VERSION "HNPBNNNYNNNNNNNNNNNNNNNNNNNNNNNNYNYYYYYYYY>4>%%%/4>'%**4YYY///"

NS_ :

BS_:

BU_: TESTER TCU BMU2 CSM CMU_TEST CMU_12 CMU_11 CMU_10 CMU_09 CMU_08 CMU_07 CMU_06 CMU_05 CMU_04 CMU_03 CMU_02 CMU_01 CMU_00 BMU

BO_ 1713 CMU_RS1_11: 8 CMU_11
 SG_ MODULE_TEMP_06_11 : 56|8@1+ (1,-70) [-70|130] "°C"  TCU,BMU
 SG_ MODULE_TEMP_05_11 : 48|8@1+ (1,-70) [-70|130] "°C"  TCU,BMU2,BMU
 SG_ MODULE_TEMP_04_11 : 40|8@1+ (1,-70) [-70|130] "°C"  TCU,BMU2,BMU
 SG_ MODULE_TEMP_03_11 : 32|8@1+ (1,-70) [-70|130] "°C"  TCU,BMU2,BMU
 SG_ MODULE_TEMP_02_11 : 24|8@1+ (1,-70) [-70|130] "°C"  TCU,BMU2,BMU
 SG_ MODULE_TEMP_01_11 : 16|8@1+ (1,-70) [-70|130] "°C"  TCU,BMU2,BMU
 SG_ NUM_TABLE_VALUE_11 : 12|4@1+ (1,0) [0|0] ""  BMU
 SG_ BLC_DRV_STAT_12_11 : 11|1@1+ (1,0) [0|0] ""  TCU,BMU
 SG_ BLC_DRV_STAT_11_11 : 10|1@1+ (1,0) [0|0] ""  TCU,BMU
 SG_ BLC_DRV_STAT_10_11 : 9|1@1+ (1,0) [0|0] ""  TCU,BMU
 SG_ BLC_DRV_STAT_09_11 : 8|1@1+ (1,0) [0|0] ""  TCU,BMU
 SG_ BLC_DRV_STAT_08_11 : 7|1@1+ (1,0) [0|0] ""  TCU,BMU
 SG_ BLC_DRV_STAT_07_11 : 6|1@1+ (1,0) [0|0] ""  TCU,BMU
 SG_ BLC_DRV_STAT_06_11 : 5|1@1+ (1,0) [0|0] ""  TCU,BMU
 SG_ BLC_DRV_STAT_05_11 : 4|1@1+ (1,0) [0|0] ""  TCU,BMU
 SG_ BLC_DRV_STAT_04_11 : 3|1@1+ (1,0) [0|0] ""  TCU,BMU
 SG_ BLC_DRV_STAT_03_11 : 2|1@1+ (1,0) [0|0] ""  TCU,BMU
 SG_ BLC_DRV_STAT_02_11 : 1|1@1+ (1,0) [0|0] ""  TCU,BMU
 SG_ BLC_DRV_STAT_01_11 : 0|1@1+ (1,0) [0|0] ""  TCU,BMU

BO_ 1697 CMU_RS1_10: 8 CMU_10
 SG_ MODULE_TEMP_06_10 : 56|8@1+ (1,-70) [-70|130] "°C"  TCU,BMU
 SG_ MODULE_TEMP_05_10 : 48|8@1+ (1,-70) [-70|130] "°C"  TCU,BMU2,BMU
 SG_ MODULE_TEMP_04_10 : 40|8@1+ (1,-70) [-70|130] "°C"  TCU,BMU2,BMU
 SG_ MODULE_TEMP_03_10 : 32|8@1+ (1,-70) [-70|130] "°C"  TCU,BMU2,BMU
 SG_ MODULE_TEMP_02_10 : 24|8@1+ (1,-70) [-70|130] "°C"  TCU,BMU2,BMU
 SG_ MODULE_TEMP_01_10 : 16|8@1+ (1,-70) [-70|130] "°C"  TCU,BMU2,BMU
 SG_ NUM_TABLE_VALUE_10 : 12|4@1+ (1,0) [0|0] ""  BMU
 SG_ BLC_DRV_STAT_12_10 : 11|1@1+ (1,0) [0|0] ""  TCU,BMU
 SG_ BLC_DRV_STAT_11_10 : 10|1@1+ (1,0) [0|0] ""  TCU,BMU
 SG_ BLC_DRV_STAT_10_10 : 9|1@1+ (1,0) [0|0] ""  TCU,BMU
 SG_ BLC_DRV_STAT_09_10 : 8|1@1+ (1,0) [0|0] ""  TCU,BMU
 SG_ BLC_DRV_STAT_08_10 : 7|1@1+ (1,0) [0|0] ""  TCU,BMU
 SG_ BLC_DRV_STAT_07_10 : 6|1@1+ (1,0) [0|0] ""  TCU,BMU
 SG_ BLC_DRV_STAT_06_10 : 5|1@1+ (1,0) [0|0] ""  TCU,BMU
 SG_ BLC_DRV_STAT_05_10 : 4|1@1+ (1,0) [0|0] ""  TCU,BMU
 SG_ BLC_DRV_STAT_04_10 : 3|1@1+ (1,0) [0|0] ""  TCU,BMU
 SG_ BLC_DRV_STAT_03_10 : 2|1@1+ (1,0) [0|0] ""  TCU,BMU
 SG_ BLC_DRV_STAT_02_10 : 1|1@1+ (1,0) [0|0] ""  TCU,BMU
 SG_ BLC_DRV_STAT_01_10 : 0|1@1+ (1,0) [0|0] ""  TCU,BMU

BO_ 1681 CMU_RS1_09: 8 CMU_09
 SG_ MODULE_TEMP_06_09 : 56|8@1+ (1,-70) [-70|130] "°C"  TCU,BMU
 SG_ MODULE_TEMP_05_09 : 48|8@1+ (1,-70) [-70|130] "°C"  TCU,BMU2,BMU
 SG_ MODULE_TEMP_04_09 : 40|8@1+ (1,-70) [-70|130] "°C"  TCU,BMU2,BMU
 SG_ MODULE_TEMP_03_09 : 32|8@1+ (1,-70) [-70|130] "°C"  TCU,BMU2,BMU
 SG_ MODULE_TEMP_02_09 : 24|8@1+ (1,-70) [-70|130] "°C"  TCU,BMU2,BMU
 SG_ MODULE_TEMP_01_09 : 16|8@1+ (1,-70) [-70|130] "°C"  TCU,BMU2,BMU
 SG_ NUM_TABLE_VALUE_09 : 12|4@1+ (1,0) [0|0] ""  BMU
 SG_ BLC_DRV_STAT_12_09 : 11|1@1+ (1,0) [0|0] ""  TCU,BMU
 SG_ BLC_DRV_STAT_11_09 : 10|1@1+ (1,0) [0|0] ""  TCU,BMU
 SG_ BLC_DRV_STAT_10_09 : 9|1@1+ (1,0) [0|0] ""  TCU,BMU
 SG_ BLC_DRV_STAT_09_09 : 8|1@1+ (1,0) [0|0] ""  TCU,BMU
 SG_ BLC_DRV_STAT_08_09 : 7|1@1+ (1,0) [0|0] ""  TCU,BMU
 SG_ BLC_DRV_STAT_07_09 : 6|1@1+ (1,0) [0|0] ""  TCU,BMU
 SG_ BLC_DRV_STAT_06_09 : 5|1@1+ (1,0) [0|0] ""  TCU,BMU
 SG_ BLC_DRV_STAT_05_09 : 4|1@1+ (1,0) [0|0] ""  TCU,BMU
 SG_ BLC_DRV_STAT_04_09 : 3|1@1+ (1,0) [0|0] ""  TCU,BMU
 SG_ BLC_DRV_STAT_03_09 : 2|1@1+ (1,0) [0|0] ""  TCU,BMU
 SG_ BLC_DRV_STAT_02_09 : 1|1@1+ (1,0) [0|0] ""  TCU,BMU
 SG_ BLC_DRV_STAT_01_09 : 0|1@1+ (1,0) [0|0] ""  TCU,BMU

BO_ 1665 CMU_RS1_08: 8 CMU_08
 SG_ MODULE_TEMP_06_08 : 56|8@1+ (1,-70) [-70|130] "°C"  TCU,BMU
 SG_ MODULE_TEMP_05_08 : 48|8@1+ (1,-70) [-70|130] "°C"  TCU,BMU2,BMU
 SG_ MODULE_TEMP_04_08 : 40|8@1+ (1,-70) [-70|130] "°C"  TCU,BMU2,BMU
 SG_ MODULE_TEMP_03_08 : 32|8@1+ (1,-70) [-70|130] "°C"  TCU,BMU2,BMU
 SG_ MODULE_TEMP_02_08 : 24|8@1+ (1,-70) [-70|130] "°C"  TCU,BMU2,BMU
 SG_ MODULE_TEMP_01_08 : 16|8@1+ (1,-70) [-70|130] "°C"  TCU,BMU2,BMU
 SG_ NUM_TABLE_VALUE_08 : 12|4@1+ (1,0) [0|0] ""  BMU
 SG_ BLC_DRV_STAT_12_08 : 11|1@1+ (1,0) [0|0] ""  TCU,BMU
 SG_ BLC_DRV_STAT_11_08 : 10|1@1+ (1,0) [0|0] ""  TCU,BMU
 SG_ BLC_DRV_STAT_10_08 : 9|1@1+ (1,0) [0|0] ""  TCU,BMU
 SG_ BLC_DRV_STAT_09_08 : 8|1@1+ (1,0) [0|0] ""  TCU,BMU
 SG_ BLC_DRV_STAT_08_08 : 7|1@1+ (1,0) [0|0] ""  TCU,BMU
 SG_ BLC_DRV_STAT_07_08 : 6|1@1+ (1,0) [0|0] ""  TCU,BMU
 SG_ BLC_DRV_STAT_06_08 : 5|1@1+ (1,0) [0|0] ""  TCU,BMU
 SG_ BLC_DRV_STAT_05_08 : 4|1@1+ (1,0) [0|0] ""  TCU,BMU
 SG_ BLC_DRV_STAT_04_08 : 3|1@1+ (1,0) [0|0] ""  TCU,BMU
 SG_ BLC_DRV_STAT_03_08 : 2|1@1+ (1,0) [0|0] ""  TCU,BMU
 SG_ BLC_DRV_STAT_02_08 : 1|1@1+ (1,0) [0|0] ""  TCU,BMU
 SG_ BLC_DRV_STAT_01_08 : 0|1@1+ (1,0) [0|0] ""  TCU,BMU

BO_ 1649 CMU_RS1_07: 8 CMU_07
 SG_ MODULE_TEMP_06_07 : 56|8@1+ (1,-70) [-70|130] "°C"  TCU,BMU
 SG_ MODULE_TEMP_05_07 : 48|8@1+ (1,-70) [-70|130] "°C"  TCU,BMU2,BMU
 SG_ MODULE_TEMP_04_07 : 40|8@1+ (1,-70) [-70|130] "°C"  TCU,BMU2,BMU
 SG_ MODULE_TEMP_03_07 : 32|8@1+ (1,-70) [-70|130] "°C"  TCU,BMU2,BMU
 SG_ MODULE_TEMP_02_07 : 24|8@1+ (1,-70) [-70|130] "°C"  TCU,BMU2,BMU
 SG_ MODULE_TEMP_01_07 : 16|8@1+ (1,-70) [-70|130] "°C"  TCU,BMU2,BMU
 SG_ NUM_TABLE_VALUE_07 : 12|4@1+ (1,0) [0|0] ""  BMU
 SG_ BLC_DRV_STAT_12_07 : 11|1@1+ (1,0) [0|0] ""  TCU,BMU
 SG_ BLC_DRV_STAT_11_07 : 10|1@1+ (1,0) [0|0] ""  TCU,BMU
 SG_ BLC_DRV_STAT_10_07 : 9|1@1+ (1,0) [0|0] ""  TCU,BMU
 SG_ BLC_DRV_STAT_09_07 : 8|1@1+ (1,0) [0|0] ""  TCU,BMU
 SG_ BLC_DRV_STAT_08_07 : 7|1@1+ (1,0) [0|0] ""  TCU,BMU
 SG_ BLC_DRV_STAT_07_07 : 6|1@1+ (1,0) [0|0] ""  TCU,BMU
 SG_ BLC_DRV_STAT_06_07 : 5|1@1+ (1,0) [0|0] ""  TCU,BMU
 SG_ BLC_DRV_STAT_05_07 : 4|1@1+ (1,0) [0|0] ""  TCU,BMU
 SG_ BLC_DRV_STAT_04_07 : 3|1@1+ (1,0) [0|0] ""  TCU,BMU
 SG_ BLC_DRV_STAT_03_07 : 2|1@1+ (1,0) [0|0] ""  TCU,BMU
 SG_ BLC_DRV_STAT_02_07 : 1|1@1+ (1,0) [0|0] ""  TCU,BMU
 SG_ BLC_DRV_STAT_01_07 : 0|1@1+ (1,0) [0|0] ""  TCU,BMU

BO_ 1633 CMU_RS1_06: 8 CMU_06
 SG_ MODULE_TEMP_06_06 : 56|8@1+ (1,-70) [-70|130] "°C"  TCU,BMU
 SG_ MODULE_TEMP_05_06 : 48|8@1+ (1,-70) [-70|130] "°C"  TCU,BMU
 SG_ MODULE_TEMP_04_06 : 40|8@1+ (1,-70) [-70|130] "°C"  TCU,BMU
 SG_ MODULE_TEMP_03_06 : 32|8@1+ (1,-70) [-70|130] "°C"  TCU,BMU
 SG_ MODULE_TEMP_02_06 : 24|8@1+ (1,-70) [-70|130] "°C"  TCU,BMU
 SG_ MODULE_TEMP_01_06 : 16|8@1+ (1,-70) [-70|130] "°C"  TCU,BMU
 SG_ NUM_TABLE_VALUE_06 : 12|4@1+ (1,0) [0|0] ""  BMU
 SG_ BLC_DRV_STAT_12_06 : 11|1@1+ (1,0) [0|0] ""  TCU,BMU
 SG_ BLC_DRV_STAT_11_06 : 10|1@1+ (1,0) [0|0] ""  TCU,BMU
 SG_ BLC_DRV_STAT_10_06 : 9|1@1+ (1,0) [0|0] ""  TCU,BMU
 SG_ BLC_DRV_STAT_09_06 : 8|1@1+ (1,0) [0|0] ""  TCU,BMU
 SG_ BLC_DRV_STAT_08_06 : 7|1@1+ (1,0) [0|0] ""  TCU,BMU
 SG_ BLC_DRV_STAT_07_06 : 6|1@1+ (1,0) [0|0] ""  TCU,BMU
 SG_ BLC_DRV_STAT_06_06 : 5|1@1+ (1,0) [0|0] ""  TCU,BMU
 SG_ BLC_DRV_STAT_05_06 : 4|1@1+ (1,0) [0|0] ""  TCU,BMU
 SG_ BLC_DRV_STAT_04_06 : 3|1@1+ (1,0) [0|0] ""  TCU,BMU
 SG_ BLC_DRV_STAT_03_06 : 2|1@1+ (1,0) [0|0] ""  TCU,BMU
 SG_ BLC_DRV_STAT_02_06 : 1|1@1+ (1,0) [0|0] ""  TCU,BMU
 SG_ BLC_DRV_STAT_01_06 : 0|1@1+ (1,0) [0|0] ""  TCU,BMU

BO_ 1617 CMU_RS1_05: 8 CMU_05
 SG_ MODULE_TEMP_06_05 : 56|8@1+ (1,-70) [-70|130] "°C"  TCU,BMU
 SG_ MODULE_TEMP_05_05 : 48|8@1+ (1,-70) [-70|130] "°C"  TCU,BMU2,BMU
 SG_ MODULE_TEMP_04_05 : 40|8@1+ (1,-70) [-70|130] "°C"  TCU,BMU2,BMU
 SG_ MODULE_TEMP_03_05 : 32|8@1+ (1,-70) [-70|130] "°C"  TCU,BMU2,BMU
 SG_ MODULE_TEMP_02_05 : 24|8@1+ (1,-70) [-70|130] "°C"  TCU,BMU2,BMU
 SG_ MODULE_TEMP_01_05 : 16|8@1+ (1,-70) [-70|130] "°C"  TCU,BMU2,BMU
 SG_ NUM_TABLE_VALUE_05 : 12|4@1+ (1,0) [0|0] ""  BMU
 SG_ BLC_DRV_STAT_12_05 : 11|1@1+ (1,0) [0|0] ""  TCU,BMU
 SG_ BLC_DRV_STAT_11_05 : 10|1@1+ (1,0) [0|0] ""  TCU,BMU
 SG_ BLC_DRV_STAT_10_05 : 9|1@1+ (1,0) [0|0] ""  TCU,BMU
 SG_ BLC_DRV_STAT_09_05 : 8|1@1+ (1,0) [0|0] ""  TCU,BMU
 SG_ BLC_DRV_STAT_08_05 : 7|1@1+ (1,0) [0|0] ""  TCU,BMU
 SG_ BLC_DRV_STAT_07_05 : 6|1@1+ (1,0) [0|0] ""  TCU,BMU
 SG_ BLC_DRV_STAT_06_05 : 5|1@1+ (1,0) [0|0] ""  TCU,BMU
 SG_ BLC_DRV_STAT_05_05 : 4|1@1+ (1,0) [0|0] ""  TCU,BMU
 SG_ BLC_DRV_STAT_04_05 : 3|1@1+ (1,0) [0|0] ""  TCU,BMU
 SG_ BLC_DRV_STAT_03_05 : 2|1@1+ (1,0) [0|0] ""  TCU,BMU
 SG_ BLC_DRV_STAT_02_05 : 1|1@1+ (1,0) [0|0] ""  TCU,BMU
 SG_ BLC_DRV_STAT_01_05 : 0|1@1+ (1,0) [0|0] ""  TCU,BMU

BO_ 1601 CMU_RS1_04: 8 CMU_04
 SG_ MODULE_TEMP_06_04 : 56|8@1+ (1,-70) [-70|130] "°C"  TCU,BMU
 SG_ MODULE_TEMP_05_04 : 48|8@1+ (1,-70) [-70|130] "°C"  TCU,BMU2,BMU
 SG_ MODULE_TEMP_04_04 : 40|8@1+ (1,-70) [-70|130] "°C"  TCU,BMU2,BMU
 SG_ MODULE_TEMP_03_04 : 32|8@1+ (1,-70) [-70|130] "°C"  TCU,BMU2,BMU
 SG_ MODULE_TEMP_02_04 : 24|8@1+ (1,-70) [-70|130] "°C"  TCU,BMU2,BMU
 SG_ MODULE_TEMP_01_04 : 16|8@1+ (1,-70) [-70|130] "°C"  TCU,BMU2,BMU
 SG_ NUM_TABLE_VALUE_04 : 12|4@1+ (1,0) [0|0] ""  BMU
 SG_ BLC_DRV_STAT_12_04 : 11|1@1+ (1,0) [0|0] ""  TCU,BMU
 SG_ BLC_DRV_STAT_11_04 : 10|1@1+ (1,0) [0|0] ""  TCU,BMU
 SG_ BLC_DRV_STAT_10_04 : 9|1@1+ (1,0) [0|0] ""  TCU,BMU
 SG_ BLC_DRV_STAT_09_04 : 8|1@1+ (1,0) [0|0] ""  TCU,BMU
 SG_ BLC_DRV_STAT_08_04 : 7|1@1+ (1,0) [0|0] ""  TCU,BMU
 SG_ BLC_DRV_STAT_07_04 : 6|1@1+ (1,0) [0|0] ""  TCU,BMU
 SG_ BLC_DRV_STAT_06_04 : 5|1@1+ (1,0) [0|0] ""  TCU,BMU
 SG_ BLC_DRV_STAT_05_04 : 4|1@1+ (1,0) [0|0] ""  TCU,BMU
 SG_ BLC_DRV_STAT_04_04 : 3|1@1+ (1,0) [0|0] ""  TCU,BMU
 SG_ BLC_DRV_STAT_03_04 : 2|1@1+ (1,0) [0|0] ""  TCU,BMU
 SG_ BLC_DRV_STAT_02_04 : 1|1@1+ (1,0) [0|0] ""  TCU,BMU
 SG_ BLC_DRV_STAT_01_04 : 0|1@1+ (1,0) [0|0] ""  TCU,BMU

BO_ 1585 CMU_RS1_03: 8 CMU_03
 SG_ MODULE_TEMP_06_03 : 56|8@1+ (1,-70) [-70|130] "°C"  TCU,BMU
 SG_ MODULE_TEMP_05_03 : 48|8@1+ (1,-70) [-70|130] "°C"  TCU,BMU2,BMU
 SG_ MODULE_TEMP_04_03 : 40|8@1+ (1,-70) [-70|130] "°C"  TCU,BMU2,BMU
 SG_ MODULE_TEMP_03_03 : 32|8@1+ (1,-70) [-70|130] "°C"  TCU,BMU2,BMU
 SG_ MODULE_TEMP_02_03 : 24|8@1+ (1,-70) [-70|130] "°C"  TCU,BMU2,BMU
 SG_ MODULE_TEMP_01_03 : 16|8@1+ (1,-70) [-70|130] "°C"  TCU,BMU2,BMU
 SG_ NUM_TABLE_VALUE_03 : 12|4@1+ (1,0) [0|0] ""  BMU
 SG_ BLC_DRV_STAT_12_03 : 11|1@1+ (1,0) [0|0] ""  TCU,BMU
 SG_ BLC_DRV_STAT_11_03 : 10|1@1+ (1,0) [0|0] ""  TCU,BMU
 SG_ BLC_DRV_STAT_10_03 : 9|1@1+ (1,0) [0|0] ""  TCU,BMU
 SG_ BLC_DRV_STAT_09_03 : 8|1@1+ (1,0) [0|0] ""  TCU,BMU
 SG_ BLC_DRV_STAT_08_03 : 7|1@1+ (1,0) [0|0] ""  TCU,BMU
 SG_ BLC_DRV_STAT_07_03 : 6|1@1+ (1,0) [0|0] ""  TCU,BMU
 SG_ BLC_DRV_STAT_06_03 : 5|1@1+ (1,0) [0|0] ""  TCU,BMU
 SG_ BLC_DRV_STAT_05_03 : 4|1@1+ (1,0) [0|0] ""  TCU,BMU
 SG_ BLC_DRV_STAT_04_03 : 3|1@1+ (1,0) [0|0] ""  TCU,BMU
 SG_ BLC_DRV_STAT_03_03 : 2|1@1+ (1,0) [0|0] ""  TCU,BMU
 SG_ BLC_DRV_STAT_02_03 : 1|1@1+ (1,0) [0|0] ""  TCU,BMU
 SG_ BLC_DRV_STAT_01_03 : 0|1@1+ (1,0) [0|0] ""  TCU,BMU

BO_ 1569 CMU_RS1_02: 8 CMU_02
 SG_ MODULE_TEMP_06_02 : 56|8@1+ (1,-70) [-70|130] "°C"  TCU,BMU
 SG_ MODULE_TEMP_05_02 : 48|8@1+ (1,-70) [-70|130] "°C"  TCU,BMU2,BMU
 SG_ MODULE_TEMP_04_02 : 40|8@1+ (1,-70) [-70|130] "°C"  TCU,BMU2,BMU
 SG_ MODULE_TEMP_03_02 : 32|8@1+ (1,-70) [-70|130] "°C"  TCU,BMU2,BMU
 SG_ MODULE_TEMP_02_02 : 24|8@1+ (1,-70) [-70|130] "°C"  TCU,BMU2,BMU
 SG_ MODULE_TEMP_01_02 : 16|8@1+ (1,-70) [-70|130] "°C"  TCU,BMU2,BMU
 SG_ NUM_TABLE_VALUE_02 : 12|4@1+ (1,0) [0|0] ""  BMU
 SG_ BLC_DRV_STAT_12_02 : 11|1@1+ (1,0) [0|0] ""  TCU,BMU
 SG_ BLC_DRV_STAT_11_02 : 10|1@1+ (1,0) [0|0] ""  TCU,BMU
 SG_ BLC_DRV_STAT_10_02 : 9|1@1+ (1,0) [0|0] ""  TCU,BMU
 SG_ BLC_DRV_STAT_09_02 : 8|1@1+ (1,0) [0|0] ""  TCU,BMU
 SG_ BLC_DRV_STAT_08_02 : 7|1@1+ (1,0) [0|0] ""  TCU,BMU
 SG_ BLC_DRV_STAT_07_02 : 6|1@1+ (1,0) [0|0] ""  TCU,BMU
 SG_ BLC_DRV_STAT_06_02 : 5|1@1+ (1,0) [0|0] ""  TCU,BMU
 SG_ BLC_DRV_STAT_05_02 : 4|1@1+ (1,0) [0|0] ""  TCU,BMU
 SG_ BLC_DRV_STAT_04_02 : 3|1@1+ (1,0) [0|0] ""  TCU,BMU
 SG_ BLC_DRV_STAT_03_02 : 2|1@1+ (1,0) [0|0] ""  TCU,BMU
 SG_ BLC_DRV_STAT_02_02 : 1|1@1+ (1,0) [0|0] ""  TCU,BMU
 SG_ BLC_DRV_STAT_01_02 : 0|1@1+ (1,0) [0|0] ""  TCU,BMU

BO_ 1553 CMU_RS1_01: 8 CMU_01
 SG_ MODULE_TEMP_06_01 : 56|8@1+ (1,-70) [-70|130] "°C"  TCU,BMU
 SG_ MODULE_TEMP_05_01 : 48|8@1+ (1,-70) [-70|130] "°C"  TCU,BMU2,BMU
 SG_ MODULE_TEMP_04_01 : 40|8@1+ (1,-70) [-70|130] "°C"  TCU,BMU2,BMU
 SG_ MODULE_TEMP_03_01 : 32|8@1+ (1,-70) [-70|130] "°C"  TCU,BMU2,BMU
 SG_ MODULE_TEMP_02_01 : 24|8@1+ (1,-70) [-70|130] "°C"  TCU,BMU2,BMU
 SG_ MODULE_TEMP_01_01 : 16|8@1+ (1,-70) [-70|130] "°C"  TCU,BMU2,BMU
 SG_ NUM_TABLE_VALUE_01 : 12|4@1+ (1,0) [0|0] ""  BMU
 SG_ BLC_DRV_STAT_12_01 : 11|1@1+ (1,0) [0|0] ""  TCU,BMU
 SG_ BLC_DRV_STAT_11_01 : 10|1@1+ (1,0) [0|0] ""  TCU,BMU
 SG_ BLC_DRV_STAT_10_01 : 9|1@1+ (1,0) [0|0] ""  TCU,BMU
 SG_ BLC_DRV_STAT_09_01 : 8|1@1+ (1,0) [0|0] ""  TCU,BMU
 SG_ BLC_DRV_STAT_08_01 : 7|1@1+ (1,0) [0|0] ""  TCU,BMU
 SG_ BLC_DRV_STAT_07_01 : 6|1@1+ (1,0) [0|0] ""  TCU,BMU
 SG_ BLC_DRV_STAT_06_01 : 5|1@1+ (1,0) [0|0] ""  TCU,BMU
 SG_ BLC_DRV_STAT_05_01 : 4|1@1+ (1,0) [0|0] ""  TCU,BMU
 SG_ BLC_DRV_STAT_04_01 : 3|1@1+ (1,0) [0|0] ""  TCU,BMU
 SG_ BLC_DRV_STAT_03_01 : 2|1@1+ (1,0) [0|0] ""  TCU,BMU
 SG_ BLC_DRV_STAT_02_01 : 1|1@1+ (1,0) [0|0] ""  TCU,BMU
 SG_ BLC_DRV_STAT_01_01 : 0|1@1+ (1,0) [0|0] ""  TCU,BMU

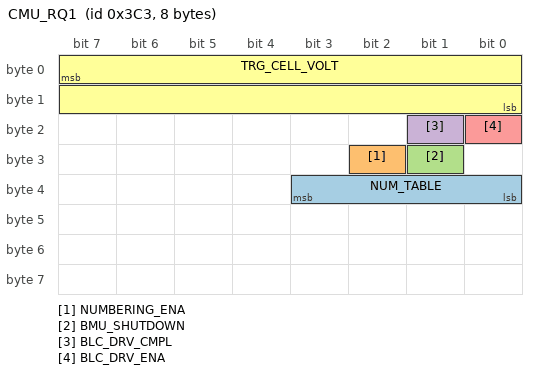
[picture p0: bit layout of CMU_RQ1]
BO_ 963 CMU_RQ1: 8 BMU
 SG_ NUM_TABLE : 32|4@1+ (1,0) [0|0] ""  CMU_00,CMU_12,CMU_11,CMU_10,CMU_09,CMU_08,CMU_07,CMU_06,CMU_05,CMU_04,CMU_03,CMU_02,CMU_01
 SG_ NUMBERING_ENA : 26|1@1+ (1,0) [0|0] ""  CMU_00,CMU_12,CMU_11,CMU_10,CMU_09,CMU_08,CMU_07,CMU_06,CMU_05,CMU_04,CMU_03,CMU_02,CMU_01
 SG_ BMU_SHUTDOWN : 25|1@1+ (1,0) [0|0] ""  TCU,CMU_12,CMU_11,CMU_10,CMU_09,CMU_08,CMU_07,CMU_06,CMU_05,CMU_04,CMU_03,CMU_02,CMU_01
 SG_ BLC_DRV_CMPL : 17|1@1+ (1,0) [0|0] ""  TCU,CMU_12,CMU_11,CMU_10,CMU_09,CMU_08,CMU_07,CMU_06,CMU_05,CMU_04,CMU_03,CMU_02,CMU_01
 SG_ BLC_DRV_ENA : 16|1@1+ (1,0) [0|0] ""  TCU,CMU_12,CMU_11,CMU_10,CMU_09,CMU_08,CMU_07,CMU_06,CMU_05,CMU_04,CMU_03,CMU_02,CMU_01
 SG_ TRG_CELL_VOLT : 7|16@0+ (0.001,0) [0|5] "V"  TCU,CMU_12,CMU_11,CMU_10,CMU_09,CMU_08,CMU_07,CMU_06,CMU_05,CMU_04,CMU_03,CMU_02,CMU_01

CM_ SG_ 1713 MODULE_TEMP_06_11 "Module temperature06";
CM_ SG_ 1713 MODULE_TEMP_05_11 "Module temperature05";
CM_ SG_ 1713 MODULE_TEMP_04_11 "Module temperature04";
CM_ SG_ 1713 MODULE_TEMP_03_11 "Module temperature03";
CM_ SG_ 1713 MODULE_TEMP_02_11 "Module temperature02";
CM_ SG_ 1713 MODULE_TEMP_01_11 "Module temperature01";
CM_ SG_ 1713 NUM_TABLE_VALUE_11 "Stored Automatic numbering table";
CM_ SG_ 1713 BLC_DRV_STAT_12_11 "CELL_12 Balancer drive status";
CM_ SG_ 1713 BLC_DRV_STAT_11_11 "CELL_11 Balancer drive status";
CM_ SG_ 1713 BLC_DRV_STAT_10_11 "CELL_10 Balancer drive status";
CM_ SG_ 1713 BLC_DRV_STAT_09_11 "CELL_09 Balancer drive status";
CM_ SG_ 1713 BLC_DRV_STAT_08_11 "CELL_08 Balancer drive status";
CM_ SG_ 1713 BLC_DRV_STAT_07_11 "CELL_07 Balancer drive status";
CM_ SG_ 1713 BLC_DRV_STAT_06_11 "CELL_06 Balancer drive status";
CM_ SG_ 1713 BLC_DRV_STAT_05_11 "CELL_05 Balancer drive status";
CM_ SG_ 1713 BLC_DRV_STAT_04_11 "CELL_04 Balancer drive status";
CM_ SG_ 1713 BLC_DRV_STAT_03_11 "CELL_03 Balancer drive status";
CM_ SG_ 1713 BLC_DRV_STAT_02_11 "CELL_02 Balancer drive status";
CM_ SG_ 1713 BLC_DRV_STAT_01_11 "CELL_01 Balancer drive status";
CM_ SG_ 1697 MODULE_TEMP_06_10 "Module temperature06";
CM_ SG_ 1697 MODULE_TEMP_05_10 "Module temperature05";
CM_ SG_ 1697 MODULE_TEMP_04_10 "Module temperature04";
CM_ SG_ 1697 MODULE_TEMP_03_10 "Module temperature03";
CM_ SG_ 1697 MODULE_TEMP_02_10 "Module temperature02";
CM_ SG_ 1697 MODULE_TEMP_01_10 "Module temperature01";
CM_ SG_ 1697 NUM_TABLE_VALUE_10 "Stored Automatic numbering table";
CM_ SG_ 1697 BLC_DRV_STAT_12_10 "CELL_12 Balancer drive status";
CM_ SG_ 1697 BLC_DRV_STAT_11_10 "CELL_11 Balancer drive status";
CM_ SG_ 1697 BLC_DRV_STAT_10_10 "CELL_10 Balancer drive status";
CM_ SG_ 1697 BLC_DRV_STAT_09_10 "CELL_09 Balancer drive status";
CM_ SG_ 1697 BLC_DRV_STAT_08_10 "CELL_08 Balancer drive status";
CM_ SG_ 1697 BLC_DRV_STAT_07_10 "CELL_07 Balancer drive status";
CM_ SG_ 1697 BLC_DRV_STAT_06_10 "CELL_06 Balancer drive status";
CM_ SG_ 1697 BLC_DRV_STAT_05_10 "CELL_05 Balancer drive status";
CM_ SG_ 1697 BLC_DRV_STAT_04_10 "CELL_04 Balancer drive status";
CM_ SG_ 1697 BLC_DRV_STAT_03_10 "CELL_03 Balancer drive status";
CM_ SG_ 1697 BLC_DRV_STAT_02_10 "CELL_02 Balancer drive status";
CM_ SG_ 1697 BLC_DRV_STAT_01_10 "CELL_01 Balancer drive status";
CM_ SG_ 1681 MODULE_TEMP_06_09 "Module temperature06";
CM_ SG_ 1681 MODULE_TEMP_05_09 "Module temperature05";
CM_ SG_ 1681 MODULE_TEMP_04_09 "Module temperature04";
CM_ SG_ 1681 MODULE_TEMP_03_09 "Module temperature03";
CM_ SG_ 1681 MODULE_TEMP_02_09 "Module temperature02";
CM_ SG_ 1681 MODULE_TEMP_01_09 "Module temperature01";
CM_ SG_ 1681 NUM_TABLE_VALUE_09 "Stored Automatic numbering table";
CM_ SG_ 1681 BLC_DRV_STAT_12_09 "CELL_12 Balancer drive status";
CM_ SG_ 1681 BLC_DRV_STAT_11_09 "CELL_11 Balancer drive status";
CM_ SG_ 1681 BLC_DRV_STAT_10_09 "CELL_10 Balancer drive status";
CM_ SG_ 1681 BLC_DRV_STAT_09_09 "CELL_09 Balancer drive status";
CM_ SG_ 1681 BLC_DRV_STAT_08_09 "CELL_08 Balancer drive status";
CM_ SG_ 1681 BLC_DRV_STAT_07_09 "CELL_07 Balancer drive status";
CM_ SG_ 1681 BLC_DRV_STAT_06_09 "CELL_06 Balancer drive status";
CM_ SG_ 1681 BLC_DRV_STAT_05_09 "CELL_05 Balancer drive status";
CM_ SG_ 1681 BLC_DRV_STAT_04_09 "CELL_04 Balancer drive status";
CM_ SG_ 1681 BLC_DRV_STAT_03_09 "CELL_03 Balancer drive status";
CM_ SG_ 1681 BLC_DRV_STAT_02_09 "CELL_02 Balancer drive status";
CM_ SG_ 1681 BLC_DRV_STAT_01_09 "CELL_01 Balancer drive status";
CM_ SG_ 1665 MODULE_TEMP_06_08 "Module temperature06";
CM_ SG_ 1665 MODULE_TEMP_05_08 "Module temperature05";
CM_ SG_ 1665 MODULE_TEMP_04_08 "Module temperature04";
CM_ SG_ 1665 MODULE_TEMP_03_08 "Module temperature03";
CM_ SG_ 1665 MODULE_TEMP_02_08 "Module temperature02";
CM_ SG_ 1665 MODULE_TEMP_01_08 "Module temperature01";
CM_ SG_ 1665 NUM_TABLE_VALUE_08 "Stored Automatic numbering table";
CM_ SG_ 1665 BLC_DRV_STAT_12_08 "CELL_12 Balancer drive status";
CM_ SG_ 1665 BLC_DRV_STAT_11_08 "CELL_11 Balancer drive status";
CM_ SG_ 1665 BLC_DRV_STAT_10_08 "CELL_10 Balancer drive status";
CM_ SG_ 1665 BLC_DRV_STAT_09_08 "CELL_09 Balancer drive status";
CM_ SG_ 1665 BLC_DRV_STAT_08_08 "CELL_08 Balancer drive status";
CM_ SG_ 1665 BLC_DRV_STAT_07_08 "CELL_07 Balancer drive status";
CM_ SG_ 1665 BLC_DRV_STAT_06_08 "CELL_06 Balancer drive status";
CM_ SG_ 1665 BLC_DRV_STAT_05_08 "CELL_05 Balancer drive status";
CM_ SG_ 1665 BLC_DRV_STAT_04_08 "CELL_04 Balancer drive status";
CM_ SG_ 1665 BLC_DRV_STAT_03_08 "CELL_03 Balancer drive status";
CM_ SG_ 1665 BLC_DRV_STAT_02_08 "CELL_02 Balancer drive status";
CM_ SG_ 1665 BLC_DRV_STAT_01_08 "CELL_01 Balancer drive status";
CM_ SG_ 1649 MODULE_TEMP_06_07 "Module temperature06";
CM_ SG_ 1649 MODULE_TEMP_05_07 "Module temperature05";
CM_ SG_ 1649 MODULE_TEMP_04_07 "Module temperature04";
CM_ SG_ 1649 MODULE_TEMP_03_07 "Module temperature03";
CM_ SG_ 1649 MODULE_TEMP_02_07 "Module temperature02";
CM_ SG_ 1649 MODULE_TEMP_01_07 "Module temperature01";
CM_ SG_ 1649 NUM_TABLE_VALUE_07 "Stored Automatic numbering table";
CM_ SG_ 1649 BLC_DRV_STAT_12_07 "CELL_12 Balancer drive status";
CM_ SG_ 1649 BLC_DRV_STAT_11_07 "CELL_11 Balancer drive status";
CM_ SG_ 1649 BLC_DRV_STAT_10_07 "CELL_10 Balancer drive status";
CM_ SG_ 1649 BLC_DRV_STAT_09_07 "CELL_09 Balancer drive status";
CM_ SG_ 1649 BLC_DRV_STAT_08_07 "CELL_08 Balancer drive status";
CM_ SG_ 1649 BLC_DRV_STAT_07_07 "CELL_07 Balancer drive status";
CM_ SG_ 1649 BLC_DRV_STAT_06_07 "CELL_06 Balancer drive status";
CM_ SG_ 1649 BLC_DRV_STAT_05_07 "CELL_05 Balancer drive status";
CM_ SG_ 1649 BLC_DRV_STAT_04_07 "CELL_04 Balancer drive status";
CM_ SG_ 1649 BLC_DRV_STAT_03_07 "CELL_03 Balancer drive status";
CM_ SG_ 1649 BLC_DRV_STAT_02_07 "CELL_02 Balancer drive status";
CM_ SG_ 1649 BLC_DRV_STAT_01_07 "CELL_01 Balancer drive status";
CM_ SG_ 1633 MODULE_TEMP_06_06 "Module temperature06";
CM_ SG_ 1633 MODULE_TEMP_05_06 "Module temperature05";
CM_ SG_ 1633 MODULE_TEMP_04_06 "Module temperature04";
CM_ SG_ 1633 MODULE_TEMP_03_06 "Module temperature03";
CM_ SG_ 1633 MODULE_TEMP_02_06 "Module temperature02";
CM_ SG_ 1633 MODULE_TEMP_01_06 "Module temperature01";
CM_ SG_ 1633 NUM_TABLE_VALUE_06 "Stored Automatic numbering table";
CM_ SG_ 1633 BLC_DRV_STAT_12_06 "CELL_12 Balancer drive status";
CM_ SG_ 1633 BLC_DRV_STAT_11_06 "CELL_11 Balancer drive status";
CM_ SG_ 1633 BLC_DRV_STAT_10_06 "CELL_10 Balancer drive status";
CM_ SG_ 1633 BLC_DRV_STAT_09_06 "CELL_09 Balancer drive status";
CM_ SG_ 1633 BLC_DRV_STAT_08_06 "CELL_08 Balancer drive status";
CM_ SG_ 1633 BLC_DRV_STAT_07_06 "CELL_07 Balancer drive status";
CM_ SG_ 1633 BLC_DRV_STAT_06_06 "CELL_06 Balancer drive status";
CM_ SG_ 1633 BLC_DRV_STAT_05_06 "CELL_05 Balancer drive status";
CM_ SG_ 1633 BLC_DRV_STAT_04_06 "CELL_04 Balancer drive status";
CM_ SG_ 1633 BLC_DRV_STAT_03_06 "CELL_03 Balancer drive status";
CM_ SG_ 1633 BLC_DRV_STAT_02_06 "CELL_02 Balancer drive status";
CM_ SG_ 1633 BLC_DRV_STAT_01_06 "CELL_01 Balancer drive status";
CM_ SG_ 1617 MODULE_TEMP_06_05 "Module temperature06";
CM_ SG_ 1617 MODULE_TEMP_05_05 "Module temperature05";
CM_ SG_ 1617 MODULE_TEMP_04_05 "Module temperature04";
CM_ SG_ 1617 MODULE_TEMP_03_05 "Module temperature03";
CM_ SG_ 1617 MODULE_TEMP_02_05 "Module temperature02";
CM_ SG_ 1617 MODULE_TEMP_01_05 "Module temperature01";
CM_ SG_ 1617 NUM_TABLE_VALUE_05 "Stored Automatic numbering table";
CM_ SG_ 1617 BLC_DRV_STAT_12_05 "CELL_12 Balancer drive status";
CM_ SG_ 1617 BLC_DRV_STAT_11_05 "CELL_11 Balancer drive status";
CM_ SG_ 1617 BLC_DRV_STAT_10_05 "CELL_10 Balancer drive status";
CM_ SG_ 1617 BLC_DRV_STAT_09_05 "CELL_09 Balancer drive status";
CM_ SG_ 1617 BLC_DRV_STAT_08_05 "CELL_08 Balancer drive status";
CM_ SG_ 1617 BLC_DRV_STAT_07_05 "CELL_07 Balancer drive status";
CM_ SG_ 1617 BLC_DRV_STAT_06_05 "CELL_06 Balancer drive status";
CM_ SG_ 1617 BLC_DRV_STAT_05_05 "CELL_05 Balancer drive status";
CM_ SG_ 1617 BLC_DRV_STAT_04_05 "CELL_04 Balancer drive status";
CM_ SG_ 1617 BLC_DRV_STAT_03_05 "CELL_03 Balancer drive status";
CM_ SG_ 1617 BLC_DRV_STAT_02_05 "CELL_02 Balancer drive status";
CM_ SG_ 1617 BLC_DRV_STAT_01_05 "CELL_01 Balancer drive status";
CM_ SG_ 1601 MODULE_TEMP_06_04 "Module temperature06";
CM_ SG_ 1601 MODULE_TEMP_05_04 "Module temperature05";
CM_ SG_ 1601 MODULE_TEMP_04_04 "Module temperature04";
CM_ SG_ 1601 MODULE_TEMP_03_04 "Module temperature03";
CM_ SG_ 1601 MODULE_TEMP_02_04 "Module temperature02";
CM_ SG_ 1601 MODULE_TEMP_01_04 "Module temperature01";
CM_ SG_ 1601 NUM_TABLE_VALUE_04 "Stored Automatic numbering table";
CM_ SG_ 1601 BLC_DRV_STAT_12_04 "CELL_12 Balancer drive status";
CM_ SG_ 1601 BLC_DRV_STAT_11_04 "CELL_11 Balancer drive status";
CM_ SG_ 1601 BLC_DRV_STAT_10_04 "CELL_10 Balancer drive status";
CM_ SG_ 1601 BLC_DRV_STAT_09_04 "CELL_09 Balancer drive statusl";
CM_ SG_ 1601 BLC_DRV_STAT_08_04 "CELL_08 Balancer drive status";
CM_ SG_ 1601 BLC_DRV_STAT_07_04 "CELL_07 Balancer drive status";
CM_ SG_ 1601 BLC_DRV_STAT_06_04 "CELL_06 Balancer drive status";
CM_ SG_ 1601 BLC_DRV_STAT_05_04 "CELL_05 Balancer drive status";
CM_ SG_ 1601 BLC_DRV_STAT_04_04 "CELL_04 Balancer drive status";
CM_ SG_ 1601 BLC_DRV_STAT_03_04 "CELL_03 Balancer drive status";
CM_ SG_ 1601 BLC_DRV_STAT_02_04 "CELL_02 Balancer drive status";
CM_ SG_ 1601 BLC_DRV_STAT_01_04 "CELL_01 Balancer drive status";
CM_ SG_ 1585 MODULE_TEMP_06_03 "Module temperature06";
CM_ SG_ 1585 MODULE_TEMP_05_03 "Module temperature05";
CM_ SG_ 1585 MODULE_TEMP_04_03 "Module temperature04";
CM_ SG_ 1585 MODULE_TEMP_03_03 "Module temperature03";
CM_ SG_ 1585 MODULE_TEMP_02_03 "Module temperature02";
CM_ SG_ 1585 MODULE_TEMP_01_03 "Module temperature01";
CM_ SG_ 1585 NUM_TABLE_VALUE_03 "Stored Automatic numbering table";
CM_ SG_ 1585 BLC_DRV_STAT_12_03 "CELL_12 Balancer drive status";
CM_ SG_ 1585 BLC_DRV_STAT_11_03 "CELL_11 Balancer drive status";
CM_ SG_ 1585 BLC_DRV_STAT_10_03 "CELL_10 Balancer drive status";
CM_ SG_ 1585 BLC_DRV_STAT_09_03 "CELL_09 Balancer drive status";
CM_ SG_ 1585 BLC_DRV_STAT_08_03 "CELL_08 Balancer drive status";
CM_ SG_ 1585 BLC_DRV_STAT_07_03 "CELL_07 Balancer drive status";
CM_ SG_ 1585 BLC_DRV_STAT_06_03 "CELL_06 Balancer drive status";
CM_ SG_ 1585 BLC_DRV_STAT_05_03 "CELL_05 Balancer drive status";
CM_ SG_ 1585 BLC_DRV_STAT_04_03 "CELL_04 Balancer drive status";
CM_ SG_ 1585 BLC_DRV_STAT_03_03 "CELL_03 Balancer drive status";
CM_ SG_ 1585 BLC_DRV_STAT_02_03 "CELL_02 Balancer drive status";
CM_ SG_ 1585 BLC_DRV_STAT_01_03 "CELL_01 Balancer drive status";
CM_ SG_ 1569 MODULE_TEMP_06_02 "Module temperature06";
CM_ SG_ 1569 MODULE_TEMP_05_02 "Module temperature05";
CM_ SG_ 1569 MODULE_TEMP_04_02 "Module temperature04";
CM_ SG_ 1569 MODULE_TEMP_03_02 "Module temperature03";
CM_ SG_ 1569 MODULE_TEMP_02_02 "Module temperature02";
CM_ SG_ 1569 MODULE_TEMP_01_02 "Module temperature01";
CM_ SG_ 1569 NUM_TABLE_VALUE_02 "Stored Automatic numbering table";
CM_ SG_ 1569 BLC_DRV_STAT_12_02 "CELL_12 Balancer drive status";
CM_ SG_ 1569 BLC_DRV_STAT_11_02 "CELL_11 Balancer drive status";
CM_ SG_ 1569 BLC_DRV_STAT_10_02 "CELL_10 Balancer drive status";
CM_ SG_ 1569 BLC_DRV_STAT_09_02 "CELL_09 Balancer drive status";
CM_ SG_ 1569 BLC_DRV_STAT_08_02 "CELL_08 Balancer drive status";
CM_ SG_ 1569 BLC_DRV_STAT_07_02 "CELL_07 Balancer drive status";
CM_ SG_ 1569 BLC_DRV_STAT_06_02 "CELL_06 Balancer drive status";
CM_ SG_ 1569 BLC_DRV_STAT_05_02 "CELL_05 Balancer drive status";
CM_ SG_ 1569 BLC_DRV_STAT_04_02 "CELL_04 Balancer drive status";
CM_ SG_ 1569 BLC_DRV_STAT_03_02 "CELL_03 Balancer drive status";
CM_ SG_ 1569 BLC_DRV_STAT_02_02 "CELL_02 Balancer drive status";
CM_ SG_ 1569 BLC_DRV_STAT_01_02 "CELL_01 Balancer drive status";
CM_ SG_ 1553 MODULE_TEMP_06_01 "Module temperature06";
CM_ SG_ 1553 MODULE_TEMP_05_01 "Module temperature05";
CM_ SG_ 1553 MODULE_TEMP_04_01 "Module temperature04";
CM_ SG_ 1553 MODULE_TEMP_03_01 "Module temperature03";
CM_ SG_ 1553 MODULE_TEMP_02_01 "Module temperature02";
CM_ SG_ 1553 MODULE_TEMP_01_01 "Module temperature01";
CM_ SG_ 1553 NUM_TABLE_VALUE_01 "Stored Automatic numbering table";
CM_ SG_ 1553 BLC_DRV_STAT_12_01 "CELL_12 Balancer drive status";
CM_ SG_ 1553 BLC_DRV_STAT_11_01 "CELL_11 Balancer drive status";
CM_ SG_ 1553 BLC_DRV_STAT_10_01 "CELL_10 Balancer drive status";
CM_ SG_ 1553 BLC_DRV_STAT_09_01 "CELL_09 Balancer drive status";
CM_ SG_ 1553 BLC_DRV_STAT_08_01 "CELL_08 Balancer drive status";
CM_ SG_ 1553 BLC_DRV_STAT_07_01 "CELL_07 Balancer drive status";
CM_ SG_ 1553 BLC_DRV_STAT_06_01 "CELL_06 Balancer drive status";
CM_ SG_ 1553 BLC_DRV_STAT_05_01 "CELL_05 Balancer drive status";
CM_ SG_ 1553 BLC_DRV_STAT_04_01 "CELL_04 Balancer drive status";
CM_ SG_ 1553 BLC_DRV_STAT_03_01 "CELL_03 Balancer drive status";
CM_ SG_ 1553 BLC_DRV_STAT_02_01 "CELL_02 Balancer drive status";
CM_ SG_ 1553 BLC_DRV_STAT_01_01 "CELL_01 Balancer drive status";
CM_ SG_ 963 NUM_TABLE "Automatic numbering table";
CM_ SG_ 963 NUMBERING_ENA "Automatic numbering enable";
CM_ SG_ 963 BMU_SHUTDOWN "BMU Shutdown";
CM_ SG_ 963 BLC_DRV_CMPL "Balancer drive compulsion";
CM_ SG_ 963 BLC_DRV_ENA "Balancer drive enable";
CM_ SG_ 963 TRG_CELL_VOLT "Target cell voltage";
BA_DEF_ SG_  "GenSigTimeout_CMU_00" INT 0 65535;
BA_DEF_ SG_  "GenSigTimeout_CMU_12" INT 0 65535;
BA_DEF_ SG_  "GenSigTimeout_CMU_11" INT 0 65535;
BA_DEF_ SG_  "GenSigTimeout_CMU_10" INT 0 65535;
BA_DEF_ SG_  "GenSigTimeout_CMU_09" INT 0 65535;
BA_DEF_ SG_  "GenSigTimeout_CMU_08" INT 0 65535;
BA_DEF_ SG_  "GenSigTimeout_CMU_07" INT 0 65535;
BA_DEF_ SG_  "GenSigTimeout_CMU_06" INT 0 65535;
BA_DEF_ SG_  "GenSigTimeout_CMU_05" INT 0 65535;
BA_DEF_ SG_  "GenSigTimeout_CMU_04" INT 0 65535;
BA_DEF_ SG_  "GenSigTimeout_CMU_03" INT 0 65535;
BA_DEF_ SG_  "GenSigTimeout_CMU_02" INT 0 65535;
BA_DEF_ SG_  "GenSigTimeout_CMU_01" INT 0 65535;
BA_DEF_ SG_  "GenSigTimeout_BMU" INT 0 65535;
BA_DEF_ SG_  "FlexKomIsMotorola" ENUM  "nein","ja";
BA_DEF_ SG_  "FlexKomSigLaenge" INT 0 64;
BA_DEF_ SG_  "FlexKomSigStartPos" INT 0 63;
BA_DEF_ SG_  "FlexKomComment" STRING ;
BA_DEF_ SG_  "FlexKomSigName" STRING ;
BA_DEF_ SG_  "FlexKomSID" INT 0 65535;
BA_DEF_ SG_  "GenSigStartValue" HEX 0 4294967295;
BA_DEF_ SG_  "FlexKomSigStartValue" STRING ;
BA_DEF_ SG_  "GenSigCycleTime" INT 0 65535;
BA_DEF_ SG_  "GenSigSendType" ENUM  "cyclicX","spontanX","cyclicIfActiveX","spontanWithDelay","cyclicAndSpontanX","cyclicAndSpontanWithDelay","spontanWithRepitition","cyclicIfActiveAndSpontanWD","cyclicIfActiveFast","cyclicWithRepeatOnDemand","none";
BA_DEF_ BO_  "GenMsgNrOfRepetitions" INT 0 65535;
BA_DEF_ BO_  "GenMsgDelayTime" INT 0 65535;
BA_DEF_ BO_  "GenMsgCycleTime" INT 0 65535;
BA_DEF_ BO_  "GenMsgSendType" ENUM  "cyclicX","spontanX","cyclicIfActiveX","spontanWithDelay","cyclicAndSpontanX","cyclicAndSpontanWithDelay","spontanWithRepitition","cyclicIfActiveAndSpontanWD","cyclicIfActiveFast","cyclicWithRepeatOnDemand","none";
BA_DEF_ BO_  "DiagResponse" ENUM  "nein","ja";
BA_DEF_ BO_  "DiagRequest" ENUM  "nein","ja";
BA_DEF_ BO_  "DiagState" ENUM  "nein","ja";
BA_DEF_ BO_  "App-Botschaft" ENUM  "nein","ja";
BA_DEF_ BO_  "NWM-Botschaft" ENUM  "nein","ja";
BA_DEF_DEF_  "GenSigTimeout_CMU_00" 0;
BA_DEF_DEF_  "GenSigTimeout_CMU_12" 0;
BA_DEF_DEF_  "GenSigTimeout_CMU_11" 0;
BA_DEF_DEF_  "GenSigTimeout_CMU_10" 0;
BA_DEF_DEF_  "GenSigTimeout_CMU_09" 0;
BA_DEF_DEF_  "GenSigTimeout_CMU_08" 0;
BA_DEF_DEF_  "GenSigTimeout_CMU_07" 0;
BA_DEF_DEF_  "GenSigTimeout_CMU_06" 0;
BA_DEF_DEF_  "GenSigTimeout_CMU_05" 0;
BA_DEF_DEF_  "GenSigTimeout_CMU_04" 0;
BA_DEF_DEF_  "GenSigTimeout_CMU_03" 0;
BA_DEF_DEF_  "GenSigTimeout_CMU_02" 0;
BA_DEF_DEF_  "GenSigTimeout_CMU_01" 0;
BA_DEF_DEF_  "GenSigTimeout_BMU" 0;
BA_DEF_DEF_  "FlexKomIsMotorola" "";
BA_DEF_DEF_  "FlexKomSigLaenge" 0;
BA_DEF_DEF_  "FlexKomSigStartPos" 0;
BA_DEF_DEF_  "FlexKomComment" "";
BA_DEF_DEF_  "FlexKomSigName" "";
BA_DEF_DEF_  "FlexKomSID" 0;
BA_DEF_DEF_  "GenSigStartValue" 0;
BA_DEF_DEF_  "FlexKomSigStartValue" "";
BA_DEF_DEF_  "GenSigCycleTime" 0;
BA_DEF_DEF_  "GenSigSendType" "";
BA_DEF_DEF_  "GenMsgNrOfRepetitions" 0;
BA_DEF_DEF_  "GenMsgDelayTime" 0;
BA_DEF_DEF_  "GenMsgCycleTime" 0;
BA_DEF_DEF_  "GenMsgSendType" "";
BA_DEF_DEF_  "DiagResponse" "";
BA_DEF_DEF_  "DiagRequest" "";
BA_DEF_DEF_  "DiagState" "";
BA_DEF_DEF_  "App-Botschaft" "";
BA_DEF_DEF_  "NWM-Botschaft" "";
BA_ "NWM-Botschaft" BO_ 1713 0;
BA_ "App-Botschaft" BO_ 1713 0;
BA_ "DiagState" BO_ 1713 0;
BA_ "DiagRequest" BO_ 1713 0;
BA_ "DiagResponse" BO_ 1713 0;
BA_ "GenMsgSendType" BO_ 1713 0;
BA_ "GenMsgCycleTime" BO_ 1713 40;
BA_ "GenMsgDelayTime" BO_ 1713 20;
BA_ "NWM-Botschaft" BO_ 1697 0;
BA_ "App-Botschaft" BO_ 1697 0;
BA_ "DiagState" BO_ 1697 0;
BA_ "DiagRequest" BO_ 1697 0;
BA_ "DiagResponse" BO_ 1697 0;
BA_ "GenMsgSendType" BO_ 1697 0;
BA_ "GenMsgCycleTime" BO_ 1697 40;
BA_ "GenMsgDelayTime" BO_ 1697 20;
BA_ "NWM-Botschaft" BO_ 1681 0;
BA_ "App-Botschaft" BO_ 1681 0;
BA_ "DiagState" BO_ 1681 0;
BA_ "DiagRequest" BO_ 1681 0;
BA_ "DiagResponse" BO_ 1681 0;
BA_ "GenMsgSendType" BO_ 1681 0;
BA_ "GenMsgCycleTime" BO_ 1681 40;
BA_ "GenMsgDelayTime" BO_ 1681 20;
BA_ "NWM-Botschaft" BO_ 1665 0;
BA_ "App-Botschaft" BO_ 1665 0;
BA_ "DiagState" BO_ 1665 0;
BA_ "DiagRequest" BO_ 1665 0;
BA_ "DiagResponse" BO_ 1665 0;
BA_ "GenMsgSendType" BO_ 1665 0;
BA_ "GenMsgCycleTime" BO_ 1665 40;
BA_ "GenMsgDelayTime" BO_ 1665 20;
BA_ "NWM-Botschaft" BO_ 1649 0;
BA_ "App-Botschaft" BO_ 1649 0;
BA_ "DiagState" BO_ 1649 0;
BA_ "DiagRequest" BO_ 1649 0;
BA_ "DiagResponse" BO_ 1649 0;
BA_ "GenMsgSendType" BO_ 1649 0;
BA_ "GenMsgCycleTime" BO_ 1649 40;
BA_ "GenMsgDelayTime" BO_ 1649 20;
BA_ "NWM-Botschaft" BO_ 1633 0;
BA_ "App-Botschaft" BO_ 1633 0;
BA_ "DiagState" BO_ 1633 0;
BA_ "DiagRequest" BO_ 1633 0;
BA_ "DiagResponse" BO_ 1633 0;
BA_ "GenMsgSendType" BO_ 1633 0;
BA_ "GenMsgCycleTime" BO_ 1633 40;
BA_ "GenMsgDelayTime" BO_ 1633 20;
BA_ "NWM-Botschaft" BO_ 1617 0;
BA_ "App-Botschaft" BO_ 1617 0;
BA_ "DiagState" BO_ 1617 0;
BA_ "DiagRequest" BO_ 1617 0;
BA_ "DiagResponse" BO_ 1617 0;
BA_ "GenMsgSendType" BO_ 1617 0;
BA_ "GenMsgCycleTime" BO_ 1617 40;
BA_ "GenMsgDelayTime" BO_ 1617 20;
BA_ "NWM-Botschaft" BO_ 1601 0;
BA_ "App-Botschaft" BO_ 1601 0;
BA_ "DiagState" BO_ 1601 0;
BA_ "DiagRequest" BO_ 1601 0;
BA_ "DiagResponse" BO_ 1601 0;
BA_ "GenMsgSendType" BO_ 1601 0;
BA_ "GenMsgCycleTime" BO_ 1601 40;
BA_ "GenMsgDelayTime" BO_ 1601 20;
BA_ "NWM-Botschaft" BO_ 1585 0;
BA_ "App-Botschaft" BO_ 1585 0;
BA_ "DiagState" BO_ 1585 0;
BA_ "DiagRequest" BO_ 1585 0;
BA_ "DiagResponse" BO_ 1585 0;
BA_ "GenMsgSendType" BO_ 1585 0;
BA_ "GenMsgCycleTime" BO_ 1585 40;
BA_ "GenMsgDelayTime" BO_ 1585 20;
BA_ "NWM-Botschaft" BO_ 1569 0;
BA_ "App-Botschaft" BO_ 1569 0;
BA_ "DiagState" BO_ 1569 0;
BA_ "DiagRequest" BO_ 1569 0;
BA_ "DiagResponse" BO_ 1569 0;
BA_ "GenMsgSendType" BO_ 1569 0;
BA_ "GenMsgCycleTime" BO_ 1569 40;
BA_ "GenMsgDelayTime" BO_ 1569 20;
BA_ "NWM-Botschaft" BO_ 1553 0;
BA_ "App-Botschaft" BO_ 1553 0;
BA_ "DiagState" BO_ 1553 0;
BA_ "DiagRequest" BO_ 1553 0;
BA_ "DiagResponse" BO_ 1553 0;
BA_ "GenMsgSendType" BO_ 1553 0;
BA_ "GenMsgCycleTime" BO_ 1553 40;
BA_ "GenMsgDelayTime" BO_ 1553 20;
BA_ "NWM-Botschaft" BO_ 963 0;
BA_ "App-Botschaft" BO_ 963 0;
BA_ "DiagState" BO_ 963 0;
BA_ "DiagRequest" BO_ 963 0;
BA_ "DiagResponse" BO_ 963 0;
BA_ "GenMsgSendType" BO_ 963 0;
BA_ "GenMsgCycleTime" BO_ 963 40;
BA_ "GenMsgDelayTime" BO_ 963 20;
BA_ "GenSigSendType" SG_ 1713 MODULE_TEMP_06_11 0;
BA_ "GenSigCycleTime" SG_ 1713 MODULE_TEMP_06_11 40;
BA_ "FlexKomSigStartValue" SG_ 1713 MODULE_TEMP_06_11 "00h";
BA_ "GenSigTimeout_BMU" SG_ 1713 MODULE_TEMP_06_11 220;
BA_ "FlexKomSID" SG_ 1713 MODULE_TEMP_06_11 1109;
BA_ "FlexKomSigStartPos" SG_ 1713 MODULE_TEMP_06_11 63;
BA_ "FlexKomSigLaenge" SG_ 1713 MODULE_TEMP_06_11 8;
BA_ "FlexKomSigName" SG_ 1713 MODULE_TEMP_06_11 "MODULE_TEMP_06_11";
BA_ "FlexKomComment" SG_ 1713 MODULE_TEMP_06_11 "Module temperature06";
BA_ "FlexKomIsMotorola" SG_ 1713 MODULE_TEMP_06_11 1;
BA_ "GenSigSendType" SG_ 1713 MODULE_TEMP_05_11 0;
BA_ "GenSigCycleTime" SG_ 1713 MODULE_TEMP_05_11 40;
BA_ "FlexKomSigStartValue" SG_ 1713 MODULE_TEMP_05_11 "00h";
BA_ "GenSigTimeout_BMU" SG_ 1713 MODULE_TEMP_05_11 220;
BA_ "FlexKomSID" SG_ 1713 MODULE_TEMP_05_11 1097;
BA_ "FlexKomSigStartPos" SG_ 1713 MODULE_TEMP_05_11 55;
BA_ "FlexKomSigLaenge" SG_ 1713 MODULE_TEMP_05_11 8;
BA_ "FlexKomSigName" SG_ 1713 MODULE_TEMP_05_11 "MODULE_TEMP_05_11";
BA_ "FlexKomComment" SG_ 1713 MODULE_TEMP_05_11 "Module temperature05";
BA_ "FlexKomIsMotorola" SG_ 1713 MODULE_TEMP_05_11 1;
BA_ "GenSigSendType" SG_ 1713 MODULE_TEMP_04_11 0;
BA_ "GenSigCycleTime" SG_ 1713 MODULE_TEMP_04_11 40;
BA_ "FlexKomSigStartValue" SG_ 1713 MODULE_TEMP_04_11 "00h";
BA_ "GenSigTimeout_BMU" SG_ 1713 MODULE_TEMP_04_11 220;
BA_ "FlexKomSID" SG_ 1713 MODULE_TEMP_04_11 1085;
BA_ "FlexKomSigStartPos" SG_ 1713 MODULE_TEMP_04_11 47;
BA_ "FlexKomSigLaenge" SG_ 1713 MODULE_TEMP_04_11 8;
BA_ "FlexKomSigName" SG_ 1713 MODULE_TEMP_04_11 "MODULE_TEMP_04_11";
BA_ "FlexKomComment" SG_ 1713 MODULE_TEMP_04_11 "Module temperature04";
BA_ "FlexKomIsMotorola" SG_ 1713 MODULE_TEMP_04_11 1;
BA_ "GenSigSendType" SG_ 1713 MODULE_TEMP_03_11 0;
BA_ "GenSigCycleTime" SG_ 1713 MODULE_TEMP_03_11 40;
BA_ "FlexKomSigStartValue" SG_ 1713 MODULE_TEMP_03_11 "00h";
BA_ "GenSigTimeout_BMU" SG_ 1713 MODULE_TEMP_03_11 220;
BA_ "FlexKomSID" SG_ 1713 MODULE_TEMP_03_11 1073;
BA_ "FlexKomSigStartPos" SG_ 1713 MODULE_TEMP_03_11 39;
BA_ "FlexKomSigLaenge" SG_ 1713 MODULE_TEMP_03_11 8;
BA_ "FlexKomSigName" SG_ 1713 MODULE_TEMP_03_11 "MODULE_TEMP_03_11";
BA_ "FlexKomComment" SG_ 1713 MODULE_TEMP_03_11 "Module temperature03";
BA_ "FlexKomIsMotorola" SG_ 1713 MODULE_TEMP_03_11 1;
BA_ "GenSigSendType" SG_ 1713 MODULE_TEMP_02_11 0;
BA_ "GenSigCycleTime" SG_ 1713 MODULE_TEMP_02_11 40;
BA_ "FlexKomSigStartValue" SG_ 1713 MODULE_TEMP_02_11 "00h";
BA_ "GenSigTimeout_BMU" SG_ 1713 MODULE_TEMP_02_11 220;
BA_ "FlexKomSID" SG_ 1713 MODULE_TEMP_02_11 1061;
BA_ "FlexKomSigStartPos" SG_ 1713 MODULE_TEMP_02_11 31;
BA_ "FlexKomSigLaenge" SG_ 1713 MODULE_TEMP_02_11 8;
BA_ "FlexKomSigName" SG_ 1713 MODULE_TEMP_02_11 "MODULE_TEMP_02_11";
BA_ "FlexKomComment" SG_ 1713 MODULE_TEMP_02_11 "Module temperature02";
BA_ "FlexKomIsMotorola" SG_ 1713 MODULE_TEMP_02_11 1;
BA_ "GenSigSendType" SG_ 1713 MODULE_TEMP_01_11 0;
BA_ "GenSigCycleTime" SG_ 1713 MODULE_TEMP_01_11 40;
BA_ "FlexKomSigStartValue" SG_ 1713 MODULE_TEMP_01_11 "00h";
BA_ "GenSigTimeout_BMU" SG_ 1713 MODULE_TEMP_01_11 220;
BA_ "FlexKomSID" SG_ 1713 MODULE_TEMP_01_11 1049;
BA_ "FlexKomSigStartPos" SG_ 1713 MODULE_TEMP_01_11 23;
BA_ "FlexKomSigLaenge" SG_ 1713 MODULE_TEMP_01_11 8;
BA_ "FlexKomSigName" SG_ 1713 MODULE_TEMP_01_11 "MODULE_TEMP_01_11";
BA_ "FlexKomComment" SG_ 1713 MODULE_TEMP_01_11 "Module temperature01";
BA_ "FlexKomIsMotorola" SG_ 1713 MODULE_TEMP_01_11 1;
BA_ "GenSigSendType" SG_ 1713 NUM_TABLE_VALUE_11 0;
BA_ "GenSigCycleTime" SG_ 1713 NUM_TABLE_VALUE_11 40;
BA_ "FlexKomSigStartValue" SG_ 1713 NUM_TABLE_VALUE_11 "0Fh";
BA_ "GenSigStartValue" SG_ 1713 NUM_TABLE_VALUE_11 15;
BA_ "GenSigTimeout_BMU" SG_ 1713 NUM_TABLE_VALUE_11 220;
BA_ "FlexKomSID" SG_ 1713 NUM_TABLE_VALUE_11 1037;
BA_ "FlexKomSigStartPos" SG_ 1713 NUM_TABLE_VALUE_11 15;
BA_ "FlexKomSigLaenge" SG_ 1713 NUM_TABLE_VALUE_11 4;
BA_ "FlexKomSigName" SG_ 1713 NUM_TABLE_VALUE_11 "NUM_TABLE_VALUE_11";
BA_ "FlexKomComment" SG_ 1713 NUM_TABLE_VALUE_11 "Stored Automatic numbering table";
BA_ "FlexKomIsMotorola" SG_ 1713 NUM_TABLE_VALUE_11 1;
BA_ "GenSigSendType" SG_ 1713 BLC_DRV_STAT_12_11 0;
BA_ "GenSigCycleTime" SG_ 1713 BLC_DRV_STAT_12_11 40;
BA_ "FlexKomSigStartValue" SG_ 1713 BLC_DRV_STAT_12_11 "0000h";
BA_ "GenSigTimeout_BMU" SG_ 1713 BLC_DRV_STAT_12_11 220;
BA_ "FlexKomSID" SG_ 1713 BLC_DRV_STAT_12_11 720;
BA_ "FlexKomSigStartPos" SG_ 1713 BLC_DRV_STAT_12_11 7;
BA_ "FlexKomSigLaenge" SG_ 1713 BLC_DRV_STAT_12_11 16;
BA_ "FlexKomSigName" SG_ 1713 BLC_DRV_STAT_12_11 "BLC_DRV_STAT_11";
BA_ "FlexKomComment" SG_ 1713 BLC_DRV_STAT_12_11 "Balancer drive status packet";
BA_ "FlexKomIsMotorola" SG_ 1713 BLC_DRV_STAT_12_11 1;
BA_ "GenSigSendType" SG_ 1713 BLC_DRV_STAT_11_11 0;
BA_ "GenSigCycleTime" SG_ 1713 BLC_DRV_STAT_11_11 40;
BA_ "FlexKomSigStartValue" SG_ 1713 BLC_DRV_STAT_11_11 "0000h";
BA_ "GenSigTimeout_BMU" SG_ 1713 BLC_DRV_STAT_11_11 220;
BA_ "FlexKomSID" SG_ 1713 BLC_DRV_STAT_11_11 720;
BA_ "FlexKomSigStartPos" SG_ 1713 BLC_DRV_STAT_11_11 7;
BA_ "FlexKomSigLaenge" SG_ 1713 BLC_DRV_STAT_11_11 16;
BA_ "FlexKomSigName" SG_ 1713 BLC_DRV_STAT_11_11 "BLC_DRV_STAT_11";
BA_ "FlexKomComment" SG_ 1713 BLC_DRV_STAT_11_11 "Balancer drive status packet";
BA_ "FlexKomIsMotorola" SG_ 1713 BLC_DRV_STAT_11_11 1;
BA_ "GenSigSendType" SG_ 1713 BLC_DRV_STAT_10_11 0;
BA_ "GenSigCycleTime" SG_ 1713 BLC_DRV_STAT_10_11 40;
BA_ "FlexKomSigStartValue" SG_ 1713 BLC_DRV_STAT_10_11 "0000h";
BA_ "GenSigTimeout_BMU" SG_ 1713 BLC_DRV_STAT_10_11 220;
BA_ "FlexKomSID" SG_ 1713 BLC_DRV_STAT_10_11 720;
BA_ "FlexKomSigStartPos" SG_ 1713 BLC_DRV_STAT_10_11 7;
BA_ "FlexKomSigLaenge" SG_ 1713 BLC_DRV_STAT_10_11 16;
BA_ "FlexKomSigName" SG_ 1713 BLC_DRV_STAT_10_11 "BLC_DRV_STAT_11";
BA_ "FlexKomComment" SG_ 1713 BLC_DRV_STAT_10_11 "Balancer drive status packet";
BA_ "FlexKomIsMotorola" SG_ 1713 BLC_DRV_STAT_10_11 1;
BA_ "GenSigSendType" SG_ 1713 BLC_DRV_STAT_09_11 0;
BA_ "GenSigCycleTime" SG_ 1713 BLC_DRV_STAT_09_11 40;
BA_ "FlexKomSigStartValue" SG_ 1713 BLC_DRV_STAT_09_11 "0000h";
BA_ "GenSigTimeout_BMU" SG_ 1713 BLC_DRV_STAT_09_11 220;
BA_ "FlexKomSID" SG_ 1713 BLC_DRV_STAT_09_11 720;
BA_ "FlexKomSigStartPos" SG_ 1713 BLC_DRV_STAT_09_11 7;
BA_ "FlexKomSigLaenge" SG_ 1713 BLC_DRV_STAT_09_11 16;
BA_ "FlexKomSigName" SG_ 1713 BLC_DRV_STAT_09_11 "BLC_DRV_STAT_11";
BA_ "FlexKomComment" SG_ 1713 BLC_DRV_STAT_09_11 "Balancer drive status packet";
BA_ "FlexKomIsMotorola" SG_ 1713 BLC_DRV_STAT_09_11 1;
BA_ "GenSigSendType" SG_ 1713 BLC_DRV_STAT_08_11 0;
BA_ "GenSigCycleTime" SG_ 1713 BLC_DRV_STAT_08_11 40;
BA_ "FlexKomSigStartValue" SG_ 1713 BLC_DRV_STAT_08_11 "0000h";
BA_ "GenSigTimeout_BMU" SG_ 1713 BLC_DRV_STAT_08_11 220;
BA_ "FlexKomSID" SG_ 1713 BLC_DRV_STAT_08_11 720;
BA_ "FlexKomSigStartPos" SG_ 1713 BLC_DRV_STAT_08_11 7;
BA_ "FlexKomSigLaenge" SG_ 1713 BLC_DRV_STAT_08_11 16;
BA_ "FlexKomSigName" SG_ 1713 BLC_DRV_STAT_08_11 "BLC_DRV_STAT_11";
BA_ "FlexKomComment" SG_ 1713 BLC_DRV_STAT_08_11 "Balancer drive status packet";
BA_ "FlexKomIsMotorola" SG_ 1713 BLC_DRV_STAT_08_11 1;
BA_ "GenSigSendType" SG_ 1713 BLC_DRV_STAT_07_11 0;
BA_ "GenSigCycleTime" SG_ 1713 BLC_DRV_STAT_07_11 40;
BA_ "FlexKomSigStartValue" SG_ 1713 BLC_DRV_STAT_07_11 "0000h";
BA_ "GenSigTimeout_BMU" SG_ 1713 BLC_DRV_STAT_07_11 220;
BA_ "FlexKomSID" SG_ 1713 BLC_DRV_STAT_07_11 720;
BA_ "FlexKomSigStartPos" SG_ 1713 BLC_DRV_STAT_07_11 7;
BA_ "FlexKomSigLaenge" SG_ 1713 BLC_DRV_STAT_07_11 16;
BA_ "FlexKomSigName" SG_ 1713 BLC_DRV_STAT_07_11 "BLC_DRV_STAT_11";
BA_ "FlexKomComment" SG_ 1713 BLC_DRV_STAT_07_11 "Balancer drive status packet";
BA_ "FlexKomIsMotorola" SG_ 1713 BLC_DRV_STAT_07_11 1;
BA_ "GenSigSendType" SG_ 1713 BLC_DRV_STAT_06_11 0;
BA_ "GenSigCycleTime" SG_ 1713 BLC_DRV_STAT_06_11 40;
BA_ "FlexKomSigStartValue" SG_ 1713 BLC_DRV_STAT_06_11 "0000h";
BA_ "GenSigTimeout_BMU" SG_ 1713 BLC_DRV_STAT_06_11 220;
BA_ "FlexKomSID" SG_ 1713 BLC_DRV_STAT_06_11 720;
BA_ "FlexKomSigStartPos" SG_ 1713 BLC_DRV_STAT_06_11 7;
BA_ "FlexKomSigLaenge" SG_ 1713 BLC_DRV_STAT_06_11 16;
BA_ "FlexKomSigName" SG_ 1713 BLC_DRV_STAT_06_11 "BLC_DRV_STAT_11";
BA_ "FlexKomComment" SG_ 1713 BLC_DRV_STAT_06_11 "Balancer drive status packet";
BA_ "FlexKomIsMotorola" SG_ 1713 BLC_DRV_STAT_06_11 1;
BA_ "GenSigSendType" SG_ 1713 BLC_DRV_STAT_05_11 0;
BA_ "GenSigCycleTime" SG_ 1713 BLC_DRV_STAT_05_11 40;
BA_ "FlexKomSigStartValue" SG_ 1713 BLC_DRV_STAT_05_11 "0000h";
BA_ "GenSigTimeout_BMU" SG_ 1713 BLC_DRV_STAT_05_11 220;
BA_ "FlexKomSID" SG_ 1713 BLC_DRV_STAT_05_11 720;
BA_ "FlexKomSigStartPos" SG_ 1713 BLC_DRV_STAT_05_11 7;
BA_ "FlexKomSigLaenge" SG_ 1713 BLC_DRV_STAT_05_11 16;
BA_ "FlexKomSigName" SG_ 1713 BLC_DRV_STAT_05_11 "BLC_DRV_STAT_11";
BA_ "FlexKomComment" SG_ 1713 BLC_DRV_STAT_05_11 "Balancer drive status packet";
BA_ "FlexKomIsMotorola" SG_ 1713 BLC_DRV_STAT_05_11 1;
BA_ "GenSigSendType" SG_ 1713 BLC_DRV_STAT_04_11 0;
BA_ "GenSigCycleTime" SG_ 1713 BLC_DRV_STAT_04_11 40;
BA_ "FlexKomSigStartValue" SG_ 1713 BLC_DRV_STAT_04_11 "0000h";
BA_ "GenSigTimeout_BMU" SG_ 1713 BLC_DRV_STAT_04_11 220;
BA_ "FlexKomSID" SG_ 1713 BLC_DRV_STAT_04_11 720;
BA_ "FlexKomSigStartPos" SG_ 1713 BLC_DRV_STAT_04_11 7;
BA_ "FlexKomSigLaenge" SG_ 1713 BLC_DRV_STAT_04_11 16;
BA_ "FlexKomSigName" SG_ 1713 BLC_DRV_STAT_04_11 "BLC_DRV_STAT_11";
BA_ "FlexKomComment" SG_ 1713 BLC_DRV_STAT_04_11 "Balancer drive status packet";
BA_ "FlexKomIsMotorola" SG_ 1713 BLC_DRV_STAT_04_11 1;
BA_ "GenSigSendType" SG_ 1713 BLC_DRV_STAT_03_11 0;
BA_ "GenSigCycleTime" SG_ 1713 BLC_DRV_STAT_03_11 40;
BA_ "FlexKomSigStartValue" SG_ 1713 BLC_DRV_STAT_03_11 "0000h";
BA_ "GenSigTimeout_BMU" SG_ 1713 BLC_DRV_STAT_03_11 220;
BA_ "FlexKomSID" SG_ 1713 BLC_DRV_STAT_03_11 720;
BA_ "FlexKomSigStartPos" SG_ 1713 BLC_DRV_STAT_03_11 7;
BA_ "FlexKomSigLaenge" SG_ 1713 BLC_DRV_STAT_03_11 16;
BA_ "FlexKomSigName" SG_ 1713 BLC_DRV_STAT_03_11 "BLC_DRV_STAT_11";
BA_ "FlexKomComment" SG_ 1713 BLC_DRV_STAT_03_11 "Balancer drive status packet";
BA_ "FlexKomIsMotorola" SG_ 1713 BLC_DRV_STAT_03_11 1;
BA_ "GenSigSendType" SG_ 1713 BLC_DRV_STAT_02_11 0;
BA_ "GenSigCycleTime" SG_ 1713 BLC_DRV_STAT_02_11 40;
BA_ "FlexKomSigStartValue" SG_ 1713 BLC_DRV_STAT_02_11 "0000h";
BA_ "GenSigTimeout_BMU" SG_ 1713 BLC_DRV_STAT_02_11 220;
BA_ "FlexKomSID" SG_ 1713 BLC_DRV_STAT_02_11 720;
BA_ "FlexKomSigStartPos" SG_ 1713 BLC_DRV_STAT_02_11 7;
BA_ "FlexKomSigLaenge" SG_ 1713 BLC_DRV_STAT_02_11 16;
BA_ "FlexKomSigName" SG_ 1713 BLC_DRV_STAT_02_11 "BLC_DRV_STAT_11";
BA_ "FlexKomComment" SG_ 1713 BLC_DRV_STAT_02_11 "Balancer drive status packet";
BA_ "FlexKomIsMotorola" SG_ 1713 BLC_DRV_STAT_02_11 1;
BA_ "GenSigSendType" SG_ 1713 BLC_DRV_STAT_01_11 0;
BA_ "GenSigCycleTime" SG_ 1713 BLC_DRV_STAT_01_11 40;
BA_ "FlexKomSigStartValue" SG_ 1713 BLC_DRV_STAT_01_11 "0000h";
BA_ "GenSigTimeout_BMU" SG_ 1713 BLC_DRV_STAT_01_11 220;
BA_ "FlexKomSID" SG_ 1713 BLC_DRV_STAT_01_11 720;
BA_ "FlexKomSigStartPos" SG_ 1713 BLC_DRV_STAT_01_11 7;
BA_ "FlexKomSigLaenge" SG_ 1713 BLC_DRV_STAT_01_11 16;
BA_ "FlexKomSigName" SG_ 1713 BLC_DRV_STAT_01_11 "BLC_DRV_STAT_11";
BA_ "FlexKomComment" SG_ 1713 BLC_DRV_STAT_01_11 "Balancer drive status packet";
BA_ "FlexKomIsMotorola" SG_ 1713 BLC_DRV_STAT_01_11 1;
BA_ "GenSigSendType" SG_ 1697 MODULE_TEMP_06_10 0;
BA_ "GenSigCycleTime" SG_ 1697 MODULE_TEMP_06_10 40;
BA_ "FlexKomSigStartValue" SG_ 1697 MODULE_TEMP_06_10 "00h";
BA_ "GenSigTimeout_BMU" SG_ 1697 MODULE_TEMP_06_10 220;
BA_ "FlexKomSID" SG_ 1697 MODULE_TEMP_06_10 1108;
BA_ "FlexKomSigStartPos" SG_ 1697 MODULE_TEMP_06_10 63;
BA_ "FlexKomSigLaenge" SG_ 1697 MODULE_TEMP_06_10 8;
BA_ "FlexKomSigName" SG_ 1697 MODULE_TEMP_06_10 "MODULE_TEMP_06_10";
BA_ "FlexKomComment" SG_ 1697 MODULE_TEMP_06_10 "Module temperature06";
BA_ "FlexKomIsMotorola" SG_ 1697 MODULE_TEMP_06_10 1;
BA_ "GenSigSendType" SG_ 1697 MODULE_TEMP_05_10 0;
BA_ "GenSigCycleTime" SG_ 1697 MODULE_TEMP_05_10 40;
BA_ "FlexKomSigStartValue" SG_ 1697 MODULE_TEMP_05_10 "00h";
BA_ "GenSigTimeout_BMU" SG_ 1697 MODULE_TEMP_05_10 220;
BA_ "FlexKomSID" SG_ 1697 MODULE_TEMP_05_10 1096;
BA_ "FlexKomSigStartPos" SG_ 1697 MODULE_TEMP_05_10 55;
BA_ "FlexKomSigLaenge" SG_ 1697 MODULE_TEMP_05_10 8;
BA_ "FlexKomSigName" SG_ 1697 MODULE_TEMP_05_10 "MODULE_TEMP_05_10";
BA_ "FlexKomComment" SG_ 1697 MODULE_TEMP_05_10 "Module temperature05";
BA_ "FlexKomIsMotorola" SG_ 1697 MODULE_TEMP_05_10 1;
BA_ "GenSigSendType" SG_ 1697 MODULE_TEMP_04_10 0;
BA_ "GenSigCycleTime" SG_ 1697 MODULE_TEMP_04_10 40;
BA_ "FlexKomSigStartValue" SG_ 1697 MODULE_TEMP_04_10 "00h";
BA_ "GenSigTimeout_BMU" SG_ 1697 MODULE_TEMP_04_10 220;
BA_ "FlexKomSID" SG_ 1697 MODULE_TEMP_04_10 1084;
BA_ "FlexKomSigStartPos" SG_ 1697 MODULE_TEMP_04_10 47;
BA_ "FlexKomSigLaenge" SG_ 1697 MODULE_TEMP_04_10 8;
BA_ "FlexKomSigName" SG_ 1697 MODULE_TEMP_04_10 "MODULE_TEMP_04_10";
BA_ "FlexKomComment" SG_ 1697 MODULE_TEMP_04_10 "Module temperature04";
BA_ "FlexKomIsMotorola" SG_ 1697 MODULE_TEMP_04_10 1;
BA_ "GenSigSendType" SG_ 1697 MODULE_TEMP_03_10 0;
BA_ "GenSigCycleTime" SG_ 1697 MODULE_TEMP_03_10 40;
BA_ "FlexKomSigStartValue" SG_ 1697 MODULE_TEMP_03_10 "00h";
BA_ "GenSigTimeout_BMU" SG_ 1697 MODULE_TEMP_03_10 220;
BA_ "FlexKomSID" SG_ 1697 MODULE_TEMP_03_10 1072;
BA_ "FlexKomSigStartPos" SG_ 1697 MODULE_TEMP_03_10 39;
BA_ "FlexKomSigLaenge" SG_ 1697 MODULE_TEMP_03_10 8;
BA_ "FlexKomSigName" SG_ 1697 MODULE_TEMP_03_10 "MODULE_TEMP_03_10";
BA_ "FlexKomComment" SG_ 1697 MODULE_TEMP_03_10 "Module temperature03";
BA_ "FlexKomIsMotorola" SG_ 1697 MODULE_TEMP_03_10 1;
BA_ "GenSigSendType" SG_ 1697 MODULE_TEMP_02_10 0;
BA_ "GenSigCycleTime" SG_ 1697 MODULE_TEMP_02_10 40;
BA_ "FlexKomSigStartValue" SG_ 1697 MODULE_TEMP_02_10 "00h";
BA_ "GenSigTimeout_BMU" SG_ 1697 MODULE_TEMP_02_10 220;
BA_ "FlexKomSID" SG_ 1697 MODULE_TEMP_02_10 1060;
BA_ "FlexKomSigStartPos" SG_ 1697 MODULE_TEMP_02_10 31;
BA_ "FlexKomSigLaenge" SG_ 1697 MODULE_TEMP_02_10 8;
BA_ "FlexKomSigName" SG_ 1697 MODULE_TEMP_02_10 "MODULE_TEMP_02_10";
BA_ "FlexKomComment" SG_ 1697 MODULE_TEMP_02_10 "Module temperature02";
BA_ "FlexKomIsMotorola" SG_ 1697 MODULE_TEMP_02_10 1;
BA_ "GenSigSendType" SG_ 1697 MODULE_TEMP_01_10 0;
BA_ "GenSigCycleTime" SG_ 1697 MODULE_TEMP_01_10 40;
BA_ "FlexKomSigStartValue" SG_ 1697 MODULE_TEMP_01_10 "00h";
BA_ "GenSigTimeout_BMU" SG_ 1697 MODULE_TEMP_01_10 220;
BA_ "FlexKomSID" SG_ 1697 MODULE_TEMP_01_10 1048;
BA_ "FlexKomSigStartPos" SG_ 1697 MODULE_TEMP_01_10 23;
BA_ "FlexKomSigLaenge" SG_ 1697 MODULE_TEMP_01_10 8;
BA_ "FlexKomSigName" SG_ 1697 MODULE_TEMP_01_10 "MODULE_TEMP_01_10";
BA_ "FlexKomComment" SG_ 1697 MODULE_TEMP_01_10 "Module temperature01";
BA_ "FlexKomIsMotorola" SG_ 1697 MODULE_TEMP_01_10 1;
BA_ "GenSigSendType" SG_ 1697 NUM_TABLE_VALUE_10 0;
BA_ "GenSigCycleTime" SG_ 1697 NUM_TABLE_VALUE_10 40;
BA_ "FlexKomSigStartValue" SG_ 1697 NUM_TABLE_VALUE_10 "0Fh";
BA_ "GenSigStartValue" SG_ 1697 NUM_TABLE_VALUE_10 15;
BA_ "GenSigTimeout_BMU" SG_ 1697 NUM_TABLE_VALUE_10 220;
BA_ "FlexKomSID" SG_ 1697 NUM_TABLE_VALUE_10 1036;
BA_ "FlexKomSigStartPos" SG_ 1697 NUM_TABLE_VALUE_10 15;
BA_ "FlexKomSigLaenge" SG_ 1697 NUM_TABLE_VALUE_10 4;
BA_ "FlexKomSigName" SG_ 1697 NUM_TABLE_VALUE_10 "NUM_TABLE_VALUE_10";
BA_ "FlexKomComment" SG_ 1697 NUM_TABLE_VALUE_10 "Stored Automatic numbering table";
BA_ "FlexKomIsMotorola" SG_ 1697 NUM_TABLE_VALUE_10 1;
BA_ "GenSigSendType" SG_ 1697 BLC_DRV_STAT_12_10 0;
BA_ "GenSigCycleTime" SG_ 1697 BLC_DRV_STAT_12_10 40;
BA_ "FlexKomSigStartValue" SG_ 1697 BLC_DRV_STAT_12_10 "0000h";
BA_ "GenSigTimeout_BMU" SG_ 1697 BLC_DRV_STAT_12_10 220;
BA_ "FlexKomSID" SG_ 1697 BLC_DRV_STAT_12_10 722;
BA_ "FlexKomSigStartPos" SG_ 1697 BLC_DRV_STAT_12_10 7;
BA_ "FlexKomSigLaenge" SG_ 1697 BLC_DRV_STAT_12_10 16;
BA_ "FlexKomSigName" SG_ 1697 BLC_DRV_STAT_12_10 "BLC_DRV_STAT_10";
BA_ "FlexKomComment" SG_ 1697 BLC_DRV_STAT_12_10 "Balancer drive status packet";
BA_ "FlexKomIsMotorola" SG_ 1697 BLC_DRV_STAT_12_10 1;
BA_ "GenSigSendType" SG_ 1697 BLC_DRV_STAT_11_10 0;
BA_ "GenSigCycleTime" SG_ 1697 BLC_DRV_STAT_11_10 40;
BA_ "FlexKomSigStartValue" SG_ 1697 BLC_DRV_STAT_11_10 "0000h";
BA_ "GenSigTimeout_BMU" SG_ 1697 BLC_DRV_STAT_11_10 220;
BA_ "FlexKomSID" SG_ 1697 BLC_DRV_STAT_11_10 722;
BA_ "FlexKomSigStartPos" SG_ 1697 BLC_DRV_STAT_11_10 7;
BA_ "FlexKomSigLaenge" SG_ 1697 BLC_DRV_STAT_11_10 16;
BA_ "FlexKomSigName" SG_ 1697 BLC_DRV_STAT_11_10 "BLC_DRV_STAT_10";
BA_ "FlexKomComment" SG_ 1697 BLC_DRV_STAT_11_10 "Balancer drive status packet";
BA_ "FlexKomIsMotorola" SG_ 1697 BLC_DRV_STAT_11_10 1;
BA_ "GenSigSendType" SG_ 1697 BLC_DRV_STAT_10_10 0;
BA_ "GenSigCycleTime" SG_ 1697 BLC_DRV_STAT_10_10 40;
BA_ "FlexKomSigStartValue" SG_ 1697 BLC_DRV_STAT_10_10 "0000h";
BA_ "GenSigTimeout_BMU" SG_ 1697 BLC_DRV_STAT_10_10 220;
BA_ "FlexKomSID" SG_ 1697 BLC_DRV_STAT_10_10 722;
BA_ "FlexKomSigStartPos" SG_ 1697 BLC_DRV_STAT_10_10 7;
BA_ "FlexKomSigLaenge" SG_ 1697 BLC_DRV_STAT_10_10 16;
BA_ "FlexKomSigName" SG_ 1697 BLC_DRV_STAT_10_10 "BLC_DRV_STAT_10";
BA_ "FlexKomComment" SG_ 1697 BLC_DRV_STAT_10_10 "Balancer drive status packet";
BA_ "FlexKomIsMotorola" SG_ 1697 BLC_DRV_STAT_10_10 1;
BA_ "GenSigSendType" SG_ 1697 BLC_DRV_STAT_09_10 0;
BA_ "GenSigCycleTime" SG_ 1697 BLC_DRV_STAT_09_10 40;
BA_ "FlexKomSigStartValue" SG_ 1697 BLC_DRV_STAT_09_10 "0000h";
BA_ "GenSigTimeout_BMU" SG_ 1697 BLC_DRV_STAT_09_10 220;
BA_ "FlexKomSID" SG_ 1697 BLC_DRV_STAT_09_10 722;
BA_ "FlexKomSigStartPos" SG_ 1697 BLC_DRV_STAT_09_10 7;
BA_ "FlexKomSigLaenge" SG_ 1697 BLC_DRV_STAT_09_10 16;
BA_ "FlexKomSigName" SG_ 1697 BLC_DRV_STAT_09_10 "BLC_DRV_STAT_10";
BA_ "FlexKomComment" SG_ 1697 BLC_DRV_STAT_09_10 "Balancer drive status packet";
BA_ "FlexKomIsMotorola" SG_ 1697 BLC_DRV_STAT_09_10 1;
BA_ "GenSigSendType" SG_ 1697 BLC_DRV_STAT_08_10 0;
BA_ "GenSigCycleTime" SG_ 1697 BLC_DRV_STAT_08_10 40;
BA_ "FlexKomSigStartValue" SG_ 1697 BLC_DRV_STAT_08_10 "0000h";
BA_ "GenSigTimeout_BMU" SG_ 1697 BLC_DRV_STAT_08_10 220;
BA_ "FlexKomSID" SG_ 1697 BLC_DRV_STAT_08_10 722;
BA_ "FlexKomSigStartPos" SG_ 1697 BLC_DRV_STAT_08_10 7;
BA_ "FlexKomSigLaenge" SG_ 1697 BLC_DRV_STAT_08_10 16;
BA_ "FlexKomSigName" SG_ 1697 BLC_DRV_STAT_08_10 "BLC_DRV_STAT_10";
BA_ "FlexKomComment" SG_ 1697 BLC_DRV_STAT_08_10 "Balancer drive status packet";
BA_ "FlexKomIsMotorola" SG_ 1697 BLC_DRV_STAT_08_10 1;
BA_ "GenSigSendType" SG_ 1697 BLC_DRV_STAT_07_10 0;
BA_ "GenSigCycleTime" SG_ 1697 BLC_DRV_STAT_07_10 40;
BA_ "FlexKomSigStartValue" SG_ 1697 BLC_DRV_STAT_07_10 "0000h";
BA_ "GenSigTimeout_BMU" SG_ 1697 BLC_DRV_STAT_07_10 220;
BA_ "FlexKomSID" SG_ 1697 BLC_DRV_STAT_07_10 722;
BA_ "FlexKomSigStartPos" SG_ 1697 BLC_DRV_STAT_07_10 7;
BA_ "FlexKomSigLaenge" SG_ 1697 BLC_DRV_STAT_07_10 16;
BA_ "FlexKomSigName" SG_ 1697 BLC_DRV_STAT_07_10 "BLC_DRV_STAT_10";
BA_ "FlexKomComment" SG_ 1697 BLC_DRV_STAT_07_10 "Balancer drive status packet";
BA_ "FlexKomIsMotorola" SG_ 1697 BLC_DRV_STAT_07_10 1;
BA_ "GenSigSendType" SG_ 1697 BLC_DRV_STAT_06_10 0;
BA_ "GenSigCycleTime" SG_ 1697 BLC_DRV_STAT_06_10 40;
BA_ "FlexKomSigStartValue" SG_ 1697 BLC_DRV_STAT_06_10 "0000h";
BA_ "GenSigTimeout_BMU" SG_ 1697 BLC_DRV_STAT_06_10 220;
BA_ "FlexKomSID" SG_ 1697 BLC_DRV_STAT_06_10 722;
BA_ "FlexKomSigStartPos" SG_ 1697 BLC_DRV_STAT_06_10 7;
BA_ "FlexKomSigLaenge" SG_ 1697 BLC_DRV_STAT_06_10 16;
BA_ "FlexKomSigName" SG_ 1697 BLC_DRV_STAT_06_10 "BLC_DRV_STAT_10";
BA_ "FlexKomComment" SG_ 1697 BLC_DRV_STAT_06_10 "Balancer drive status packet";
BA_ "FlexKomIsMotorola" SG_ 1697 BLC_DRV_STAT_06_10 1;
BA_ "GenSigSendType" SG_ 1697 BLC_DRV_STAT_05_10 0;
BA_ "GenSigCycleTime" SG_ 1697 BLC_DRV_STAT_05_10 40;
BA_ "FlexKomSigStartValue" SG_ 1697 BLC_DRV_STAT_05_10 "0000h";
BA_ "GenSigTimeout_BMU" SG_ 1697 BLC_DRV_STAT_05_10 220;
BA_ "FlexKomSID" SG_ 1697 BLC_DRV_STAT_05_10 722;
BA_ "FlexKomSigStartPos" SG_ 1697 BLC_DRV_STAT_05_10 7;
BA_ "FlexKomSigLaenge" SG_ 1697 BLC_DRV_STAT_05_10 16;
BA_ "FlexKomSigName" SG_ 1697 BLC_DRV_STAT_05_10 "BLC_DRV_STAT_10";
BA_ "FlexKomComment" SG_ 1697 BLC_DRV_STAT_05_10 "Balancer drive status packet";
BA_ "FlexKomIsMotorola" SG_ 1697 BLC_DRV_STAT_05_10 1;
BA_ "GenSigSendType" SG_ 1697 BLC_DRV_STAT_04_10 0;
BA_ "GenSigCycleTime" SG_ 1697 BLC_DRV_STAT_04_10 40;
BA_ "FlexKomSigStartValue" SG_ 1697 BLC_DRV_STAT_04_10 "0000h";
BA_ "GenSigTimeout_BMU" SG_ 1697 BLC_DRV_STAT_04_10 220;
BA_ "FlexKomSID" SG_ 1697 BLC_DRV_STAT_04_10 722;
BA_ "FlexKomSigStartPos" SG_ 1697 BLC_DRV_STAT_04_10 7;
BA_ "FlexKomSigLaenge" SG_ 1697 BLC_DRV_STAT_04_10 16;
BA_ "FlexKomSigName" SG_ 1697 BLC_DRV_STAT_04_10 "BLC_DRV_STAT_10";
BA_ "FlexKomComment" SG_ 1697 BLC_DRV_STAT_04_10 "Balancer drive status packet";
BA_ "FlexKomIsMotorola" SG_ 1697 BLC_DRV_STAT_04_10 1;
BA_ "GenSigSendType" SG_ 1697 BLC_DRV_STAT_03_10 0;
BA_ "GenSigCycleTime" SG_ 1697 BLC_DRV_STAT_03_10 40;
BA_ "FlexKomSigStartValue" SG_ 1697 BLC_DRV_STAT_03_10 "0000h";
BA_ "GenSigTimeout_BMU" SG_ 1697 BLC_DRV_STAT_03_10 220;
BA_ "FlexKomSID" SG_ 1697 BLC_DRV_STAT_03_10 722;
BA_ "FlexKomSigStartPos" SG_ 1697 BLC_DRV_STAT_03_10 7;
BA_ "FlexKomSigLaenge" SG_ 1697 BLC_DRV_STAT_03_10 16;
BA_ "FlexKomSigName" SG_ 1697 BLC_DRV_STAT_03_10 "BLC_DRV_STAT_10";
BA_ "FlexKomComment" SG_ 1697 BLC_DRV_STAT_03_10 "Balancer drive status packet";
BA_ "FlexKomIsMotorola" SG_ 1697 BLC_DRV_STAT_03_10 1;
BA_ "GenSigSendType" SG_ 1697 BLC_DRV_STAT_02_10 0;
BA_ "GenSigCycleTime" SG_ 1697 BLC_DRV_STAT_02_10 40;
BA_ "FlexKomSigStartValue" SG_ 1697 BLC_DRV_STAT_02_10 "0000h";
BA_ "GenSigTimeout_BMU" SG_ 1697 BLC_DRV_STAT_02_10 220;
BA_ "FlexKomSID" SG_ 1697 BLC_DRV_STAT_02_10 722;
BA_ "FlexKomSigStartPos" SG_ 1697 BLC_DRV_STAT_02_10 7;
BA_ "FlexKomSigLaenge" SG_ 1697 BLC_DRV_STAT_02_10 16;
BA_ "FlexKomSigName" SG_ 1697 BLC_DRV_STAT_02_10 "BLC_DRV_STAT_10";
BA_ "FlexKomComment" SG_ 1697 BLC_DRV_STAT_02_10 "Balancer drive status packet";
BA_ "FlexKomIsMotorola" SG_ 1697 BLC_DRV_STAT_02_10 1;
BA_ "GenSigSendType" SG_ 1697 BLC_DRV_STAT_01_10 0;
BA_ "GenSigCycleTime" SG_ 1697 BLC_DRV_STAT_01_10 40;
BA_ "FlexKomSigStartValue" SG_ 1697 BLC_DRV_STAT_01_10 "0000h";
BA_ "GenSigTimeout_BMU" SG_ 1697 BLC_DRV_STAT_01_10 220;
BA_ "FlexKomSID" SG_ 1697 BLC_DRV_STAT_01_10 722;
BA_ "FlexKomSigStartPos" SG_ 1697 BLC_DRV_STAT_01_10 7;
BA_ "FlexKomSigLaenge" SG_ 1697 BLC_DRV_STAT_01_10 16;
BA_ "FlexKomSigName" SG_ 1697 BLC_DRV_STAT_01_10 "BLC_DRV_STAT_10";
BA_ "FlexKomComment" SG_ 1697 BLC_DRV_STAT_01_10 "Balancer drive status packet";
BA_ "FlexKomIsMotorola" SG_ 1697 BLC_DRV_STAT_01_10 1;
BA_ "GenSigSendType" SG_ 1681 MODULE_TEMP_06_09 0;
BA_ "GenSigCycleTime" SG_ 1681 MODULE_TEMP_06_09 40;
BA_ "FlexKomSigStartValue" SG_ 1681 MODULE_TEMP_06_09 "00h";
BA_ "GenSigTimeout_BMU" SG_ 1681 MODULE_TEMP_06_09 220;
BA_ "FlexKomSID" SG_ 1681 MODULE_TEMP_06_09 1107;
BA_ "FlexKomSigStartPos" SG_ 1681 MODULE_TEMP_06_09 63;
BA_ "FlexKomSigLaenge" SG_ 1681 MODULE_TEMP_06_09 8;
BA_ "FlexKomSigName" SG_ 1681 MODULE_TEMP_06_09 "MODULE_TEMP_06_09";
BA_ "FlexKomComment" SG_ 1681 MODULE_TEMP_06_09 "Module temperature06";
BA_ "FlexKomIsMotorola" SG_ 1681 MODULE_TEMP_06_09 1;
BA_ "GenSigSendType" SG_ 1681 MODULE_TEMP_05_09 0;
BA_ "GenSigCycleTime" SG_ 1681 MODULE_TEMP_05_09 40;
BA_ "FlexKomSigStartValue" SG_ 1681 MODULE_TEMP_05_09 "00h";
BA_ "GenSigTimeout_BMU" SG_ 1681 MODULE_TEMP_05_09 220;
BA_ "FlexKomSID" SG_ 1681 MODULE_TEMP_05_09 1095;
BA_ "FlexKomSigStartPos" SG_ 1681 MODULE_TEMP_05_09 55;
BA_ "FlexKomSigLaenge" SG_ 1681 MODULE_TEMP_05_09 8;
BA_ "FlexKomSigName" SG_ 1681 MODULE_TEMP_05_09 "MODULE_TEMP_05_09";
BA_ "FlexKomComment" SG_ 1681 MODULE_TEMP_05_09 "Module temperature05";
BA_ "FlexKomIsMotorola" SG_ 1681 MODULE_TEMP_05_09 1;
BA_ "GenSigSendType" SG_ 1681 MODULE_TEMP_04_09 0;
BA_ "GenSigCycleTime" SG_ 1681 MODULE_TEMP_04_09 40;
BA_ "FlexKomSigStartValue" SG_ 1681 MODULE_TEMP_04_09 "00h";
BA_ "GenSigTimeout_BMU" SG_ 1681 MODULE_TEMP_04_09 220;
BA_ "FlexKomSID" SG_ 1681 MODULE_TEMP_04_09 1083;
BA_ "FlexKomSigStartPos" SG_ 1681 MODULE_TEMP_04_09 47;
BA_ "FlexKomSigLaenge" SG_ 1681 MODULE_TEMP_04_09 8;
BA_ "FlexKomSigName" SG_ 1681 MODULE_TEMP_04_09 "MODULE_TEMP_04_09";
BA_ "FlexKomComment" SG_ 1681 MODULE_TEMP_04_09 "Module temperature04";
BA_ "FlexKomIsMotorola" SG_ 1681 MODULE_TEMP_04_09 1;
BA_ "GenSigSendType" SG_ 1681 MODULE_TEMP_03_09 0;
BA_ "GenSigCycleTime" SG_ 1681 MODULE_TEMP_03_09 40;
BA_ "FlexKomSigStartValue" SG_ 1681 MODULE_TEMP_03_09 "00h";
BA_ "GenSigTimeout_BMU" SG_ 1681 MODULE_TEMP_03_09 220;
BA_ "FlexKomSID" SG_ 1681 MODULE_TEMP_03_09 1071;
BA_ "FlexKomSigStartPos" SG_ 1681 MODULE_TEMP_03_09 39;
BA_ "FlexKomSigLaenge" SG_ 1681 MODULE_TEMP_03_09 8;
BA_ "FlexKomSigName" SG_ 1681 MODULE_TEMP_03_09 "MODULE_TEMP_03_09";
BA_ "FlexKomComment" SG_ 1681 MODULE_TEMP_03_09 "Module temperature03";
BA_ "FlexKomIsMotorola" SG_ 1681 MODULE_TEMP_03_09 1;
BA_ "GenSigSendType" SG_ 1681 MODULE_TEMP_02_09 0;
BA_ "GenSigCycleTime" SG_ 1681 MODULE_TEMP_02_09 40;
BA_ "FlexKomSigStartValue" SG_ 1681 MODULE_TEMP_02_09 "00h";
BA_ "GenSigTimeout_BMU" SG_ 1681 MODULE_TEMP_02_09 220;
BA_ "FlexKomSID" SG_ 1681 MODULE_TEMP_02_09 1059;
BA_ "FlexKomSigStartPos" SG_ 1681 MODULE_TEMP_02_09 31;
BA_ "FlexKomSigLaenge" SG_ 1681 MODULE_TEMP_02_09 8;
BA_ "FlexKomSigName" SG_ 1681 MODULE_TEMP_02_09 "MODULE_TEMP_02_09";
BA_ "FlexKomComment" SG_ 1681 MODULE_TEMP_02_09 "Module temperature02";
BA_ "FlexKomIsMotorola" SG_ 1681 MODULE_TEMP_02_09 1;
BA_ "GenSigSendType" SG_ 1681 MODULE_TEMP_01_09 0;
BA_ "GenSigCycleTime" SG_ 1681 MODULE_TEMP_01_09 40;
BA_ "FlexKomSigStartValue" SG_ 1681 MODULE_TEMP_01_09 "00h";
BA_ "GenSigTimeout_BMU" SG_ 1681 MODULE_TEMP_01_09 220;
BA_ "FlexKomSID" SG_ 1681 MODULE_TEMP_01_09 1047;
BA_ "FlexKomSigStartPos" SG_ 1681 MODULE_TEMP_01_09 23;
BA_ "FlexKomSigLaenge" SG_ 1681 MODULE_TEMP_01_09 8;
BA_ "FlexKomSigName" SG_ 1681 MODULE_TEMP_01_09 "MODULE_TEMP_01_09";
BA_ "FlexKomComment" SG_ 1681 MODULE_TEMP_01_09 "Module temperature01";
BA_ "FlexKomIsMotorola" SG_ 1681 MODULE_TEMP_01_09 1;
BA_ "GenSigSendType" SG_ 1681 NUM_TABLE_VALUE_09 0;
BA_ "GenSigCycleTime" SG_ 1681 NUM_TABLE_VALUE_09 40;
BA_ "FlexKomSigStartValue" SG_ 1681 NUM_TABLE_VALUE_09 "0Fh";
BA_ "GenSigStartValue" SG_ 1681 NUM_TABLE_VALUE_09 15;
BA_ "GenSigTimeout_BMU" SG_ 1681 NUM_TABLE_VALUE_09 220;
BA_ "FlexKomSID" SG_ 1681 NUM_TABLE_VALUE_09 1035;
BA_ "FlexKomSigStartPos" SG_ 1681 NUM_TABLE_VALUE_09 15;
BA_ "FlexKomSigLaenge" SG_ 1681 NUM_TABLE_VALUE_09 4;
BA_ "FlexKomSigName" SG_ 1681 NUM_TABLE_VALUE_09 "NUM_TABLE_VALUE_09";
BA_ "FlexKomComment" SG_ 1681 NUM_TABLE_VALUE_09 "Stored Automatic numbering table";
BA_ "FlexKomIsMotorola" SG_ 1681 NUM_TABLE_VALUE_09 1;
BA_ "GenSigSendType" SG_ 1681 BLC_DRV_STAT_12_09 0;
BA_ "GenSigCycleTime" SG_ 1681 BLC_DRV_STAT_12_09 40;
BA_ "FlexKomSigStartValue" SG_ 1681 BLC_DRV_STAT_12_09 "0000h";
BA_ "GenSigTimeout_BMU" SG_ 1681 BLC_DRV_STAT_12_09 220;
BA_ "FlexKomSID" SG_ 1681 BLC_DRV_STAT_12_09 729;
BA_ "FlexKomSigStartPos" SG_ 1681 BLC_DRV_STAT_12_09 7;
BA_ "FlexKomSigLaenge" SG_ 1681 BLC_DRV_STAT_12_09 16;
BA_ "FlexKomSigName" SG_ 1681 BLC_DRV_STAT_12_09 "BLC_DRV_STAT_09";
BA_ "FlexKomComment" SG_ 1681 BLC_DRV_STAT_12_09 "Balancer drive status packet";
BA_ "FlexKomIsMotorola" SG_ 1681 BLC_DRV_STAT_12_09 1;
BA_ "GenSigSendType" SG_ 1681 BLC_DRV_STAT_11_09 0;
BA_ "GenSigCycleTime" SG_ 1681 BLC_DRV_STAT_11_09 40;
BA_ "FlexKomSigStartValue" SG_ 1681 BLC_DRV_STAT_11_09 "0000h";
BA_ "GenSigTimeout_BMU" SG_ 1681 BLC_DRV_STAT_11_09 220;
BA_ "FlexKomSID" SG_ 1681 BLC_DRV_STAT_11_09 729;
BA_ "FlexKomSigStartPos" SG_ 1681 BLC_DRV_STAT_11_09 7;
BA_ "FlexKomSigLaenge" SG_ 1681 BLC_DRV_STAT_11_09 16;
BA_ "FlexKomSigName" SG_ 1681 BLC_DRV_STAT_11_09 "BLC_DRV_STAT_09";
BA_ "FlexKomComment" SG_ 1681 BLC_DRV_STAT_11_09 "Balancer drive status packet";
BA_ "FlexKomIsMotorola" SG_ 1681 BLC_DRV_STAT_11_09 1;
BA_ "GenSigSendType" SG_ 1681 BLC_DRV_STAT_10_09 0;
BA_ "GenSigCycleTime" SG_ 1681 BLC_DRV_STAT_10_09 40;
BA_ "FlexKomSigStartValue" SG_ 1681 BLC_DRV_STAT_10_09 "0000h";
BA_ "GenSigTimeout_BMU" SG_ 1681 BLC_DRV_STAT_10_09 220;
BA_ "FlexKomSID" SG_ 1681 BLC_DRV_STAT_10_09 729;
BA_ "FlexKomSigStartPos" SG_ 1681 BLC_DRV_STAT_10_09 7;
BA_ "FlexKomSigLaenge" SG_ 1681 BLC_DRV_STAT_10_09 16;
BA_ "FlexKomSigName" SG_ 1681 BLC_DRV_STAT_10_09 "BLC_DRV_STAT_09";
BA_ "FlexKomComment" SG_ 1681 BLC_DRV_STAT_10_09 "Balancer drive status packet";
BA_ "FlexKomIsMotorola" SG_ 1681 BLC_DRV_STAT_10_09 1;
BA_ "GenSigSendType" SG_ 1681 BLC_DRV_STAT_09_09 0;
BA_ "GenSigCycleTime" SG_ 1681 BLC_DRV_STAT_09_09 40;
BA_ "FlexKomSigStartValue" SG_ 1681 BLC_DRV_STAT_09_09 "0000h";
BA_ "GenSigTimeout_BMU" SG_ 1681 BLC_DRV_STAT_09_09 220;
BA_ "FlexKomSID" SG_ 1681 BLC_DRV_STAT_09_09 729;
BA_ "FlexKomSigStartPos" SG_ 1681 BLC_DRV_STAT_09_09 7;
BA_ "FlexKomSigLaenge" SG_ 1681 BLC_DRV_STAT_09_09 16;
BA_ "FlexKomSigName" SG_ 1681 BLC_DRV_STAT_09_09 "BLC_DRV_STAT_09";
BA_ "FlexKomComment" SG_ 1681 BLC_DRV_STAT_09_09 "Balancer drive status packet";
BA_ "FlexKomIsMotorola" SG_ 1681 BLC_DRV_STAT_09_09 1;
BA_ "GenSigSendType" SG_ 1681 BLC_DRV_STAT_08_09 0;
BA_ "GenSigCycleTime" SG_ 1681 BLC_DRV_STAT_08_09 40;
BA_ "FlexKomSigStartValue" SG_ 1681 BLC_DRV_STAT_08_09 "0000h";
BA_ "GenSigTimeout_BMU" SG_ 1681 BLC_DRV_STAT_08_09 220;
BA_ "FlexKomSID" SG_ 1681 BLC_DRV_STAT_08_09 729;
BA_ "FlexKomSigStartPos" SG_ 1681 BLC_DRV_STAT_08_09 7;
BA_ "FlexKomSigLaenge" SG_ 1681 BLC_DRV_STAT_08_09 16;
BA_ "FlexKomSigName" SG_ 1681 BLC_DRV_STAT_08_09 "BLC_DRV_STAT_09";
BA_ "FlexKomComment" SG_ 1681 BLC_DRV_STAT_08_09 "Balancer drive status packet";
BA_ "FlexKomIsMotorola" SG_ 1681 BLC_DRV_STAT_08_09 1;
BA_ "GenSigSendType" SG_ 1681 BLC_DRV_STAT_07_09 0;
BA_ "GenSigCycleTime" SG_ 1681 BLC_DRV_STAT_07_09 40;
BA_ "FlexKomSigStartValue" SG_ 1681 BLC_DRV_STAT_07_09 "0000h";
BA_ "GenSigTimeout_BMU" SG_ 1681 BLC_DRV_STAT_07_09 220;
BA_ "FlexKomSID" SG_ 1681 BLC_DRV_STAT_07_09 729;
BA_ "FlexKomSigStartPos" SG_ 1681 BLC_DRV_STAT_07_09 7;
BA_ "FlexKomSigLaenge" SG_ 1681 BLC_DRV_STAT_07_09 16;
BA_ "FlexKomSigName" SG_ 1681 BLC_DRV_STAT_07_09 "BLC_DRV_STAT_09";
BA_ "FlexKomComment" SG_ 1681 BLC_DRV_STAT_07_09 "Balancer drive status packet";
BA_ "FlexKomIsMotorola" SG_ 1681 BLC_DRV_STAT_07_09 1;
BA_ "GenSigSendType" SG_ 1681 BLC_DRV_STAT_06_09 0;
BA_ "GenSigCycleTime" SG_ 1681 BLC_DRV_STAT_06_09 40;
BA_ "FlexKomSigStartValue" SG_ 1681 BLC_DRV_STAT_06_09 "0000h";
BA_ "GenSigTimeout_BMU" SG_ 1681 BLC_DRV_STAT_06_09 220;
BA_ "FlexKomSID" SG_ 1681 BLC_DRV_STAT_06_09 729;
BA_ "FlexKomSigStartPos" SG_ 1681 BLC_DRV_STAT_06_09 7;
BA_ "FlexKomSigLaenge" SG_ 1681 BLC_DRV_STAT_06_09 16;
BA_ "FlexKomSigName" SG_ 1681 BLC_DRV_STAT_06_09 "BLC_DRV_STAT_09";
BA_ "FlexKomComment" SG_ 1681 BLC_DRV_STAT_06_09 "Balancer drive status packet";
BA_ "FlexKomIsMotorola" SG_ 1681 BLC_DRV_STAT_06_09 1;
BA_ "GenSigSendType" SG_ 1681 BLC_DRV_STAT_05_09 0;
BA_ "GenSigCycleTime" SG_ 1681 BLC_DRV_STAT_05_09 40;
BA_ "FlexKomSigStartValue" SG_ 1681 BLC_DRV_STAT_05_09 "0000h";
BA_ "GenSigTimeout_BMU" SG_ 1681 BLC_DRV_STAT_05_09 220;
BA_ "FlexKomSID" SG_ 1681 BLC_DRV_STAT_05_09 729;
BA_ "FlexKomSigStartPos" SG_ 1681 BLC_DRV_STAT_05_09 7;
BA_ "FlexKomSigLaenge" SG_ 1681 BLC_DRV_STAT_05_09 16;
BA_ "FlexKomSigName" SG_ 1681 BLC_DRV_STAT_05_09 "BLC_DRV_STAT_09";
BA_ "FlexKomComment" SG_ 1681 BLC_DRV_STAT_05_09 "Balancer drive status packet";
BA_ "FlexKomIsMotorola" SG_ 1681 BLC_DRV_STAT_05_09 1;
BA_ "GenSigSendType" SG_ 1681 BLC_DRV_STAT_04_09 0;
BA_ "GenSigCycleTime" SG_ 1681 BLC_DRV_STAT_04_09 40;
BA_ "FlexKomSigStartValue" SG_ 1681 BLC_DRV_STAT_04_09 "0000h";
BA_ "GenSigTimeout_BMU" SG_ 1681 BLC_DRV_STAT_04_09 220;
BA_ "FlexKomSID" SG_ 1681 BLC_DRV_STAT_04_09 729;
BA_ "FlexKomSigStartPos" SG_ 1681 BLC_DRV_STAT_04_09 7;
BA_ "FlexKomSigLaenge" SG_ 1681 BLC_DRV_STAT_04_09 16;
BA_ "FlexKomSigName" SG_ 1681 BLC_DRV_STAT_04_09 "BLC_DRV_STAT_09";
BA_ "FlexKomComment" SG_ 1681 BLC_DRV_STAT_04_09 "Balancer drive status packet";
BA_ "FlexKomIsMotorola" SG_ 1681 BLC_DRV_STAT_04_09 1;
BA_ "GenSigSendType" SG_ 1681 BLC_DRV_STAT_03_09 0;
BA_ "GenSigCycleTime" SG_ 1681 BLC_DRV_STAT_03_09 40;
BA_ "FlexKomSigStartValue" SG_ 1681 BLC_DRV_STAT_03_09 "0000h";
BA_ "GenSigTimeout_BMU" SG_ 1681 BLC_DRV_STAT_03_09 220;
BA_ "FlexKomSID" SG_ 1681 BLC_DRV_STAT_03_09 729;
BA_ "FlexKomSigStartPos" SG_ 1681 BLC_DRV_STAT_03_09 7;
BA_ "FlexKomSigLaenge" SG_ 1681 BLC_DRV_STAT_03_09 16;
BA_ "FlexKomSigName" SG_ 1681 BLC_DRV_STAT_03_09 "BLC_DRV_STAT_09";
BA_ "FlexKomComment" SG_ 1681 BLC_DRV_STAT_03_09 "Balancer drive status packet";
BA_ "FlexKomIsMotorola" SG_ 1681 BLC_DRV_STAT_03_09 1;
BA_ "GenSigSendType" SG_ 1681 BLC_DRV_STAT_02_09 0;
BA_ "GenSigCycleTime" SG_ 1681 BLC_DRV_STAT_02_09 40;
BA_ "FlexKomSigStartValue" SG_ 1681 BLC_DRV_STAT_02_09 "0000h";
BA_ "GenSigTimeout_BMU" SG_ 1681 BLC_DRV_STAT_02_09 220;
BA_ "FlexKomSID" SG_ 1681 BLC_DRV_STAT_02_09 729;
BA_ "FlexKomSigStartPos" SG_ 1681 BLC_DRV_STAT_02_09 7;
BA_ "FlexKomSigLaenge" SG_ 1681 BLC_DRV_STAT_02_09 16;
BA_ "FlexKomSigName" SG_ 1681 BLC_DRV_STAT_02_09 "BLC_DRV_STAT_09";
BA_ "FlexKomComment" SG_ 1681 BLC_DRV_STAT_02_09 "Balancer drive status packet";
BA_ "FlexKomIsMotorola" SG_ 1681 BLC_DRV_STAT_02_09 1;
BA_ "GenSigSendType" SG_ 1681 BLC_DRV_STAT_01_09 0;
BA_ "GenSigCycleTime" SG_ 1681 BLC_DRV_STAT_01_09 40;
BA_ "FlexKomSigStartValue" SG_ 1681 BLC_DRV_STAT_01_09 "0000h";
BA_ "GenSigTimeout_BMU" SG_ 1681 BLC_DRV_STAT_01_09 220;
BA_ "FlexKomSID" SG_ 1681 BLC_DRV_STAT_01_09 729;
BA_ "FlexKomSigStartPos" SG_ 1681 BLC_DRV_STAT_01_09 7;
BA_ "FlexKomSigLaenge" SG_ 1681 BLC_DRV_STAT_01_09 16;
BA_ "FlexKomSigName" SG_ 1681 BLC_DRV_STAT_01_09 "BLC_DRV_STAT_09";
BA_ "FlexKomComment" SG_ 1681 BLC_DRV_STAT_01_09 "Balancer drive status packet";
BA_ "FlexKomIsMotorola" SG_ 1681 BLC_DRV_STAT_01_09 1;
BA_ "GenSigSendType" SG_ 1665 MODULE_TEMP_06_08 0;
BA_ "GenSigCycleTime" SG_ 1665 MODULE_TEMP_06_08 40;
BA_ "FlexKomSigStartValue" SG_ 1665 MODULE_TEMP_06_08 "00h";
BA_ "FlexKomSID" SG_ 1665 MODULE_TEMP_06_08 1106;
BA_ "FlexKomSigStartPos" SG_ 1665 MODULE_TEMP_06_08 63;
BA_ "FlexKomSigLaenge" SG_ 1665 MODULE_TEMP_06_08 8;
BA_ "FlexKomSigName" SG_ 1665 MODULE_TEMP_06_08 "MODULE_TEMP_06_08";
BA_ "FlexKomComment" SG_ 1665 MODULE_TEMP_06_08 "Module temperature06";
BA_ "FlexKomIsMotorola" SG_ 1665 MODULE_TEMP_06_08 1;
BA_ "GenSigSendType" SG_ 1665 MODULE_TEMP_05_08 0;
BA_ "GenSigCycleTime" SG_ 1665 MODULE_TEMP_05_08 40;
BA_ "FlexKomSigStartValue" SG_ 1665 MODULE_TEMP_05_08 "00h";
BA_ "GenSigTimeout_BMU" SG_ 1665 MODULE_TEMP_05_08 220;
BA_ "FlexKomSID" SG_ 1665 MODULE_TEMP_05_08 1094;
BA_ "FlexKomSigStartPos" SG_ 1665 MODULE_TEMP_05_08 55;
BA_ "FlexKomSigLaenge" SG_ 1665 MODULE_TEMP_05_08 8;
BA_ "FlexKomSigName" SG_ 1665 MODULE_TEMP_05_08 "MODULE_TEMP_05_08";
BA_ "FlexKomComment" SG_ 1665 MODULE_TEMP_05_08 "Module temperature05";
BA_ "FlexKomIsMotorola" SG_ 1665 MODULE_TEMP_05_08 1;
BA_ "GenSigSendType" SG_ 1665 MODULE_TEMP_04_08 0;
BA_ "GenSigCycleTime" SG_ 1665 MODULE_TEMP_04_08 40;
BA_ "FlexKomSigStartValue" SG_ 1665 MODULE_TEMP_04_08 "00h";
BA_ "GenSigTimeout_BMU" SG_ 1665 MODULE_TEMP_04_08 220;
BA_ "FlexKomSID" SG_ 1665 MODULE_TEMP_04_08 1082;
BA_ "FlexKomSigStartPos" SG_ 1665 MODULE_TEMP_04_08 47;
BA_ "FlexKomSigLaenge" SG_ 1665 MODULE_TEMP_04_08 8;
BA_ "FlexKomSigName" SG_ 1665 MODULE_TEMP_04_08 "MODULE_TEMP_04_08";
BA_ "FlexKomComment" SG_ 1665 MODULE_TEMP_04_08 "Module temperature04";
BA_ "FlexKomIsMotorola" SG_ 1665 MODULE_TEMP_04_08 1;
BA_ "GenSigSendType" SG_ 1665 MODULE_TEMP_03_08 0;
BA_ "GenSigCycleTime" SG_ 1665 MODULE_TEMP_03_08 40;
BA_ "FlexKomSigStartValue" SG_ 1665 MODULE_TEMP_03_08 "00h";
BA_ "GenSigTimeout_BMU" SG_ 1665 MODULE_TEMP_03_08 220;
BA_ "FlexKomSID" SG_ 1665 MODULE_TEMP_03_08 1070;
BA_ "FlexKomSigStartPos" SG_ 1665 MODULE_TEMP_03_08 39;
BA_ "FlexKomSigLaenge" SG_ 1665 MODULE_TEMP_03_08 8;
BA_ "FlexKomSigName" SG_ 1665 MODULE_TEMP_03_08 "MODULE_TEMP_03_08";
BA_ "FlexKomComment" SG_ 1665 MODULE_TEMP_03_08 "Module temperature03";
BA_ "FlexKomIsMotorola" SG_ 1665 MODULE_TEMP_03_08 1;
BA_ "GenSigSendType" SG_ 1665 MODULE_TEMP_02_08 0;
BA_ "GenSigCycleTime" SG_ 1665 MODULE_TEMP_02_08 40;
BA_ "FlexKomSigStartValue" SG_ 1665 MODULE_TEMP_02_08 "00h";
BA_ "GenSigTimeout_BMU" SG_ 1665 MODULE_TEMP_02_08 220;
BA_ "FlexKomSID" SG_ 1665 MODULE_TEMP_02_08 1058;
BA_ "FlexKomSigStartPos" SG_ 1665 MODULE_TEMP_02_08 31;
BA_ "FlexKomSigLaenge" SG_ 1665 MODULE_TEMP_02_08 8;
BA_ "FlexKomSigName" SG_ 1665 MODULE_TEMP_02_08 "MODULE_TEMP_02_08";
BA_ "FlexKomComment" SG_ 1665 MODULE_TEMP_02_08 "Module temperature02";
BA_ "FlexKomIsMotorola" SG_ 1665 MODULE_TEMP_02_08 1;
BA_ "GenSigSendType" SG_ 1665 MODULE_TEMP_01_08 0;
BA_ "GenSigCycleTime" SG_ 1665 MODULE_TEMP_01_08 40;
BA_ "FlexKomSigStartValue" SG_ 1665 MODULE_TEMP_01_08 "00h";
BA_ "GenSigTimeout_BMU" SG_ 1665 MODULE_TEMP_01_08 220;
BA_ "FlexKomSID" SG_ 1665 MODULE_TEMP_01_08 1046;
BA_ "FlexKomSigStartPos" SG_ 1665 MODULE_TEMP_01_08 23;
BA_ "FlexKomSigLaenge" SG_ 1665 MODULE_TEMP_01_08 8;
BA_ "FlexKomSigName" SG_ 1665 MODULE_TEMP_01_08 "MODULE_TEMP_01_08";
BA_ "FlexKomComment" SG_ 1665 MODULE_TEMP_01_08 "Module temperature01";
BA_ "FlexKomIsMotorola" SG_ 1665 MODULE_TEMP_01_08 1;
BA_ "GenSigSendType" SG_ 1665 NUM_TABLE_VALUE_08 0;
BA_ "GenSigCycleTime" SG_ 1665 NUM_TABLE_VALUE_08 40;
BA_ "FlexKomSigStartValue" SG_ 1665 NUM_TABLE_VALUE_08 "0Fh";
BA_ "GenSigStartValue" SG_ 1665 NUM_TABLE_VALUE_08 15;
BA_ "GenSigTimeout_BMU" SG_ 1665 NUM_TABLE_VALUE_08 220;
BA_ "FlexKomSID" SG_ 1665 NUM_TABLE_VALUE_08 1034;
BA_ "FlexKomSigStartPos" SG_ 1665 NUM_TABLE_VALUE_08 15;
BA_ "FlexKomSigLaenge" SG_ 1665 NUM_TABLE_VALUE_08 4;
BA_ "FlexKomSigName" SG_ 1665 NUM_TABLE_VALUE_08 "NUM_TABLE_VALUE_08";
BA_ "FlexKomComment" SG_ 1665 NUM_TABLE_VALUE_08 "Stored Automatic numbering table";
BA_ "FlexKomIsMotorola" SG_ 1665 NUM_TABLE_VALUE_08 1;
BA_ "GenSigSendType" SG_ 1665 BLC_DRV_STAT_12_08 0;
BA_ "GenSigCycleTime" SG_ 1665 BLC_DRV_STAT_12_08 40;
BA_ "FlexKomSigStartValue" SG_ 1665 BLC_DRV_STAT_12_08 "0000h";
BA_ "GenSigTimeout_BMU" SG_ 1665 BLC_DRV_STAT_12_08 220;
BA_ "FlexKomSID" SG_ 1665 BLC_DRV_STAT_12_08 732;
BA_ "FlexKomSigStartPos" SG_ 1665 BLC_DRV_STAT_12_08 7;
BA_ "FlexKomSigLaenge" SG_ 1665 BLC_DRV_STAT_12_08 16;
BA_ "FlexKomSigName" SG_ 1665 BLC_DRV_STAT_12_08 "BLC_DRV_STAT_08";
BA_ "FlexKomComment" SG_ 1665 BLC_DRV_STAT_12_08 "Balancer drive status packet";
BA_ "FlexKomIsMotorola" SG_ 1665 BLC_DRV_STAT_12_08 1;
BA_ "GenSigSendType" SG_ 1665 BLC_DRV_STAT_11_08 0;
BA_ "GenSigCycleTime" SG_ 1665 BLC_DRV_STAT_11_08 40;
BA_ "FlexKomSigStartValue" SG_ 1665 BLC_DRV_STAT_11_08 "0000h";
BA_ "GenSigTimeout_BMU" SG_ 1665 BLC_DRV_STAT_11_08 220;
BA_ "FlexKomSID" SG_ 1665 BLC_DRV_STAT_11_08 732;
BA_ "FlexKomSigStartPos" SG_ 1665 BLC_DRV_STAT_11_08 7;
BA_ "FlexKomSigLaenge" SG_ 1665 BLC_DRV_STAT_11_08 16;
BA_ "FlexKomSigName" SG_ 1665 BLC_DRV_STAT_11_08 "BLC_DRV_STAT_08";
BA_ "FlexKomComment" SG_ 1665 BLC_DRV_STAT_11_08 "Balancer drive status packet";
BA_ "FlexKomIsMotorola" SG_ 1665 BLC_DRV_STAT_11_08 1;
BA_ "GenSigSendType" SG_ 1665 BLC_DRV_STAT_10_08 0;
BA_ "GenSigCycleTime" SG_ 1665 BLC_DRV_STAT_10_08 40;
BA_ "FlexKomSigStartValue" SG_ 1665 BLC_DRV_STAT_10_08 "0000h";
BA_ "GenSigTimeout_BMU" SG_ 1665 BLC_DRV_STAT_10_08 220;
BA_ "FlexKomSID" SG_ 1665 BLC_DRV_STAT_10_08 732;
BA_ "FlexKomSigStartPos" SG_ 1665 BLC_DRV_STAT_10_08 7;
BA_ "FlexKomSigLaenge" SG_ 1665 BLC_DRV_STAT_10_08 16;
BA_ "FlexKomSigName" SG_ 1665 BLC_DRV_STAT_10_08 "BLC_DRV_STAT_08";
BA_ "FlexKomComment" SG_ 1665 BLC_DRV_STAT_10_08 "Balancer drive status packet";
BA_ "FlexKomIsMotorola" SG_ 1665 BLC_DRV_STAT_10_08 1;
BA_ "GenSigSendType" SG_ 1665 BLC_DRV_STAT_09_08 0;
BA_ "GenSigCycleTime" SG_ 1665 BLC_DRV_STAT_09_08 40;
BA_ "FlexKomSigStartValue" SG_ 1665 BLC_DRV_STAT_09_08 "0000h";
BA_ "GenSigTimeout_BMU" SG_ 1665 BLC_DRV_STAT_09_08 220;
BA_ "FlexKomSID" SG_ 1665 BLC_DRV_STAT_09_08 732;
BA_ "FlexKomSigStartPos" SG_ 1665 BLC_DRV_STAT_09_08 7;
BA_ "FlexKomSigLaenge" SG_ 1665 BLC_DRV_STAT_09_08 16;
BA_ "FlexKomSigName" SG_ 1665 BLC_DRV_STAT_09_08 "BLC_DRV_STAT_08";
BA_ "FlexKomComment" SG_ 1665 BLC_DRV_STAT_09_08 "Balancer drive status packet";
BA_ "FlexKomIsMotorola" SG_ 1665 BLC_DRV_STAT_09_08 1;
BA_ "GenSigSendType" SG_ 1665 BLC_DRV_STAT_08_08 0;
BA_ "GenSigCycleTime" SG_ 1665 BLC_DRV_STAT_08_08 40;
BA_ "FlexKomSigStartValue" SG_ 1665 BLC_DRV_STAT_08_08 "0000h";
BA_ "GenSigTimeout_BMU" SG_ 1665 BLC_DRV_STAT_08_08 220;
BA_ "FlexKomSID" SG_ 1665 BLC_DRV_STAT_08_08 732;
BA_ "FlexKomSigStartPos" SG_ 1665 BLC_DRV_STAT_08_08 7;
BA_ "FlexKomSigLaenge" SG_ 1665 BLC_DRV_STAT_08_08 16;
BA_ "FlexKomSigName" SG_ 1665 BLC_DRV_STAT_08_08 "BLC_DRV_STAT_08";
BA_ "FlexKomComment" SG_ 1665 BLC_DRV_STAT_08_08 "Balancer drive status packet";
BA_ "FlexKomIsMotorola" SG_ 1665 BLC_DRV_STAT_08_08 1;
BA_ "GenSigSendType" SG_ 1665 BLC_DRV_STAT_07_08 0;
BA_ "GenSigCycleTime" SG_ 1665 BLC_DRV_STAT_07_08 40;
BA_ "FlexKomSigStartValue" SG_ 1665 BLC_DRV_STAT_07_08 "0000h";
BA_ "GenSigTimeout_BMU" SG_ 1665 BLC_DRV_STAT_07_08 220;
BA_ "FlexKomSID" SG_ 1665 BLC_DRV_STAT_07_08 732;
BA_ "FlexKomSigStartPos" SG_ 1665 BLC_DRV_STAT_07_08 7;
BA_ "FlexKomSigLaenge" SG_ 1665 BLC_DRV_STAT_07_08 16;
BA_ "FlexKomSigName" SG_ 1665 BLC_DRV_STAT_07_08 "BLC_DRV_STAT_08";
BA_ "FlexKomComment" SG_ 1665 BLC_DRV_STAT_07_08 "Balancer drive status packet";
BA_ "FlexKomIsMotorola" SG_ 1665 BLC_DRV_STAT_07_08 1;
BA_ "GenSigSendType" SG_ 1665 BLC_DRV_STAT_06_08 0;
BA_ "GenSigCycleTime" SG_ 1665 BLC_DRV_STAT_06_08 40;
BA_ "FlexKomSigStartValue" SG_ 1665 BLC_DRV_STAT_06_08 "0000h";
BA_ "GenSigTimeout_BMU" SG_ 1665 BLC_DRV_STAT_06_08 220;
BA_ "FlexKomSID" SG_ 1665 BLC_DRV_STAT_06_08 732;
BA_ "FlexKomSigStartPos" SG_ 1665 BLC_DRV_STAT_06_08 7;
BA_ "FlexKomSigLaenge" SG_ 1665 BLC_DRV_STAT_06_08 16;
BA_ "FlexKomSigName" SG_ 1665 BLC_DRV_STAT_06_08 "BLC_DRV_STAT_08";
BA_ "FlexKomComment" SG_ 1665 BLC_DRV_STAT_06_08 "Balancer drive status packet";
BA_ "FlexKomIsMotorola" SG_ 1665 BLC_DRV_STAT_06_08 1;
BA_ "GenSigSendType" SG_ 1665 BLC_DRV_STAT_05_08 0;
BA_ "GenSigCycleTime" SG_ 1665 BLC_DRV_STAT_05_08 40;
BA_ "FlexKomSigStartValue" SG_ 1665 BLC_DRV_STAT_05_08 "0000h";
BA_ "GenSigTimeout_BMU" SG_ 1665 BLC_DRV_STAT_05_08 220;
BA_ "FlexKomSID" SG_ 1665 BLC_DRV_STAT_05_08 732;
BA_ "FlexKomSigStartPos" SG_ 1665 BLC_DRV_STAT_05_08 7;
BA_ "FlexKomSigLaenge" SG_ 1665 BLC_DRV_STAT_05_08 16;
BA_ "FlexKomSigName" SG_ 1665 BLC_DRV_STAT_05_08 "BLC_DRV_STAT_08";
BA_ "FlexKomComment" SG_ 1665 BLC_DRV_STAT_05_08 "Balancer drive status packet";
BA_ "FlexKomIsMotorola" SG_ 1665 BLC_DRV_STAT_05_08 1;
BA_ "GenSigSendType" SG_ 1665 BLC_DRV_STAT_04_08 0;
BA_ "GenSigCycleTime" SG_ 1665 BLC_DRV_STAT_04_08 40;
BA_ "FlexKomSigStartValue" SG_ 1665 BLC_DRV_STAT_04_08 "0000h";
BA_ "GenSigTimeout_BMU" SG_ 1665 BLC_DRV_STAT_04_08 220;
BA_ "FlexKomSID" SG_ 1665 BLC_DRV_STAT_04_08 732;
BA_ "FlexKomSigStartPos" SG_ 1665 BLC_DRV_STAT_04_08 7;
BA_ "FlexKomSigLaenge" SG_ 1665 BLC_DRV_STAT_04_08 16;
BA_ "FlexKomSigName" SG_ 1665 BLC_DRV_STAT_04_08 "BLC_DRV_STAT_08";
BA_ "FlexKomComment" SG_ 1665 BLC_DRV_STAT_04_08 "Balancer drive status packet";
BA_ "FlexKomIsMotorola" SG_ 1665 BLC_DRV_STAT_04_08 1;
BA_ "GenSigSendType" SG_ 1665 BLC_DRV_STAT_03_08 0;
BA_ "GenSigCycleTime" SG_ 1665 BLC_DRV_STAT_03_08 40;
BA_ "FlexKomSigStartValue" SG_ 1665 BLC_DRV_STAT_03_08 "0000h";
BA_ "GenSigTimeout_BMU" SG_ 1665 BLC_DRV_STAT_03_08 220;
BA_ "FlexKomSID" SG_ 1665 BLC_DRV_STAT_03_08 732;
BA_ "FlexKomSigStartPos" SG_ 1665 BLC_DRV_STAT_03_08 7;
BA_ "FlexKomSigLaenge" SG_ 1665 BLC_DRV_STAT_03_08 16;
BA_ "FlexKomSigName" SG_ 1665 BLC_DRV_STAT_03_08 "BLC_DRV_STAT_08";
BA_ "FlexKomComment" SG_ 1665 BLC_DRV_STAT_03_08 "Balancer drive status packet";
BA_ "FlexKomIsMotorola" SG_ 1665 BLC_DRV_STAT_03_08 1;
BA_ "GenSigSendType" SG_ 1665 BLC_DRV_STAT_02_08 0;
BA_ "GenSigCycleTime" SG_ 1665 BLC_DRV_STAT_02_08 40;
BA_ "FlexKomSigStartValue" SG_ 1665 BLC_DRV_STAT_02_08 "0000h";
BA_ "GenSigTimeout_BMU" SG_ 1665 BLC_DRV_STAT_02_08 220;
BA_ "FlexKomSID" SG_ 1665 BLC_DRV_STAT_02_08 732;
BA_ "FlexKomSigStartPos" SG_ 1665 BLC_DRV_STAT_02_08 7;
BA_ "FlexKomSigLaenge" SG_ 1665 BLC_DRV_STAT_02_08 16;
BA_ "FlexKomSigName" SG_ 1665 BLC_DRV_STAT_02_08 "BLC_DRV_STAT_08";
BA_ "FlexKomComment" SG_ 1665 BLC_DRV_STAT_02_08 "Balancer drive status packet";
BA_ "FlexKomIsMotorola" SG_ 1665 BLC_DRV_STAT_02_08 1;
BA_ "GenSigSendType" SG_ 1665 BLC_DRV_STAT_01_08 0;
BA_ "GenSigCycleTime" SG_ 1665 BLC_DRV_STAT_01_08 40;
BA_ "FlexKomSigStartValue" SG_ 1665 BLC_DRV_STAT_01_08 "0000h";
BA_ "GenSigTimeout_BMU" SG_ 1665 BLC_DRV_STAT_01_08 220;
BA_ "FlexKomSID" SG_ 1665 BLC_DRV_STAT_01_08 732;
BA_ "FlexKomSigStartPos" SG_ 1665 BLC_DRV_STAT_01_08 7;
BA_ "FlexKomSigLaenge" SG_ 1665 BLC_DRV_STAT_01_08 16;
BA_ "FlexKomSigName" SG_ 1665 BLC_DRV_STAT_01_08 "BLC_DRV_STAT_08";
BA_ "FlexKomComment" SG_ 1665 BLC_DRV_STAT_01_08 "Balancer drive status packet";
BA_ "FlexKomIsMotorola" SG_ 1665 BLC_DRV_STAT_01_08 1;
BA_ "GenSigSendType" SG_ 1649 MODULE_TEMP_06_07 0;
BA_ "GenSigCycleTime" SG_ 1649 MODULE_TEMP_06_07 40;
BA_ "FlexKomSigStartValue" SG_ 1649 MODULE_TEMP_06_07 "00h";
BA_ "GenSigTimeout_BMU" SG_ 1649 MODULE_TEMP_06_07 220;
BA_ "FlexKomSID" SG_ 1649 MODULE_TEMP_06_07 1105;
BA_ "FlexKomSigStartPos" SG_ 1649 MODULE_TEMP_06_07 63;
BA_ "FlexKomSigLaenge" SG_ 1649 MODULE_TEMP_06_07 8;
BA_ "FlexKomSigName" SG_ 1649 MODULE_TEMP_06_07 "MODULE_TEMP_06_07";
BA_ "FlexKomComment" SG_ 1649 MODULE_TEMP_06_07 "Module temperature06";
BA_ "FlexKomIsMotorola" SG_ 1649 MODULE_TEMP_06_07 1;
BA_ "GenSigSendType" SG_ 1649 MODULE_TEMP_05_07 0;
BA_ "GenSigCycleTime" SG_ 1649 MODULE_TEMP_05_07 40;
BA_ "FlexKomSigStartValue" SG_ 1649 MODULE_TEMP_05_07 "00h";
BA_ "GenSigTimeout_BMU" SG_ 1649 MODULE_TEMP_05_07 220;
BA_ "FlexKomSID" SG_ 1649 MODULE_TEMP_05_07 1093;
BA_ "FlexKomSigStartPos" SG_ 1649 MODULE_TEMP_05_07 55;
BA_ "FlexKomSigLaenge" SG_ 1649 MODULE_TEMP_05_07 8;
BA_ "FlexKomSigName" SG_ 1649 MODULE_TEMP_05_07 "MODULE_TEMP_05_07";
BA_ "FlexKomComment" SG_ 1649 MODULE_TEMP_05_07 "Module temperature05";
BA_ "FlexKomIsMotorola" SG_ 1649 MODULE_TEMP_05_07 1;
BA_ "GenSigSendType" SG_ 1649 MODULE_TEMP_04_07 0;
BA_ "GenSigCycleTime" SG_ 1649 MODULE_TEMP_04_07 40;
BA_ "FlexKomSigStartValue" SG_ 1649 MODULE_TEMP_04_07 "00h";
BA_ "GenSigTimeout_BMU" SG_ 1649 MODULE_TEMP_04_07 220;
BA_ "FlexKomSID" SG_ 1649 MODULE_TEMP_04_07 1081;
BA_ "FlexKomSigStartPos" SG_ 1649 MODULE_TEMP_04_07 47;
BA_ "FlexKomSigLaenge" SG_ 1649 MODULE_TEMP_04_07 8;
BA_ "FlexKomSigName" SG_ 1649 MODULE_TEMP_04_07 "MODULE_TEMP_04_07";
BA_ "FlexKomComment" SG_ 1649 MODULE_TEMP_04_07 "Module temperature04";
BA_ "FlexKomIsMotorola" SG_ 1649 MODULE_TEMP_04_07 1;
BA_ "GenSigSendType" SG_ 1649 MODULE_TEMP_03_07 0;
BA_ "GenSigCycleTime" SG_ 1649 MODULE_TEMP_03_07 40;
BA_ "FlexKomSigStartValue" SG_ 1649 MODULE_TEMP_03_07 "00h";
BA_ "GenSigTimeout_BMU" SG_ 1649 MODULE_TEMP_03_07 220;
BA_ "FlexKomSID" SG_ 1649 MODULE_TEMP_03_07 1069;
BA_ "FlexKomSigStartPos" SG_ 1649 MODULE_TEMP_03_07 39;
BA_ "FlexKomSigLaenge" SG_ 1649 MODULE_TEMP_03_07 8;
BA_ "FlexKomSigName" SG_ 1649 MODULE_TEMP_03_07 "MODULE_TEMP_03_07";
BA_ "FlexKomComment" SG_ 1649 MODULE_TEMP_03_07 "Module temperature03";
BA_ "FlexKomIsMotorola" SG_ 1649 MODULE_TEMP_03_07 1;
BA_ "GenSigSendType" SG_ 1649 MODULE_TEMP_02_07 0;
BA_ "GenSigCycleTime" SG_ 1649 MODULE_TEMP_02_07 40;
BA_ "FlexKomSigStartValue" SG_ 1649 MODULE_TEMP_02_07 "00h";
BA_ "GenSigTimeout_BMU" SG_ 1649 MODULE_TEMP_02_07 220;
BA_ "FlexKomSID" SG_ 1649 MODULE_TEMP_02_07 1057;
BA_ "FlexKomSigStartPos" SG_ 1649 MODULE_TEMP_02_07 31;
BA_ "FlexKomSigLaenge" SG_ 1649 MODULE_TEMP_02_07 8;
BA_ "FlexKomSigName" SG_ 1649 MODULE_TEMP_02_07 "MODULE_TEMP_02_07";
BA_ "FlexKomComment" SG_ 1649 MODULE_TEMP_02_07 "Module temperature02";
BA_ "FlexKomIsMotorola" SG_ 1649 MODULE_TEMP_02_07 1;
BA_ "GenSigSendType" SG_ 1649 MODULE_TEMP_01_07 0;
BA_ "GenSigCycleTime" SG_ 1649 MODULE_TEMP_01_07 40;
BA_ "FlexKomSigStartValue" SG_ 1649 MODULE_TEMP_01_07 "00h";
BA_ "GenSigTimeout_BMU" SG_ 1649 MODULE_TEMP_01_07 220;
BA_ "FlexKomSID" SG_ 1649 MODULE_TEMP_01_07 1045;
BA_ "FlexKomSigStartPos" SG_ 1649 MODULE_TEMP_01_07 23;
BA_ "FlexKomSigLaenge" SG_ 1649 MODULE_TEMP_01_07 8;
BA_ "FlexKomSigName" SG_ 1649 MODULE_TEMP_01_07 "MODULE_TEMP_01_07";
BA_ "FlexKomComment" SG_ 1649 MODULE_TEMP_01_07 "Module temperature01";
BA_ "FlexKomIsMotorola" SG_ 1649 MODULE_TEMP_01_07 1;
BA_ "GenSigSendType" SG_ 1649 NUM_TABLE_VALUE_07 0;
BA_ "GenSigCycleTime" SG_ 1649 NUM_TABLE_VALUE_07 40;
BA_ "FlexKomSigStartValue" SG_ 1649 NUM_TABLE_VALUE_07 "0Fh";
BA_ "GenSigStartValue" SG_ 1649 NUM_TABLE_VALUE_07 15;
BA_ "GenSigTimeout_BMU" SG_ 1649 NUM_TABLE_VALUE_07 220;
BA_ "FlexKomSID" SG_ 1649 NUM_TABLE_VALUE_07 1033;
BA_ "FlexKomSigStartPos" SG_ 1649 NUM_TABLE_VALUE_07 15;
BA_ "FlexKomSigLaenge" SG_ 1649 NUM_TABLE_VALUE_07 4;
BA_ "FlexKomSigName" SG_ 1649 NUM_TABLE_VALUE_07 "NUM_TABLE_VALUE_07";
BA_ "FlexKomComment" SG_ 1649 NUM_TABLE_VALUE_07 "Stored Automatic numbering table";
BA_ "FlexKomIsMotorola" SG_ 1649 NUM_TABLE_VALUE_07 1;
BA_ "GenSigSendType" SG_ 1649 BLC_DRV_STAT_12_07 0;
BA_ "GenSigCycleTime" SG_ 1649 BLC_DRV_STAT_12_07 40;
BA_ "FlexKomSigStartValue" SG_ 1649 BLC_DRV_STAT_12_07 "0000h";
BA_ "GenSigTimeout_BMU" SG_ 1649 BLC_DRV_STAT_12_07 220;
BA_ "FlexKomSID" SG_ 1649 BLC_DRV_STAT_12_07 731;
BA_ "FlexKomSigStartPos" SG_ 1649 BLC_DRV_STAT_12_07 7;
BA_ "FlexKomSigLaenge" SG_ 1649 BLC_DRV_STAT_12_07 16;
BA_ "FlexKomSigName" SG_ 1649 BLC_DRV_STAT_12_07 "BLC_DRV_STAT_07";
BA_ "FlexKomComment" SG_ 1649 BLC_DRV_STAT_12_07 "Balancer drive status packet";
BA_ "FlexKomIsMotorola" SG_ 1649 BLC_DRV_STAT_12_07 1;
BA_ "GenSigSendType" SG_ 1649 BLC_DRV_STAT_11_07 0;
BA_ "GenSigCycleTime" SG_ 1649 BLC_DRV_STAT_11_07 40;
BA_ "FlexKomSigStartValue" SG_ 1649 BLC_DRV_STAT_11_07 "0000h";
BA_ "GenSigTimeout_BMU" SG_ 1649 BLC_DRV_STAT_11_07 220;
BA_ "FlexKomSID" SG_ 1649 BLC_DRV_STAT_11_07 731;
BA_ "FlexKomSigStartPos" SG_ 1649 BLC_DRV_STAT_11_07 7;
BA_ "FlexKomSigLaenge" SG_ 1649 BLC_DRV_STAT_11_07 16;
BA_ "FlexKomSigName" SG_ 1649 BLC_DRV_STAT_11_07 "BLC_DRV_STAT_07";
BA_ "FlexKomComment" SG_ 1649 BLC_DRV_STAT_11_07 "Balancer drive status packet";
BA_ "FlexKomIsMotorola" SG_ 1649 BLC_DRV_STAT_11_07 1;
BA_ "GenSigSendType" SG_ 1649 BLC_DRV_STAT_10_07 0;
BA_ "GenSigCycleTime" SG_ 1649 BLC_DRV_STAT_10_07 40;
BA_ "FlexKomSigStartValue" SG_ 1649 BLC_DRV_STAT_10_07 "0000h";
BA_ "GenSigTimeout_BMU" SG_ 1649 BLC_DRV_STAT_10_07 220;
BA_ "FlexKomSID" SG_ 1649 BLC_DRV_STAT_10_07 731;
BA_ "FlexKomSigStartPos" SG_ 1649 BLC_DRV_STAT_10_07 7;
BA_ "FlexKomSigLaenge" SG_ 1649 BLC_DRV_STAT_10_07 16;
BA_ "FlexKomSigName" SG_ 1649 BLC_DRV_STAT_10_07 "BLC_DRV_STAT_07";
BA_ "FlexKomComment" SG_ 1649 BLC_DRV_STAT_10_07 "Balancer drive status packet";
BA_ "FlexKomIsMotorola" SG_ 1649 BLC_DRV_STAT_10_07 1;
BA_ "GenSigSendType" SG_ 1649 BLC_DRV_STAT_09_07 0;
BA_ "GenSigCycleTime" SG_ 1649 BLC_DRV_STAT_09_07 40;
BA_ "FlexKomSigStartValue" SG_ 1649 BLC_DRV_STAT_09_07 "0000h";
BA_ "GenSigTimeout_BMU" SG_ 1649 BLC_DRV_STAT_09_07 220;
BA_ "FlexKomSID" SG_ 1649 BLC_DRV_STAT_09_07 731;
BA_ "FlexKomSigStartPos" SG_ 1649 BLC_DRV_STAT_09_07 7;
BA_ "FlexKomSigLaenge" SG_ 1649 BLC_DRV_STAT_09_07 16;
BA_ "FlexKomSigName" SG_ 1649 BLC_DRV_STAT_09_07 "BLC_DRV_STAT_07";
BA_ "FlexKomComment" SG_ 1649 BLC_DRV_STAT_09_07 "Balancer drive status packet";
BA_ "FlexKomIsMotorola" SG_ 1649 BLC_DRV_STAT_09_07 1;
BA_ "GenSigSendType" SG_ 1649 BLC_DRV_STAT_08_07 0;
BA_ "GenSigCycleTime" SG_ 1649 BLC_DRV_STAT_08_07 40;
BA_ "FlexKomSigStartValue" SG_ 1649 BLC_DRV_STAT_08_07 "0000h";
BA_ "GenSigTimeout_BMU" SG_ 1649 BLC_DRV_STAT_08_07 220;
BA_ "FlexKomSID" SG_ 1649 BLC_DRV_STAT_08_07 731;
BA_ "FlexKomSigStartPos" SG_ 1649 BLC_DRV_STAT_08_07 7;
BA_ "FlexKomSigLaenge" SG_ 1649 BLC_DRV_STAT_08_07 16;
BA_ "FlexKomSigName" SG_ 1649 BLC_DRV_STAT_08_07 "BLC_DRV_STAT_07";
BA_ "FlexKomComment" SG_ 1649 BLC_DRV_STAT_08_07 "Balancer drive status packet";
BA_ "FlexKomIsMotorola" SG_ 1649 BLC_DRV_STAT_08_07 1;
BA_ "GenSigSendType" SG_ 1649 BLC_DRV_STAT_07_07 0;
BA_ "GenSigCycleTime" SG_ 1649 BLC_DRV_STAT_07_07 40;
BA_ "FlexKomSigStartValue" SG_ 1649 BLC_DRV_STAT_07_07 "0000h";
BA_ "GenSigTimeout_BMU" SG_ 1649 BLC_DRV_STAT_07_07 220;
BA_ "FlexKomSID" SG_ 1649 BLC_DRV_STAT_07_07 731;
BA_ "FlexKomSigStartPos" SG_ 1649 BLC_DRV_STAT_07_07 7;
BA_ "FlexKomSigLaenge" SG_ 1649 BLC_DRV_STAT_07_07 16;
BA_ "FlexKomSigName" SG_ 1649 BLC_DRV_STAT_07_07 "BLC_DRV_STAT_07";
BA_ "FlexKomComment" SG_ 1649 BLC_DRV_STAT_07_07 "Balancer drive status packet";
BA_ "FlexKomIsMotorola" SG_ 1649 BLC_DRV_STAT_07_07 1;
BA_ "GenSigSendType" SG_ 1649 BLC_DRV_STAT_06_07 0;
BA_ "GenSigCycleTime" SG_ 1649 BLC_DRV_STAT_06_07 40;
BA_ "FlexKomSigStartValue" SG_ 1649 BLC_DRV_STAT_06_07 "0000h";
BA_ "GenSigTimeout_BMU" SG_ 1649 BLC_DRV_STAT_06_07 220;
BA_ "FlexKomSID" SG_ 1649 BLC_DRV_STAT_06_07 731;
BA_ "FlexKomSigStartPos" SG_ 1649 BLC_DRV_STAT_06_07 7;
BA_ "FlexKomSigLaenge" SG_ 1649 BLC_DRV_STAT_06_07 16;
BA_ "FlexKomSigName" SG_ 1649 BLC_DRV_STAT_06_07 "BLC_DRV_STAT_07";
BA_ "FlexKomComment" SG_ 1649 BLC_DRV_STAT_06_07 "Balancer drive status packet";
BA_ "FlexKomIsMotorola" SG_ 1649 BLC_DRV_STAT_06_07 1;
BA_ "GenSigSendType" SG_ 1649 BLC_DRV_STAT_05_07 0;
BA_ "GenSigCycleTime" SG_ 1649 BLC_DRV_STAT_05_07 40;
BA_ "FlexKomSigStartValue" SG_ 1649 BLC_DRV_STAT_05_07 "0000h";
BA_ "GenSigTimeout_BMU" SG_ 1649 BLC_DRV_STAT_05_07 220;
BA_ "FlexKomSID" SG_ 1649 BLC_DRV_STAT_05_07 731;
BA_ "FlexKomSigStartPos" SG_ 1649 BLC_DRV_STAT_05_07 7;
BA_ "FlexKomSigLaenge" SG_ 1649 BLC_DRV_STAT_05_07 16;
BA_ "FlexKomSigName" SG_ 1649 BLC_DRV_STAT_05_07 "BLC_DRV_STAT_07";
BA_ "FlexKomComment" SG_ 1649 BLC_DRV_STAT_05_07 "Balancer drive status packet";
BA_ "FlexKomIsMotorola" SG_ 1649 BLC_DRV_STAT_05_07 1;
BA_ "GenSigSendType" SG_ 1649 BLC_DRV_STAT_04_07 0;
BA_ "GenSigCycleTime" SG_ 1649 BLC_DRV_STAT_04_07 40;
BA_ "FlexKomSigStartValue" SG_ 1649 BLC_DRV_STAT_04_07 "0000h";
BA_ "GenSigTimeout_BMU" SG_ 1649 BLC_DRV_STAT_04_07 220;
BA_ "FlexKomSID" SG_ 1649 BLC_DRV_STAT_04_07 731;
BA_ "FlexKomSigStartPos" SG_ 1649 BLC_DRV_STAT_04_07 7;
BA_ "FlexKomSigLaenge" SG_ 1649 BLC_DRV_STAT_04_07 16;
BA_ "FlexKomSigName" SG_ 1649 BLC_DRV_STAT_04_07 "BLC_DRV_STAT_07";
BA_ "FlexKomComment" SG_ 1649 BLC_DRV_STAT_04_07 "Balancer drive status packet";
BA_ "FlexKomIsMotorola" SG_ 1649 BLC_DRV_STAT_04_07 1;
BA_ "GenSigSendType" SG_ 1649 BLC_DRV_STAT_03_07 0;
BA_ "GenSigCycleTime" SG_ 1649 BLC_DRV_STAT_03_07 40;
BA_ "FlexKomSigStartValue" SG_ 1649 BLC_DRV_STAT_03_07 "0000h";
BA_ "GenSigTimeout_BMU" SG_ 1649 BLC_DRV_STAT_03_07 220;
BA_ "FlexKomSID" SG_ 1649 BLC_DRV_STAT_03_07 731;
BA_ "FlexKomSigStartPos" SG_ 1649 BLC_DRV_STAT_03_07 7;
BA_ "FlexKomSigLaenge" SG_ 1649 BLC_DRV_STAT_03_07 16;
BA_ "FlexKomSigName" SG_ 1649 BLC_DRV_STAT_03_07 "BLC_DRV_STAT_07";
BA_ "FlexKomComment" SG_ 1649 BLC_DRV_STAT_03_07 "Balancer drive status packet";
BA_ "FlexKomIsMotorola" SG_ 1649 BLC_DRV_STAT_03_07 1;
BA_ "GenSigSendType" SG_ 1649 BLC_DRV_STAT_02_07 0;
BA_ "GenSigCycleTime" SG_ 1649 BLC_DRV_STAT_02_07 40;
BA_ "FlexKomSigStartValue" SG_ 1649 BLC_DRV_STAT_02_07 "0000h";
BA_ "GenSigTimeout_BMU" SG_ 1649 BLC_DRV_STAT_02_07 220;
BA_ "FlexKomSID" SG_ 1649 BLC_DRV_STAT_02_07 731;
BA_ "FlexKomSigStartPos" SG_ 1649 BLC_DRV_STAT_02_07 7;
BA_ "FlexKomSigLaenge" SG_ 1649 BLC_DRV_STAT_02_07 16;
BA_ "FlexKomSigName" SG_ 1649 BLC_DRV_STAT_02_07 "BLC_DRV_STAT_07";
BA_ "FlexKomComment" SG_ 1649 BLC_DRV_STAT_02_07 "Balancer drive status packet";
BA_ "FlexKomIsMotorola" SG_ 1649 BLC_DRV_STAT_02_07 1;
BA_ "GenSigSendType" SG_ 1649 BLC_DRV_STAT_01_07 0;
BA_ "GenSigCycleTime" SG_ 1649 BLC_DRV_STAT_01_07 40;
BA_ "FlexKomSigStartValue" SG_ 1649 BLC_DRV_STAT_01_07 "0000h";
BA_ "GenSigTimeout_BMU" SG_ 1649 BLC_DRV_STAT_01_07 220;
BA_ "FlexKomSID" SG_ 1649 BLC_DRV_STAT_01_07 731;
BA_ "FlexKomSigStartPos" SG_ 1649 BLC_DRV_STAT_01_07 7;
BA_ "FlexKomSigLaenge" SG_ 1649 BLC_DRV_STAT_01_07 16;
BA_ "FlexKomSigName" SG_ 1649 BLC_DRV_STAT_01_07 "BLC_DRV_STAT_07";
BA_ "FlexKomComment" SG_ 1649 BLC_DRV_STAT_01_07 "Balancer drive status packet";
BA_ "FlexKomIsMotorola" SG_ 1649 BLC_DRV_STAT_01_07 1;
BA_ "GenSigSendType" SG_ 1633 MODULE_TEMP_06_06 0;
BA_ "GenSigCycleTime" SG_ 1633 MODULE_TEMP_06_06 40;
BA_ "FlexKomSigStartValue" SG_ 1633 MODULE_TEMP_06_06 "00h";
BA_ "GenSigTimeout_BMU" SG_ 1633 MODULE_TEMP_06_06 220;
BA_ "FlexKomSID" SG_ 1633 MODULE_TEMP_06_06 1104;
BA_ "FlexKomSigStartPos" SG_ 1633 MODULE_TEMP_06_06 63;
BA_ "FlexKomSigLaenge" SG_ 1633 MODULE_TEMP_06_06 8;
BA_ "FlexKomSigName" SG_ 1633 MODULE_TEMP_06_06 "MODULE_TEMP_06_06";
BA_ "FlexKomComment" SG_ 1633 MODULE_TEMP_06_06 "Module temperature06";
BA_ "FlexKomIsMotorola" SG_ 1633 MODULE_TEMP_06_06 1;
BA_ "GenSigSendType" SG_ 1633 MODULE_TEMP_05_06 0;
BA_ "GenSigCycleTime" SG_ 1633 MODULE_TEMP_05_06 40;
BA_ "FlexKomSigStartValue" SG_ 1633 MODULE_TEMP_05_06 "00h";
BA_ "GenSigTimeout_BMU" SG_ 1633 MODULE_TEMP_05_06 220;
BA_ "FlexKomSID" SG_ 1633 MODULE_TEMP_05_06 1092;
BA_ "FlexKomSigStartPos" SG_ 1633 MODULE_TEMP_05_06 55;
BA_ "FlexKomSigLaenge" SG_ 1633 MODULE_TEMP_05_06 8;
BA_ "FlexKomSigName" SG_ 1633 MODULE_TEMP_05_06 "MODULE_TEMP_05_06";
BA_ "FlexKomComment" SG_ 1633 MODULE_TEMP_05_06 "Module temperature05";
BA_ "FlexKomIsMotorola" SG_ 1633 MODULE_TEMP_05_06 1;
BA_ "GenSigSendType" SG_ 1633 MODULE_TEMP_04_06 0;
BA_ "GenSigCycleTime" SG_ 1633 MODULE_TEMP_04_06 40;
BA_ "FlexKomSigStartValue" SG_ 1633 MODULE_TEMP_04_06 "00h";
BA_ "GenSigTimeout_BMU" SG_ 1633 MODULE_TEMP_04_06 220;
BA_ "FlexKomSID" SG_ 1633 MODULE_TEMP_04_06 1080;
BA_ "FlexKomSigStartPos" SG_ 1633 MODULE_TEMP_04_06 47;
BA_ "FlexKomSigLaenge" SG_ 1633 MODULE_TEMP_04_06 8;
BA_ "FlexKomSigName" SG_ 1633 MODULE_TEMP_04_06 "MODULE_TEMP_04_06";
BA_ "FlexKomComment" SG_ 1633 MODULE_TEMP_04_06 "Module temperature04";
BA_ "FlexKomIsMotorola" SG_ 1633 MODULE_TEMP_04_06 1;
BA_ "GenSigSendType" SG_ 1633 MODULE_TEMP_03_06 0;
BA_ "GenSigCycleTime" SG_ 1633 MODULE_TEMP_03_06 40;
BA_ "FlexKomSigStartValue" SG_ 1633 MODULE_TEMP_03_06 "00h";
BA_ "GenSigTimeout_BMU" SG_ 1633 MODULE_TEMP_03_06 220;
BA_ "FlexKomSID" SG_ 1633 MODULE_TEMP_03_06 1068;
BA_ "FlexKomSigStartPos" SG_ 1633 MODULE_TEMP_03_06 39;
BA_ "FlexKomSigLaenge" SG_ 1633 MODULE_TEMP_03_06 8;
BA_ "FlexKomSigName" SG_ 1633 MODULE_TEMP_03_06 "MODULE_TEMP_03_06";
BA_ "FlexKomComment" SG_ 1633 MODULE_TEMP_03_06 "Module temperature03";
BA_ "FlexKomIsMotorola" SG_ 1633 MODULE_TEMP_03_06 1;
BA_ "GenSigSendType" SG_ 1633 MODULE_TEMP_02_06 0;
BA_ "GenSigCycleTime" SG_ 1633 MODULE_TEMP_02_06 40;
BA_ "FlexKomSigStartValue" SG_ 1633 MODULE_TEMP_02_06 "00h";
BA_ "GenSigTimeout_BMU" SG_ 1633 MODULE_TEMP_02_06 220;
BA_ "FlexKomSID" SG_ 1633 MODULE_TEMP_02_06 1056;
BA_ "FlexKomSigStartPos" SG_ 1633 MODULE_TEMP_02_06 31;
BA_ "FlexKomSigLaenge" SG_ 1633 MODULE_TEMP_02_06 8;
BA_ "FlexKomSigName" SG_ 1633 MODULE_TEMP_02_06 "MODULE_TEMP_02_06";
BA_ "FlexKomComment" SG_ 1633 MODULE_TEMP_02_06 "Module temperature02";
BA_ "FlexKomIsMotorola" SG_ 1633 MODULE_TEMP_02_06 1;
BA_ "GenSigSendType" SG_ 1633 MODULE_TEMP_01_06 0;
BA_ "GenSigCycleTime" SG_ 1633 MODULE_TEMP_01_06 40;
BA_ "FlexKomSigStartValue" SG_ 1633 MODULE_TEMP_01_06 "00h";
BA_ "GenSigTimeout_BMU" SG_ 1633 MODULE_TEMP_01_06 220;
BA_ "FlexKomSID" SG_ 1633 MODULE_TEMP_01_06 1044;
BA_ "FlexKomSigStartPos" SG_ 1633 MODULE_TEMP_01_06 23;
BA_ "FlexKomSigLaenge" SG_ 1633 MODULE_TEMP_01_06 8;
BA_ "FlexKomSigName" SG_ 1633 MODULE_TEMP_01_06 "MODULE_TEMP_01_06";
BA_ "FlexKomComment" SG_ 1633 MODULE_TEMP_01_06 "Module temperature01";
BA_ "FlexKomIsMotorola" SG_ 1633 MODULE_TEMP_01_06 1;
BA_ "GenSigSendType" SG_ 1633 NUM_TABLE_VALUE_06 0;
BA_ "GenSigCycleTime" SG_ 1633 NUM_TABLE_VALUE_06 40;
BA_ "FlexKomSigStartValue" SG_ 1633 NUM_TABLE_VALUE_06 "0Fh";
BA_ "GenSigStartValue" SG_ 1633 NUM_TABLE_VALUE_06 15;
BA_ "GenSigTimeout_BMU" SG_ 1633 NUM_TABLE_VALUE_06 220;
BA_ "FlexKomSID" SG_ 1633 NUM_TABLE_VALUE_06 1032;
BA_ "FlexKomSigStartPos" SG_ 1633 NUM_TABLE_VALUE_06 15;
BA_ "FlexKomSigLaenge" SG_ 1633 NUM_TABLE_VALUE_06 4;
BA_ "FlexKomSigName" SG_ 1633 NUM_TABLE_VALUE_06 "NUM_TABLE_VALUE_06";
BA_ "FlexKomComment" SG_ 1633 NUM_TABLE_VALUE_06 "Stored Automatic numbering table";
BA_ "FlexKomIsMotorola" SG_ 1633 NUM_TABLE_VALUE_06 1;
BA_ "GenSigSendType" SG_ 1633 BLC_DRV_STAT_12_06 0;
BA_ "GenSigCycleTime" SG_ 1633 BLC_DRV_STAT_12_06 40;
BA_ "FlexKomSigStartValue" SG_ 1633 BLC_DRV_STAT_12_06 "0000h";
BA_ "GenSigTimeout_BMU" SG_ 1633 BLC_DRV_STAT_12_06 220;
BA_ "FlexKomSID" SG_ 1633 BLC_DRV_STAT_12_06 725;
BA_ "FlexKomSigStartPos" SG_ 1633 BLC_DRV_STAT_12_06 7;
BA_ "FlexKomSigLaenge" SG_ 1633 BLC_DRV_STAT_12_06 16;
BA_ "FlexKomSigName" SG_ 1633 BLC_DRV_STAT_12_06 "BLC_DRV_STAT_06";
BA_ "FlexKomComment" SG_ 1633 BLC_DRV_STAT_12_06 "Balancer drive status packet";
BA_ "FlexKomIsMotorola" SG_ 1633 BLC_DRV_STAT_12_06 1;
BA_ "GenSigSendType" SG_ 1633 BLC_DRV_STAT_11_06 0;
BA_ "GenSigCycleTime" SG_ 1633 BLC_DRV_STAT_11_06 40;
BA_ "FlexKomSigStartValue" SG_ 1633 BLC_DRV_STAT_11_06 "0000h";
BA_ "GenSigTimeout_BMU" SG_ 1633 BLC_DRV_STAT_11_06 220;
BA_ "FlexKomSID" SG_ 1633 BLC_DRV_STAT_11_06 725;
BA_ "FlexKomSigStartPos" SG_ 1633 BLC_DRV_STAT_11_06 7;
BA_ "FlexKomSigLaenge" SG_ 1633 BLC_DRV_STAT_11_06 16;
BA_ "FlexKomSigName" SG_ 1633 BLC_DRV_STAT_11_06 "BLC_DRV_STAT_06";
BA_ "FlexKomComment" SG_ 1633 BLC_DRV_STAT_11_06 "Balancer drive status packet";
BA_ "FlexKomIsMotorola" SG_ 1633 BLC_DRV_STAT_11_06 1;
BA_ "GenSigSendType" SG_ 1633 BLC_DRV_STAT_10_06 0;
BA_ "GenSigCycleTime" SG_ 1633 BLC_DRV_STAT_10_06 40;
BA_ "FlexKomSigStartValue" SG_ 1633 BLC_DRV_STAT_10_06 "0000h";
BA_ "GenSigTimeout_BMU" SG_ 1633 BLC_DRV_STAT_10_06 220;
BA_ "FlexKomSID" SG_ 1633 BLC_DRV_STAT_10_06 725;
BA_ "FlexKomSigStartPos" SG_ 1633 BLC_DRV_STAT_10_06 7;
BA_ "FlexKomSigLaenge" SG_ 1633 BLC_DRV_STAT_10_06 16;
BA_ "FlexKomSigName" SG_ 1633 BLC_DRV_STAT_10_06 "BLC_DRV_STAT_06";
BA_ "FlexKomComment" SG_ 1633 BLC_DRV_STAT_10_06 "Balancer drive status packet";
BA_ "FlexKomIsMotorola" SG_ 1633 BLC_DRV_STAT_10_06 1;
BA_ "GenSigSendType" SG_ 1633 BLC_DRV_STAT_09_06 0;
BA_ "GenSigCycleTime" SG_ 1633 BLC_DRV_STAT_09_06 40;
BA_ "FlexKomSigStartValue" SG_ 1633 BLC_DRV_STAT_09_06 "0000h";
BA_ "GenSigTimeout_BMU" SG_ 1633 BLC_DRV_STAT_09_06 220;
BA_ "FlexKomSID" SG_ 1633 BLC_DRV_STAT_09_06 725;
BA_ "FlexKomSigStartPos" SG_ 1633 BLC_DRV_STAT_09_06 7;
BA_ "FlexKomSigLaenge" SG_ 1633 BLC_DRV_STAT_09_06 16;
BA_ "FlexKomSigName" SG_ 1633 BLC_DRV_STAT_09_06 "BLC_DRV_STAT_06";
BA_ "FlexKomComment" SG_ 1633 BLC_DRV_STAT_09_06 "Balancer drive status packet";
BA_ "FlexKomIsMotorola" SG_ 1633 BLC_DRV_STAT_09_06 1;
BA_ "GenSigSendType" SG_ 1633 BLC_DRV_STAT_08_06 0;
BA_ "GenSigCycleTime" SG_ 1633 BLC_DRV_STAT_08_06 40;
BA_ "FlexKomSigStartValue" SG_ 1633 BLC_DRV_STAT_08_06 "0000h";
BA_ "GenSigTimeout_BMU" SG_ 1633 BLC_DRV_STAT_08_06 220;
BA_ "FlexKomSID" SG_ 1633 BLC_DRV_STAT_08_06 725;
BA_ "FlexKomSigStartPos" SG_ 1633 BLC_DRV_STAT_08_06 7;
BA_ "FlexKomSigLaenge" SG_ 1633 BLC_DRV_STAT_08_06 16;
BA_ "FlexKomSigName" SG_ 1633 BLC_DRV_STAT_08_06 "BLC_DRV_STAT_06";
BA_ "FlexKomComment" SG_ 1633 BLC_DRV_STAT_08_06 "Balancer drive status packet";
BA_ "FlexKomIsMotorola" SG_ 1633 BLC_DRV_STAT_08_06 1;
BA_ "GenSigSendType" SG_ 1633 BLC_DRV_STAT_07_06 0;
BA_ "GenSigCycleTime" SG_ 1633 BLC_DRV_STAT_07_06 40;
BA_ "FlexKomSigStartValue" SG_ 1633 BLC_DRV_STAT_07_06 "0000h";
BA_ "GenSigTimeout_BMU" SG_ 1633 BLC_DRV_STAT_07_06 220;
BA_ "FlexKomSID" SG_ 1633 BLC_DRV_STAT_07_06 725;
BA_ "FlexKomSigStartPos" SG_ 1633 BLC_DRV_STAT_07_06 7;
BA_ "FlexKomSigLaenge" SG_ 1633 BLC_DRV_STAT_07_06 16;
BA_ "FlexKomSigName" SG_ 1633 BLC_DRV_STAT_07_06 "BLC_DRV_STAT_06";
BA_ "FlexKomComment" SG_ 1633 BLC_DRV_STAT_07_06 "Balancer drive status packet";
BA_ "FlexKomIsMotorola" SG_ 1633 BLC_DRV_STAT_07_06 1;
BA_ "GenSigSendType" SG_ 1633 BLC_DRV_STAT_06_06 0;
BA_ "GenSigCycleTime" SG_ 1633 BLC_DRV_STAT_06_06 40;
BA_ "FlexKomSigStartValue" SG_ 1633 BLC_DRV_STAT_06_06 "0000h";
BA_ "GenSigTimeout_BMU" SG_ 1633 BLC_DRV_STAT_06_06 220;
BA_ "FlexKomSID" SG_ 1633 BLC_DRV_STAT_06_06 725;
BA_ "FlexKomSigStartPos" SG_ 1633 BLC_DRV_STAT_06_06 7;
BA_ "FlexKomSigLaenge" SG_ 1633 BLC_DRV_STAT_06_06 16;
BA_ "FlexKomSigName" SG_ 1633 BLC_DRV_STAT_06_06 "BLC_DRV_STAT_06";
BA_ "FlexKomComment" SG_ 1633 BLC_DRV_STAT_06_06 "Balancer drive status packet";
BA_ "FlexKomIsMotorola" SG_ 1633 BLC_DRV_STAT_06_06 1;
BA_ "GenSigSendType" SG_ 1633 BLC_DRV_STAT_05_06 0;
BA_ "GenSigCycleTime" SG_ 1633 BLC_DRV_STAT_05_06 40;
BA_ "FlexKomSigStartValue" SG_ 1633 BLC_DRV_STAT_05_06 "0000h";
BA_ "GenSigTimeout_BMU" SG_ 1633 BLC_DRV_STAT_05_06 220;
BA_ "FlexKomSID" SG_ 1633 BLC_DRV_STAT_05_06 725;
BA_ "FlexKomSigStartPos" SG_ 1633 BLC_DRV_STAT_05_06 7;
BA_ "FlexKomSigLaenge" SG_ 1633 BLC_DRV_STAT_05_06 16;
BA_ "FlexKomSigName" SG_ 1633 BLC_DRV_STAT_05_06 "BLC_DRV_STAT_06";
BA_ "FlexKomComment" SG_ 1633 BLC_DRV_STAT_05_06 "Balancer drive status packet";
BA_ "FlexKomIsMotorola" SG_ 1633 BLC_DRV_STAT_05_06 1;
BA_ "GenSigSendType" SG_ 1633 BLC_DRV_STAT_04_06 0;
BA_ "GenSigCycleTime" SG_ 1633 BLC_DRV_STAT_04_06 40;
BA_ "FlexKomSigStartValue" SG_ 1633 BLC_DRV_STAT_04_06 "0000h";
BA_ "GenSigTimeout_BMU" SG_ 1633 BLC_DRV_STAT_04_06 220;
BA_ "FlexKomSID" SG_ 1633 BLC_DRV_STAT_04_06 725;
BA_ "FlexKomSigStartPos" SG_ 1633 BLC_DRV_STAT_04_06 7;
BA_ "FlexKomSigLaenge" SG_ 1633 BLC_DRV_STAT_04_06 16;
BA_ "FlexKomSigName" SG_ 1633 BLC_DRV_STAT_04_06 "BLC_DRV_STAT_06";
BA_ "FlexKomComment" SG_ 1633 BLC_DRV_STAT_04_06 "Balancer drive status packet";
BA_ "FlexKomIsMotorola" SG_ 1633 BLC_DRV_STAT_04_06 1;
BA_ "GenSigSendType" SG_ 1633 BLC_DRV_STAT_03_06 0;
BA_ "GenSigCycleTime" SG_ 1633 BLC_DRV_STAT_03_06 40;
BA_ "FlexKomSigStartValue" SG_ 1633 BLC_DRV_STAT_03_06 "0000h";
BA_ "GenSigTimeout_BMU" SG_ 1633 BLC_DRV_STAT_03_06 220;
BA_ "FlexKomSID" SG_ 1633 BLC_DRV_STAT_03_06 725;
BA_ "FlexKomSigStartPos" SG_ 1633 BLC_DRV_STAT_03_06 7;
BA_ "FlexKomSigLaenge" SG_ 1633 BLC_DRV_STAT_03_06 16;
BA_ "FlexKomSigName" SG_ 1633 BLC_DRV_STAT_03_06 "BLC_DRV_STAT_06";
BA_ "FlexKomComment" SG_ 1633 BLC_DRV_STAT_03_06 "Balancer drive status packet";
BA_ "FlexKomIsMotorola" SG_ 1633 BLC_DRV_STAT_03_06 1;
BA_ "GenSigSendType" SG_ 1633 BLC_DRV_STAT_02_06 0;
BA_ "GenSigCycleTime" SG_ 1633 BLC_DRV_STAT_02_06 40;
BA_ "FlexKomSigStartValue" SG_ 1633 BLC_DRV_STAT_02_06 "0000h";
BA_ "GenSigTimeout_BMU" SG_ 1633 BLC_DRV_STAT_02_06 220;
BA_ "FlexKomSID" SG_ 1633 BLC_DRV_STAT_02_06 725;
BA_ "FlexKomSigStartPos" SG_ 1633 BLC_DRV_STAT_02_06 7;
BA_ "FlexKomSigLaenge" SG_ 1633 BLC_DRV_STAT_02_06 16;
BA_ "FlexKomSigName" SG_ 1633 BLC_DRV_STAT_02_06 "BLC_DRV_STAT_06";
BA_ "FlexKomComment" SG_ 1633 BLC_DRV_STAT_02_06 "Balancer drive status packet";
BA_ "FlexKomIsMotorola" SG_ 1633 BLC_DRV_STAT_02_06 1;
BA_ "GenSigSendType" SG_ 1633 BLC_DRV_STAT_01_06 0;
BA_ "GenSigCycleTime" SG_ 1633 BLC_DRV_STAT_01_06 40;
BA_ "FlexKomSigStartValue" SG_ 1633 BLC_DRV_STAT_01_06 "0000h";
BA_ "GenSigTimeout_BMU" SG_ 1633 BLC_DRV_STAT_01_06 220;
BA_ "FlexKomSID" SG_ 1633 BLC_DRV_STAT_01_06 725;
BA_ "FlexKomSigStartPos" SG_ 1633 BLC_DRV_STAT_01_06 7;
BA_ "FlexKomSigLaenge" SG_ 1633 BLC_DRV_STAT_01_06 16;
BA_ "FlexKomSigName" SG_ 1633 BLC_DRV_STAT_01_06 "BLC_DRV_STAT_06";
BA_ "FlexKomComment" SG_ 1633 BLC_DRV_STAT_01_06 "Balancer drive status packet";
BA_ "FlexKomIsMotorola" SG_ 1633 BLC_DRV_STAT_01_06 1;
BA_ "GenSigSendType" SG_ 1617 MODULE_TEMP_06_05 0;
BA_ "GenSigCycleTime" SG_ 1617 MODULE_TEMP_06_05 40;
BA_ "FlexKomSigStartValue" SG_ 1617 MODULE_TEMP_06_05 "00h";
BA_ "GenSigTimeout_BMU" SG_ 1617 MODULE_TEMP_06_05 220;
BA_ "FlexKomSID" SG_ 1617 MODULE_TEMP_06_05 1103;
BA_ "FlexKomSigStartPos" SG_ 1617 MODULE_TEMP_06_05 63;
BA_ "FlexKomSigLaenge" SG_ 1617 MODULE_TEMP_06_05 8;
BA_ "FlexKomSigName" SG_ 1617 MODULE_TEMP_06_05 "MODULE_TEMP_06_05";
BA_ "FlexKomComment" SG_ 1617 MODULE_TEMP_06_05 "Module temperature06";
BA_ "FlexKomIsMotorola" SG_ 1617 MODULE_TEMP_06_05 1;
BA_ "GenSigSendType" SG_ 1617 MODULE_TEMP_05_05 0;
BA_ "GenSigCycleTime" SG_ 1617 MODULE_TEMP_05_05 40;
BA_ "FlexKomSigStartValue" SG_ 1617 MODULE_TEMP_05_05 "00h";
BA_ "GenSigTimeout_BMU" SG_ 1617 MODULE_TEMP_05_05 220;
BA_ "FlexKomSID" SG_ 1617 MODULE_TEMP_05_05 1091;
BA_ "FlexKomSigStartPos" SG_ 1617 MODULE_TEMP_05_05 55;
BA_ "FlexKomSigLaenge" SG_ 1617 MODULE_TEMP_05_05 8;
BA_ "FlexKomSigName" SG_ 1617 MODULE_TEMP_05_05 "MODULE_TEMP_05_05";
BA_ "FlexKomComment" SG_ 1617 MODULE_TEMP_05_05 "Module temperature05";
BA_ "FlexKomIsMotorola" SG_ 1617 MODULE_TEMP_05_05 1;
BA_ "GenSigSendType" SG_ 1617 MODULE_TEMP_04_05 0;
BA_ "GenSigCycleTime" SG_ 1617 MODULE_TEMP_04_05 40;
BA_ "FlexKomSigStartValue" SG_ 1617 MODULE_TEMP_04_05 "00h";
BA_ "GenSigTimeout_BMU" SG_ 1617 MODULE_TEMP_04_05 220;
BA_ "FlexKomSID" SG_ 1617 MODULE_TEMP_04_05 1079;
BA_ "FlexKomSigStartPos" SG_ 1617 MODULE_TEMP_04_05 47;
BA_ "FlexKomSigLaenge" SG_ 1617 MODULE_TEMP_04_05 8;
BA_ "FlexKomSigName" SG_ 1617 MODULE_TEMP_04_05 "MODULE_TEMP_04_05";
BA_ "FlexKomComment" SG_ 1617 MODULE_TEMP_04_05 "Module temperature04";
BA_ "FlexKomIsMotorola" SG_ 1617 MODULE_TEMP_04_05 1;
BA_ "GenSigSendType" SG_ 1617 MODULE_TEMP_03_05 0;
BA_ "GenSigCycleTime" SG_ 1617 MODULE_TEMP_03_05 40;
BA_ "FlexKomSigStartValue" SG_ 1617 MODULE_TEMP_03_05 "00h";
BA_ "GenSigTimeout_BMU" SG_ 1617 MODULE_TEMP_03_05 220;
BA_ "FlexKomSID" SG_ 1617 MODULE_TEMP_03_05 1067;
BA_ "FlexKomSigStartPos" SG_ 1617 MODULE_TEMP_03_05 39;
BA_ "FlexKomSigLaenge" SG_ 1617 MODULE_TEMP_03_05 8;
BA_ "FlexKomSigName" SG_ 1617 MODULE_TEMP_03_05 "MODULE_TEMP_03_05";
BA_ "FlexKomComment" SG_ 1617 MODULE_TEMP_03_05 "Module temperature03";
BA_ "FlexKomIsMotorola" SG_ 1617 MODULE_TEMP_03_05 1;
BA_ "GenSigSendType" SG_ 1617 MODULE_TEMP_02_05 0;
BA_ "GenSigCycleTime" SG_ 1617 MODULE_TEMP_02_05 40;
BA_ "FlexKomSigStartValue" SG_ 1617 MODULE_TEMP_02_05 "00h";
BA_ "GenSigTimeout_BMU" SG_ 1617 MODULE_TEMP_02_05 220;
BA_ "FlexKomSID" SG_ 1617 MODULE_TEMP_02_05 1055;
BA_ "FlexKomSigStartPos" SG_ 1617 MODULE_TEMP_02_05 31;
BA_ "FlexKomSigLaenge" SG_ 1617 MODULE_TEMP_02_05 8;
BA_ "FlexKomSigName" SG_ 1617 MODULE_TEMP_02_05 "MODULE_TEMP_02_05";
BA_ "FlexKomComment" SG_ 1617 MODULE_TEMP_02_05 "Module temperature02";
BA_ "FlexKomIsMotorola" SG_ 1617 MODULE_TEMP_02_05 1;
BA_ "GenSigSendType" SG_ 1617 MODULE_TEMP_01_05 0;
BA_ "GenSigCycleTime" SG_ 1617 MODULE_TEMP_01_05 40;
BA_ "FlexKomSigStartValue" SG_ 1617 MODULE_TEMP_01_05 "00h";
BA_ "GenSigTimeout_BMU" SG_ 1617 MODULE_TEMP_01_05 220;
BA_ "FlexKomSID" SG_ 1617 MODULE_TEMP_01_05 1043;
BA_ "FlexKomSigStartPos" SG_ 1617 MODULE_TEMP_01_05 23;
BA_ "FlexKomSigLaenge" SG_ 1617 MODULE_TEMP_01_05 8;
BA_ "FlexKomSigName" SG_ 1617 MODULE_TEMP_01_05 "MODULE_TEMP_01_05";
BA_ "FlexKomComment" SG_ 1617 MODULE_TEMP_01_05 "Module temperature01";
BA_ "FlexKomIsMotorola" SG_ 1617 MODULE_TEMP_01_05 1;
BA_ "GenSigSendType" SG_ 1617 NUM_TABLE_VALUE_05 0;
BA_ "GenSigCycleTime" SG_ 1617 NUM_TABLE_VALUE_05 40;
BA_ "FlexKomSigStartValue" SG_ 1617 NUM_TABLE_VALUE_05 "0Fh";
BA_ "GenSigStartValue" SG_ 1617 NUM_TABLE_VALUE_05 15;
BA_ "GenSigTimeout_BMU" SG_ 1617 NUM_TABLE_VALUE_05 220;
BA_ "FlexKomSID" SG_ 1617 NUM_TABLE_VALUE_05 1031;
BA_ "FlexKomSigStartPos" SG_ 1617 NUM_TABLE_VALUE_05 15;
BA_ "FlexKomSigLaenge" SG_ 1617 NUM_TABLE_VALUE_05 4;
BA_ "FlexKomSigName" SG_ 1617 NUM_TABLE_VALUE_05 "NUM_TABLE_VALUE_05";
BA_ "FlexKomComment" SG_ 1617 NUM_TABLE_VALUE_05 "Stored Automatic numbering table";
BA_ "FlexKomIsMotorola" SG_ 1617 NUM_TABLE_VALUE_05 1;
BA_ "GenSigSendType" SG_ 1617 BLC_DRV_STAT_12_05 0;
BA_ "GenSigCycleTime" SG_ 1617 BLC_DRV_STAT_12_05 40;
BA_ "FlexKomSigStartValue" SG_ 1617 BLC_DRV_STAT_12_05 "0000h";
BA_ "GenSigTimeout_BMU" SG_ 1617 BLC_DRV_STAT_12_05 220;
BA_ "FlexKomSID" SG_ 1617 BLC_DRV_STAT_12_05 726;
BA_ "FlexKomSigStartPos" SG_ 1617 BLC_DRV_STAT_12_05 7;
BA_ "FlexKomSigLaenge" SG_ 1617 BLC_DRV_STAT_12_05 16;
BA_ "FlexKomSigName" SG_ 1617 BLC_DRV_STAT_12_05 "BLC_DRV_STAT_05";
BA_ "FlexKomComment" SG_ 1617 BLC_DRV_STAT_12_05 "Balancer drive status packet";
BA_ "FlexKomIsMotorola" SG_ 1617 BLC_DRV_STAT_12_05 1;
BA_ "GenSigSendType" SG_ 1617 BLC_DRV_STAT_11_05 0;
BA_ "GenSigCycleTime" SG_ 1617 BLC_DRV_STAT_11_05 40;
BA_ "FlexKomSigStartValue" SG_ 1617 BLC_DRV_STAT_11_05 "0000h";
BA_ "GenSigTimeout_BMU" SG_ 1617 BLC_DRV_STAT_11_05 220;
BA_ "FlexKomSID" SG_ 1617 BLC_DRV_STAT_11_05 726;
BA_ "FlexKomSigStartPos" SG_ 1617 BLC_DRV_STAT_11_05 7;
BA_ "FlexKomSigLaenge" SG_ 1617 BLC_DRV_STAT_11_05 16;
BA_ "FlexKomSigName" SG_ 1617 BLC_DRV_STAT_11_05 "BLC_DRV_STAT_05";
BA_ "FlexKomComment" SG_ 1617 BLC_DRV_STAT_11_05 "Balancer drive status packet";
BA_ "FlexKomIsMotorola" SG_ 1617 BLC_DRV_STAT_11_05 1;
BA_ "GenSigSendType" SG_ 1617 BLC_DRV_STAT_10_05 0;
BA_ "GenSigCycleTime" SG_ 1617 BLC_DRV_STAT_10_05 40;
BA_ "FlexKomSigStartValue" SG_ 1617 BLC_DRV_STAT_10_05 "0000h";
BA_ "GenSigTimeout_BMU" SG_ 1617 BLC_DRV_STAT_10_05 220;
BA_ "FlexKomSID" SG_ 1617 BLC_DRV_STAT_10_05 726;
BA_ "FlexKomSigStartPos" SG_ 1617 BLC_DRV_STAT_10_05 7;
BA_ "FlexKomSigLaenge" SG_ 1617 BLC_DRV_STAT_10_05 16;
BA_ "FlexKomSigName" SG_ 1617 BLC_DRV_STAT_10_05 "BLC_DRV_STAT_05";
BA_ "FlexKomComment" SG_ 1617 BLC_DRV_STAT_10_05 "Balancer drive status packet";
BA_ "FlexKomIsMotorola" SG_ 1617 BLC_DRV_STAT_10_05 1;
BA_ "GenSigSendType" SG_ 1617 BLC_DRV_STAT_09_05 0;
BA_ "GenSigCycleTime" SG_ 1617 BLC_DRV_STAT_09_05 40;
BA_ "FlexKomSigStartValue" SG_ 1617 BLC_DRV_STAT_09_05 "0000h";
BA_ "GenSigTimeout_BMU" SG_ 1617 BLC_DRV_STAT_09_05 220;
BA_ "FlexKomSID" SG_ 1617 BLC_DRV_STAT_09_05 726;
BA_ "FlexKomSigStartPos" SG_ 1617 BLC_DRV_STAT_09_05 7;
BA_ "FlexKomSigLaenge" SG_ 1617 BLC_DRV_STAT_09_05 16;
BA_ "FlexKomSigName" SG_ 1617 BLC_DRV_STAT_09_05 "BLC_DRV_STAT_05";
BA_ "FlexKomComment" SG_ 1617 BLC_DRV_STAT_09_05 "Balancer drive status packet";
BA_ "FlexKomIsMotorola" SG_ 1617 BLC_DRV_STAT_09_05 1;
BA_ "GenSigSendType" SG_ 1617 BLC_DRV_STAT_08_05 0;
BA_ "GenSigCycleTime" SG_ 1617 BLC_DRV_STAT_08_05 40;
BA_ "FlexKomSigStartValue" SG_ 1617 BLC_DRV_STAT_08_05 "0000h";
BA_ "GenSigTimeout_BMU" SG_ 1617 BLC_DRV_STAT_08_05 220;
BA_ "FlexKomSID" SG_ 1617 BLC_DRV_STAT_08_05 726;
BA_ "FlexKomSigStartPos" SG_ 1617 BLC_DRV_STAT_08_05 7;
BA_ "FlexKomSigLaenge" SG_ 1617 BLC_DRV_STAT_08_05 16;
BA_ "FlexKomSigName" SG_ 1617 BLC_DRV_STAT_08_05 "BLC_DRV_STAT_05";
BA_ "FlexKomComment" SG_ 1617 BLC_DRV_STAT_08_05 "Balancer drive status packet";
BA_ "FlexKomIsMotorola" SG_ 1617 BLC_DRV_STAT_08_05 1;
BA_ "GenSigSendType" SG_ 1617 BLC_DRV_STAT_07_05 0;
BA_ "GenSigCycleTime" SG_ 1617 BLC_DRV_STAT_07_05 40;
BA_ "FlexKomSigStartValue" SG_ 1617 BLC_DRV_STAT_07_05 "0000h";
BA_ "GenSigTimeout_BMU" SG_ 1617 BLC_DRV_STAT_07_05 220;
BA_ "FlexKomSID" SG_ 1617 BLC_DRV_STAT_07_05 726;
BA_ "FlexKomSigStartPos" SG_ 1617 BLC_DRV_STAT_07_05 7;
BA_ "FlexKomSigLaenge" SG_ 1617 BLC_DRV_STAT_07_05 16;
BA_ "FlexKomSigName" SG_ 1617 BLC_DRV_STAT_07_05 "BLC_DRV_STAT_05";
BA_ "FlexKomComment" SG_ 1617 BLC_DRV_STAT_07_05 "Balancer drive status packet";
BA_ "FlexKomIsMotorola" SG_ 1617 BLC_DRV_STAT_07_05 1;
BA_ "GenSigSendType" SG_ 1617 BLC_DRV_STAT_06_05 0;
BA_ "GenSigCycleTime" SG_ 1617 BLC_DRV_STAT_06_05 40;
BA_ "FlexKomSigStartValue" SG_ 1617 BLC_DRV_STAT_06_05 "0000h";
BA_ "GenSigTimeout_BMU" SG_ 1617 BLC_DRV_STAT_06_05 220;
BA_ "FlexKomSID" SG_ 1617 BLC_DRV_STAT_06_05 726;
BA_ "FlexKomSigStartPos" SG_ 1617 BLC_DRV_STAT_06_05 7;
BA_ "FlexKomSigLaenge" SG_ 1617 BLC_DRV_STAT_06_05 16;
BA_ "FlexKomSigName" SG_ 1617 BLC_DRV_STAT_06_05 "BLC_DRV_STAT_05";
BA_ "FlexKomComment" SG_ 1617 BLC_DRV_STAT_06_05 "Balancer drive status packet";
BA_ "FlexKomIsMotorola" SG_ 1617 BLC_DRV_STAT_06_05 1;
BA_ "GenSigSendType" SG_ 1617 BLC_DRV_STAT_05_05 0;
BA_ "GenSigCycleTime" SG_ 1617 BLC_DRV_STAT_05_05 40;
BA_ "FlexKomSigStartValue" SG_ 1617 BLC_DRV_STAT_05_05 "0000h";
BA_ "GenSigTimeout_BMU" SG_ 1617 BLC_DRV_STAT_05_05 220;
BA_ "FlexKomSID" SG_ 1617 BLC_DRV_STAT_05_05 726;
BA_ "FlexKomSigStartPos" SG_ 1617 BLC_DRV_STAT_05_05 7;
BA_ "FlexKomSigLaenge" SG_ 1617 BLC_DRV_STAT_05_05 16;
BA_ "FlexKomSigName" SG_ 1617 BLC_DRV_STAT_05_05 "BLC_DRV_STAT_05";
BA_ "FlexKomComment" SG_ 1617 BLC_DRV_STAT_05_05 "Balancer drive status packet";
BA_ "FlexKomIsMotorola" SG_ 1617 BLC_DRV_STAT_05_05 1;
BA_ "GenSigSendType" SG_ 1617 BLC_DRV_STAT_04_05 0;
BA_ "GenSigCycleTime" SG_ 1617 BLC_DRV_STAT_04_05 40;
BA_ "FlexKomSigStartValue" SG_ 1617 BLC_DRV_STAT_04_05 "0000h";
BA_ "GenSigTimeout_BMU" SG_ 1617 BLC_DRV_STAT_04_05 220;
BA_ "FlexKomSID" SG_ 1617 BLC_DRV_STAT_04_05 726;
BA_ "FlexKomSigStartPos" SG_ 1617 BLC_DRV_STAT_04_05 7;
BA_ "FlexKomSigLaenge" SG_ 1617 BLC_DRV_STAT_04_05 16;
BA_ "FlexKomSigName" SG_ 1617 BLC_DRV_STAT_04_05 "BLC_DRV_STAT_05";
BA_ "FlexKomComment" SG_ 1617 BLC_DRV_STAT_04_05 "Balancer drive status packet";
BA_ "FlexKomIsMotorola" SG_ 1617 BLC_DRV_STAT_04_05 1;
BA_ "GenSigSendType" SG_ 1617 BLC_DRV_STAT_03_05 0;
BA_ "GenSigCycleTime" SG_ 1617 BLC_DRV_STAT_03_05 40;
BA_ "FlexKomSigStartValue" SG_ 1617 BLC_DRV_STAT_03_05 "0000h";
BA_ "GenSigTimeout_BMU" SG_ 1617 BLC_DRV_STAT_03_05 220;
BA_ "FlexKomSID" SG_ 1617 BLC_DRV_STAT_03_05 726;
BA_ "FlexKomSigStartPos" SG_ 1617 BLC_DRV_STAT_03_05 7;
BA_ "FlexKomSigLaenge" SG_ 1617 BLC_DRV_STAT_03_05 16;
BA_ "FlexKomSigName" SG_ 1617 BLC_DRV_STAT_03_05 "BLC_DRV_STAT_05";
BA_ "FlexKomComment" SG_ 1617 BLC_DRV_STAT_03_05 "Balancer drive status packet";
BA_ "FlexKomIsMotorola" SG_ 1617 BLC_DRV_STAT_03_05 1;
BA_ "GenSigSendType" SG_ 1617 BLC_DRV_STAT_02_05 0;
BA_ "GenSigCycleTime" SG_ 1617 BLC_DRV_STAT_02_05 40;
BA_ "FlexKomSigStartValue" SG_ 1617 BLC_DRV_STAT_02_05 "0000h";
BA_ "GenSigTimeout_BMU" SG_ 1617 BLC_DRV_STAT_02_05 220;
BA_ "FlexKomSID" SG_ 1617 BLC_DRV_STAT_02_05 726;
BA_ "FlexKomSigStartPos" SG_ 1617 BLC_DRV_STAT_02_05 7;
BA_ "FlexKomSigLaenge" SG_ 1617 BLC_DRV_STAT_02_05 16;
BA_ "FlexKomSigName" SG_ 1617 BLC_DRV_STAT_02_05 "BLC_DRV_STAT_05";
BA_ "FlexKomComment" SG_ 1617 BLC_DRV_STAT_02_05 "Balancer drive status packet";
BA_ "FlexKomIsMotorola" SG_ 1617 BLC_DRV_STAT_02_05 1;
BA_ "GenSigSendType" SG_ 1617 BLC_DRV_STAT_01_05 0;
BA_ "GenSigCycleTime" SG_ 1617 BLC_DRV_STAT_01_05 40;
BA_ "FlexKomSigStartValue" SG_ 1617 BLC_DRV_STAT_01_05 "0000h";
BA_ "GenSigTimeout_BMU" SG_ 1617 BLC_DRV_STAT_01_05 220;
BA_ "FlexKomSID" SG_ 1617 BLC_DRV_STAT_01_05 726;
BA_ "FlexKomSigStartPos" SG_ 1617 BLC_DRV_STAT_01_05 7;
BA_ "FlexKomSigLaenge" SG_ 1617 BLC_DRV_STAT_01_05 16;
BA_ "FlexKomSigName" SG_ 1617 BLC_DRV_STAT_01_05 "BLC_DRV_STAT_05";
BA_ "FlexKomComment" SG_ 1617 BLC_DRV_STAT_01_05 "Balancer drive status packet";
BA_ "FlexKomIsMotorola" SG_ 1617 BLC_DRV_STAT_01_05 1;
BA_ "GenSigSendType" SG_ 1601 MODULE_TEMP_06_04 0;
BA_ "GenSigCycleTime" SG_ 1601 MODULE_TEMP_06_04 40;
BA_ "FlexKomSigStartValue" SG_ 1601 MODULE_TEMP_06_04 "00h";
BA_ "GenSigTimeout_BMU" SG_ 1601 MODULE_TEMP_06_04 220;
BA_ "FlexKomSID" SG_ 1601 MODULE_TEMP_06_04 1102;
BA_ "FlexKomSigStartPos" SG_ 1601 MODULE_TEMP_06_04 63;
BA_ "FlexKomSigLaenge" SG_ 1601 MODULE_TEMP_06_04 8;
BA_ "FlexKomSigName" SG_ 1601 MODULE_TEMP_06_04 "MODULE_TEMP_06_04";
BA_ "FlexKomComment" SG_ 1601 MODULE_TEMP_06_04 "Module temperature06";
BA_ "FlexKomIsMotorola" SG_ 1601 MODULE_TEMP_06_04 1;
BA_ "GenSigSendType" SG_ 1601 MODULE_TEMP_05_04 0;
BA_ "GenSigCycleTime" SG_ 1601 MODULE_TEMP_05_04 40;
BA_ "FlexKomSigStartValue" SG_ 1601 MODULE_TEMP_05_04 "00h";
BA_ "GenSigTimeout_BMU" SG_ 1601 MODULE_TEMP_05_04 220;
BA_ "FlexKomSID" SG_ 1601 MODULE_TEMP_05_04 1090;
BA_ "FlexKomSigStartPos" SG_ 1601 MODULE_TEMP_05_04 55;
BA_ "FlexKomSigLaenge" SG_ 1601 MODULE_TEMP_05_04 8;
BA_ "FlexKomSigName" SG_ 1601 MODULE_TEMP_05_04 "MODULE_TEMP_05_04";
BA_ "FlexKomComment" SG_ 1601 MODULE_TEMP_05_04 "Module temperature05";
BA_ "FlexKomIsMotorola" SG_ 1601 MODULE_TEMP_05_04 1;
BA_ "GenSigSendType" SG_ 1601 MODULE_TEMP_04_04 0;
BA_ "GenSigCycleTime" SG_ 1601 MODULE_TEMP_04_04 40;
BA_ "FlexKomSigStartValue" SG_ 1601 MODULE_TEMP_04_04 "00h";
BA_ "GenSigTimeout_BMU" SG_ 1601 MODULE_TEMP_04_04 220;
BA_ "FlexKomSID" SG_ 1601 MODULE_TEMP_04_04 1078;
BA_ "FlexKomSigStartPos" SG_ 1601 MODULE_TEMP_04_04 47;
BA_ "FlexKomSigLaenge" SG_ 1601 MODULE_TEMP_04_04 8;
BA_ "FlexKomSigName" SG_ 1601 MODULE_TEMP_04_04 "MODULE_TEMP_04_04";
BA_ "FlexKomComment" SG_ 1601 MODULE_TEMP_04_04 "Module temperature04";
BA_ "FlexKomIsMotorola" SG_ 1601 MODULE_TEMP_04_04 1;
BA_ "GenSigSendType" SG_ 1601 MODULE_TEMP_03_04 0;
BA_ "GenSigCycleTime" SG_ 1601 MODULE_TEMP_03_04 40;
BA_ "FlexKomSigStartValue" SG_ 1601 MODULE_TEMP_03_04 "00h";
BA_ "GenSigTimeout_BMU" SG_ 1601 MODULE_TEMP_03_04 220;
BA_ "FlexKomSID" SG_ 1601 MODULE_TEMP_03_04 1066;
BA_ "FlexKomSigStartPos" SG_ 1601 MODULE_TEMP_03_04 39;
BA_ "FlexKomSigLaenge" SG_ 1601 MODULE_TEMP_03_04 8;
BA_ "FlexKomSigName" SG_ 1601 MODULE_TEMP_03_04 "MODULE_TEMP_03_04";
BA_ "FlexKomComment" SG_ 1601 MODULE_TEMP_03_04 "Module temperature03";
BA_ "FlexKomIsMotorola" SG_ 1601 MODULE_TEMP_03_04 1;
BA_ "GenSigSendType" SG_ 1601 MODULE_TEMP_02_04 0;
BA_ "GenSigCycleTime" SG_ 1601 MODULE_TEMP_02_04 40;
BA_ "FlexKomSigStartValue" SG_ 1601 MODULE_TEMP_02_04 "00h";
BA_ "GenSigTimeout_BMU" SG_ 1601 MODULE_TEMP_02_04 220;
BA_ "FlexKomSID" SG_ 1601 MODULE_TEMP_02_04 1054;
BA_ "FlexKomSigStartPos" SG_ 1601 MODULE_TEMP_02_04 31;
BA_ "FlexKomSigLaenge" SG_ 1601 MODULE_TEMP_02_04 8;
BA_ "FlexKomSigName" SG_ 1601 MODULE_TEMP_02_04 "MODULE_TEMP_02_04";
BA_ "FlexKomComment" SG_ 1601 MODULE_TEMP_02_04 "Module temperature02";
BA_ "FlexKomIsMotorola" SG_ 1601 MODULE_TEMP_02_04 1;
BA_ "GenSigSendType" SG_ 1601 MODULE_TEMP_01_04 0;
BA_ "GenSigCycleTime" SG_ 1601 MODULE_TEMP_01_04 40;
BA_ "FlexKomSigStartValue" SG_ 1601 MODULE_TEMP_01_04 "00h";
BA_ "GenSigTimeout_BMU" SG_ 1601 MODULE_TEMP_01_04 220;
BA_ "FlexKomSID" SG_ 1601 MODULE_TEMP_01_04 1042;
BA_ "FlexKomSigStartPos" SG_ 1601 MODULE_TEMP_01_04 23;
BA_ "FlexKomSigLaenge" SG_ 1601 MODULE_TEMP_01_04 8;
BA_ "FlexKomSigName" SG_ 1601 MODULE_TEMP_01_04 "MODULE_TEMP_01_04";
BA_ "FlexKomComment" SG_ 1601 MODULE_TEMP_01_04 "Module temperature01";
BA_ "FlexKomIsMotorola" SG_ 1601 MODULE_TEMP_01_04 1;
BA_ "GenSigSendType" SG_ 1601 NUM_TABLE_VALUE_04 0;
BA_ "GenSigCycleTime" SG_ 1601 NUM_TABLE_VALUE_04 40;
BA_ "FlexKomSigStartValue" SG_ 1601 NUM_TABLE_VALUE_04 "0Fh";
BA_ "GenSigStartValue" SG_ 1601 NUM_TABLE_VALUE_04 15;
BA_ "GenSigTimeout_BMU" SG_ 1601 NUM_TABLE_VALUE_04 220;
BA_ "FlexKomSID" SG_ 1601 NUM_TABLE_VALUE_04 1030;
BA_ "FlexKomSigStartPos" SG_ 1601 NUM_TABLE_VALUE_04 15;
BA_ "FlexKomSigLaenge" SG_ 1601 NUM_TABLE_VALUE_04 4;
BA_ "FlexKomSigName" SG_ 1601 NUM_TABLE_VALUE_04 "NUM_TABLE_VALUE_04";
BA_ "FlexKomComment" SG_ 1601 NUM_TABLE_VALUE_04 "Stored Automatic numbering table";
BA_ "FlexKomIsMotorola" SG_ 1601 NUM_TABLE_VALUE_04 1;
BA_ "GenSigSendType" SG_ 1601 BLC_DRV_STAT_12_04 0;
BA_ "GenSigCycleTime" SG_ 1601 BLC_DRV_STAT_12_04 40;
BA_ "FlexKomSigStartValue" SG_ 1601 BLC_DRV_STAT_12_04 "0000h";
BA_ "GenSigTimeout_BMU" SG_ 1601 BLC_DRV_STAT_12_04 220;
BA_ "FlexKomSID" SG_ 1601 BLC_DRV_STAT_12_04 727;
BA_ "FlexKomSigStartPos" SG_ 1601 BLC_DRV_STAT_12_04 7;
BA_ "FlexKomSigLaenge" SG_ 1601 BLC_DRV_STAT_12_04 16;
BA_ "FlexKomSigName" SG_ 1601 BLC_DRV_STAT_12_04 "BLC_DRV_STAT_04";
BA_ "FlexKomComment" SG_ 1601 BLC_DRV_STAT_12_04 "Balancer drive status packet";
BA_ "FlexKomIsMotorola" SG_ 1601 BLC_DRV_STAT_12_04 1;
BA_ "GenSigSendType" SG_ 1601 BLC_DRV_STAT_11_04 0;
BA_ "GenSigCycleTime" SG_ 1601 BLC_DRV_STAT_11_04 40;
BA_ "FlexKomSigStartValue" SG_ 1601 BLC_DRV_STAT_11_04 "0000h";
BA_ "GenSigTimeout_BMU" SG_ 1601 BLC_DRV_STAT_11_04 220;
BA_ "FlexKomSID" SG_ 1601 BLC_DRV_STAT_11_04 727;
BA_ "FlexKomSigStartPos" SG_ 1601 BLC_DRV_STAT_11_04 7;
BA_ "FlexKomSigLaenge" SG_ 1601 BLC_DRV_STAT_11_04 16;
BA_ "FlexKomSigName" SG_ 1601 BLC_DRV_STAT_11_04 "BLC_DRV_STAT_04";
BA_ "FlexKomComment" SG_ 1601 BLC_DRV_STAT_11_04 "Balancer drive status packet";
BA_ "FlexKomIsMotorola" SG_ 1601 BLC_DRV_STAT_11_04 1;
BA_ "GenSigSendType" SG_ 1601 BLC_DRV_STAT_10_04 0;
BA_ "GenSigCycleTime" SG_ 1601 BLC_DRV_STAT_10_04 40;
BA_ "FlexKomSigStartValue" SG_ 1601 BLC_DRV_STAT_10_04 "0000h";
BA_ "GenSigTimeout_BMU" SG_ 1601 BLC_DRV_STAT_10_04 220;
BA_ "FlexKomSID" SG_ 1601 BLC_DRV_STAT_10_04 727;
BA_ "FlexKomSigStartPos" SG_ 1601 BLC_DRV_STAT_10_04 7;
BA_ "FlexKomSigLaenge" SG_ 1601 BLC_DRV_STAT_10_04 16;
BA_ "FlexKomSigName" SG_ 1601 BLC_DRV_STAT_10_04 "BLC_DRV_STAT_04";
BA_ "FlexKomComment" SG_ 1601 BLC_DRV_STAT_10_04 "Balancer drive status packet";
BA_ "FlexKomIsMotorola" SG_ 1601 BLC_DRV_STAT_10_04 1;
BA_ "GenSigSendType" SG_ 1601 BLC_DRV_STAT_09_04 0;
BA_ "GenSigCycleTime" SG_ 1601 BLC_DRV_STAT_09_04 40;
BA_ "FlexKomSigStartValue" SG_ 1601 BLC_DRV_STAT_09_04 "0000h";
BA_ "GenSigTimeout_BMU" SG_ 1601 BLC_DRV_STAT_09_04 220;
BA_ "FlexKomSID" SG_ 1601 BLC_DRV_STAT_09_04 727;
BA_ "FlexKomSigStartPos" SG_ 1601 BLC_DRV_STAT_09_04 7;
BA_ "FlexKomSigLaenge" SG_ 1601 BLC_DRV_STAT_09_04 16;
BA_ "FlexKomSigName" SG_ 1601 BLC_DRV_STAT_09_04 "BLC_DRV_STAT_04";
BA_ "FlexKomComment" SG_ 1601 BLC_DRV_STAT_09_04 "Balancer drive status packet";
BA_ "FlexKomIsMotorola" SG_ 1601 BLC_DRV_STAT_09_04 1;
BA_ "GenSigSendType" SG_ 1601 BLC_DRV_STAT_08_04 0;
BA_ "GenSigCycleTime" SG_ 1601 BLC_DRV_STAT_08_04 40;
BA_ "FlexKomSigStartValue" SG_ 1601 BLC_DRV_STAT_08_04 "0000h";
BA_ "GenSigTimeout_BMU" SG_ 1601 BLC_DRV_STAT_08_04 220;
BA_ "FlexKomSID" SG_ 1601 BLC_DRV_STAT_08_04 727;
BA_ "FlexKomSigStartPos" SG_ 1601 BLC_DRV_STAT_08_04 7;
BA_ "FlexKomSigLaenge" SG_ 1601 BLC_DRV_STAT_08_04 16;
BA_ "FlexKomSigName" SG_ 1601 BLC_DRV_STAT_08_04 "BLC_DRV_STAT_04";
BA_ "FlexKomComment" SG_ 1601 BLC_DRV_STAT_08_04 "Balancer drive status packet";
BA_ "FlexKomIsMotorola" SG_ 1601 BLC_DRV_STAT_08_04 1;
BA_ "GenSigSendType" SG_ 1601 BLC_DRV_STAT_07_04 0;
BA_ "GenSigCycleTime" SG_ 1601 BLC_DRV_STAT_07_04 40;
BA_ "FlexKomSigStartValue" SG_ 1601 BLC_DRV_STAT_07_04 "0000h";
BA_ "GenSigTimeout_BMU" SG_ 1601 BLC_DRV_STAT_07_04 220;
BA_ "FlexKomSID" SG_ 1601 BLC_DRV_STAT_07_04 727;
BA_ "FlexKomSigStartPos" SG_ 1601 BLC_DRV_STAT_07_04 7;
BA_ "FlexKomSigLaenge" SG_ 1601 BLC_DRV_STAT_07_04 16;
BA_ "FlexKomSigName" SG_ 1601 BLC_DRV_STAT_07_04 "BLC_DRV_STAT_04";
BA_ "FlexKomComment" SG_ 1601 BLC_DRV_STAT_07_04 "Balancer drive status packet";
BA_ "FlexKomIsMotorola" SG_ 1601 BLC_DRV_STAT_07_04 1;
BA_ "GenSigSendType" SG_ 1601 BLC_DRV_STAT_06_04 0;
BA_ "GenSigCycleTime" SG_ 1601 BLC_DRV_STAT_06_04 40;
BA_ "FlexKomSigStartValue" SG_ 1601 BLC_DRV_STAT_06_04 "0000h";
BA_ "GenSigTimeout_BMU" SG_ 1601 BLC_DRV_STAT_06_04 220;
BA_ "FlexKomSID" SG_ 1601 BLC_DRV_STAT_06_04 727;
BA_ "FlexKomSigStartPos" SG_ 1601 BLC_DRV_STAT_06_04 7;
BA_ "FlexKomSigLaenge" SG_ 1601 BLC_DRV_STAT_06_04 16;
BA_ "FlexKomSigName" SG_ 1601 BLC_DRV_STAT_06_04 "BLC_DRV_STAT_04";
BA_ "FlexKomComment" SG_ 1601 BLC_DRV_STAT_06_04 "Balancer drive status packet";
BA_ "FlexKomIsMotorola" SG_ 1601 BLC_DRV_STAT_06_04 1;
BA_ "GenSigSendType" SG_ 1601 BLC_DRV_STAT_05_04 0;
BA_ "GenSigCycleTime" SG_ 1601 BLC_DRV_STAT_05_04 40;
BA_ "FlexKomSigStartValue" SG_ 1601 BLC_DRV_STAT_05_04 "0000h";
BA_ "GenSigTimeout_BMU" SG_ 1601 BLC_DRV_STAT_05_04 220;
BA_ "FlexKomSID" SG_ 1601 BLC_DRV_STAT_05_04 727;
BA_ "FlexKomSigStartPos" SG_ 1601 BLC_DRV_STAT_05_04 7;
BA_ "FlexKomSigLaenge" SG_ 1601 BLC_DRV_STAT_05_04 16;
BA_ "FlexKomSigName" SG_ 1601 BLC_DRV_STAT_05_04 "BLC_DRV_STAT_04";
BA_ "FlexKomComment" SG_ 1601 BLC_DRV_STAT_05_04 "Balancer drive status packet";
BA_ "FlexKomIsMotorola" SG_ 1601 BLC_DRV_STAT_05_04 1;
BA_ "GenSigSendType" SG_ 1601 BLC_DRV_STAT_04_04 0;
BA_ "GenSigCycleTime" SG_ 1601 BLC_DRV_STAT_04_04 40;
BA_ "FlexKomSigStartValue" SG_ 1601 BLC_DRV_STAT_04_04 "0000h";
BA_ "GenSigTimeout_BMU" SG_ 1601 BLC_DRV_STAT_04_04 220;
BA_ "FlexKomSID" SG_ 1601 BLC_DRV_STAT_04_04 727;
BA_ "FlexKomSigStartPos" SG_ 1601 BLC_DRV_STAT_04_04 7;
BA_ "FlexKomSigLaenge" SG_ 1601 BLC_DRV_STAT_04_04 16;
BA_ "FlexKomSigName" SG_ 1601 BLC_DRV_STAT_04_04 "BLC_DRV_STAT_04";
BA_ "FlexKomComment" SG_ 1601 BLC_DRV_STAT_04_04 "Balancer drive status packet";
BA_ "FlexKomIsMotorola" SG_ 1601 BLC_DRV_STAT_04_04 1;
BA_ "GenSigSendType" SG_ 1601 BLC_DRV_STAT_03_04 0;
BA_ "GenSigCycleTime" SG_ 1601 BLC_DRV_STAT_03_04 40;
BA_ "FlexKomSigStartValue" SG_ 1601 BLC_DRV_STAT_03_04 "0000h";
BA_ "GenSigTimeout_BMU" SG_ 1601 BLC_DRV_STAT_03_04 220;
BA_ "FlexKomSID" SG_ 1601 BLC_DRV_STAT_03_04 727;
BA_ "FlexKomSigStartPos" SG_ 1601 BLC_DRV_STAT_03_04 7;
BA_ "FlexKomSigLaenge" SG_ 1601 BLC_DRV_STAT_03_04 16;
BA_ "FlexKomSigName" SG_ 1601 BLC_DRV_STAT_03_04 "BLC_DRV_STAT_04";
BA_ "FlexKomComment" SG_ 1601 BLC_DRV_STAT_03_04 "Balancer drive status packet";
BA_ "FlexKomIsMotorola" SG_ 1601 BLC_DRV_STAT_03_04 1;
BA_ "GenSigSendType" SG_ 1601 BLC_DRV_STAT_02_04 0;
BA_ "GenSigCycleTime" SG_ 1601 BLC_DRV_STAT_02_04 40;
BA_ "FlexKomSigStartValue" SG_ 1601 BLC_DRV_STAT_02_04 "0000h";
BA_ "GenSigTimeout_BMU" SG_ 1601 BLC_DRV_STAT_02_04 220;
BA_ "FlexKomSID" SG_ 1601 BLC_DRV_STAT_02_04 727;
BA_ "FlexKomSigStartPos" SG_ 1601 BLC_DRV_STAT_02_04 7;
BA_ "FlexKomSigLaenge" SG_ 1601 BLC_DRV_STAT_02_04 16;
BA_ "FlexKomSigName" SG_ 1601 BLC_DRV_STAT_02_04 "BLC_DRV_STAT_04";
BA_ "FlexKomComment" SG_ 1601 BLC_DRV_STAT_02_04 "Balancer drive status packet";
BA_ "FlexKomIsMotorola" SG_ 1601 BLC_DRV_STAT_02_04 1;
BA_ "GenSigSendType" SG_ 1601 BLC_DRV_STAT_01_04 0;
BA_ "GenSigCycleTime" SG_ 1601 BLC_DRV_STAT_01_04 40;
BA_ "FlexKomSigStartValue" SG_ 1601 BLC_DRV_STAT_01_04 "0000h";
BA_ "GenSigTimeout_BMU" SG_ 1601 BLC_DRV_STAT_01_04 220;
BA_ "FlexKomSID" SG_ 1601 BLC_DRV_STAT_01_04 727;
BA_ "FlexKomSigStartPos" SG_ 1601 BLC_DRV_STAT_01_04 7;
BA_ "FlexKomSigLaenge" SG_ 1601 BLC_DRV_STAT_01_04 16;
BA_ "FlexKomSigName" SG_ 1601 BLC_DRV_STAT_01_04 "BLC_DRV_STAT_04";
BA_ "FlexKomComment" SG_ 1601 BLC_DRV_STAT_01_04 "Balancer drive status packet";
BA_ "FlexKomIsMotorola" SG_ 1601 BLC_DRV_STAT_01_04 1;
BA_ "GenSigSendType" SG_ 1585 MODULE_TEMP_06_03 0;
BA_ "GenSigCycleTime" SG_ 1585 MODULE_TEMP_06_03 40;
BA_ "FlexKomSigStartValue" SG_ 1585 MODULE_TEMP_06_03 "00h";
BA_ "GenSigTimeout_BMU" SG_ 1585 MODULE_TEMP_06_03 220;
BA_ "FlexKomSID" SG_ 1585 MODULE_TEMP_06_03 1101;
BA_ "FlexKomSigStartPos" SG_ 1585 MODULE_TEMP_06_03 63;
BA_ "FlexKomSigLaenge" SG_ 1585 MODULE_TEMP_06_03 8;
BA_ "FlexKomSigName" SG_ 1585 MODULE_TEMP_06_03 "MODULE_TEMP_06_03";
BA_ "FlexKomComment" SG_ 1585 MODULE_TEMP_06_03 "Module temperature06";
BA_ "FlexKomIsMotorola" SG_ 1585 MODULE_TEMP_06_03 1;
BA_ "GenSigSendType" SG_ 1585 MODULE_TEMP_05_03 0;
BA_ "GenSigCycleTime" SG_ 1585 MODULE_TEMP_05_03 40;
BA_ "FlexKomSigStartValue" SG_ 1585 MODULE_TEMP_05_03 "00h";
BA_ "GenSigTimeout_BMU" SG_ 1585 MODULE_TEMP_05_03 220;
BA_ "FlexKomSID" SG_ 1585 MODULE_TEMP_05_03 1089;
BA_ "FlexKomSigStartPos" SG_ 1585 MODULE_TEMP_05_03 55;
BA_ "FlexKomSigLaenge" SG_ 1585 MODULE_TEMP_05_03 8;
BA_ "FlexKomSigName" SG_ 1585 MODULE_TEMP_05_03 "MODULE_TEMP_05_03";
BA_ "FlexKomComment" SG_ 1585 MODULE_TEMP_05_03 "Module temperature05";
BA_ "FlexKomIsMotorola" SG_ 1585 MODULE_TEMP_05_03 1;
BA_ "GenSigSendType" SG_ 1585 MODULE_TEMP_04_03 0;
BA_ "GenSigCycleTime" SG_ 1585 MODULE_TEMP_04_03 40;
BA_ "FlexKomSigStartValue" SG_ 1585 MODULE_TEMP_04_03 "00h";
BA_ "GenSigTimeout_BMU" SG_ 1585 MODULE_TEMP_04_03 220;
BA_ "FlexKomSID" SG_ 1585 MODULE_TEMP_04_03 1077;
BA_ "FlexKomSigStartPos" SG_ 1585 MODULE_TEMP_04_03 47;
BA_ "FlexKomSigLaenge" SG_ 1585 MODULE_TEMP_04_03 8;
BA_ "FlexKomSigName" SG_ 1585 MODULE_TEMP_04_03 "MODULE_TEMP_04_03";
BA_ "FlexKomComment" SG_ 1585 MODULE_TEMP_04_03 "Module temperature04";
BA_ "FlexKomIsMotorola" SG_ 1585 MODULE_TEMP_04_03 1;
BA_ "GenSigSendType" SG_ 1585 MODULE_TEMP_03_03 0;
BA_ "GenSigCycleTime" SG_ 1585 MODULE_TEMP_03_03 40;
BA_ "FlexKomSigStartValue" SG_ 1585 MODULE_TEMP_03_03 "00h";
BA_ "GenSigTimeout_BMU" SG_ 1585 MODULE_TEMP_03_03 220;
BA_ "FlexKomSID" SG_ 1585 MODULE_TEMP_03_03 1065;
BA_ "FlexKomSigStartPos" SG_ 1585 MODULE_TEMP_03_03 39;
BA_ "FlexKomSigLaenge" SG_ 1585 MODULE_TEMP_03_03 8;
BA_ "FlexKomSigName" SG_ 1585 MODULE_TEMP_03_03 "MODULE_TEMP_03_03";
BA_ "FlexKomComment" SG_ 1585 MODULE_TEMP_03_03 "Module temperature03";
BA_ "FlexKomIsMotorola" SG_ 1585 MODULE_TEMP_03_03 1;
BA_ "GenSigSendType" SG_ 1585 MODULE_TEMP_02_03 0;
BA_ "GenSigCycleTime" SG_ 1585 MODULE_TEMP_02_03 40;
BA_ "FlexKomSigStartValue" SG_ 1585 MODULE_TEMP_02_03 "00h";
BA_ "GenSigTimeout_BMU" SG_ 1585 MODULE_TEMP_02_03 220;
BA_ "FlexKomSID" SG_ 1585 MODULE_TEMP_02_03 1053;
BA_ "FlexKomSigStartPos" SG_ 1585 MODULE_TEMP_02_03 31;
BA_ "FlexKomSigLaenge" SG_ 1585 MODULE_TEMP_02_03 8;
BA_ "FlexKomSigName" SG_ 1585 MODULE_TEMP_02_03 "MODULE_TEMP_02_03";
BA_ "FlexKomComment" SG_ 1585 MODULE_TEMP_02_03 "Module temperature02";
BA_ "FlexKomIsMotorola" SG_ 1585 MODULE_TEMP_02_03 1;
BA_ "GenSigSendType" SG_ 1585 MODULE_TEMP_01_03 0;
BA_ "GenSigCycleTime" SG_ 1585 MODULE_TEMP_01_03 40;
BA_ "FlexKomSigStartValue" SG_ 1585 MODULE_TEMP_01_03 "00h";
BA_ "GenSigTimeout_BMU" SG_ 1585 MODULE_TEMP_01_03 220;
BA_ "FlexKomSID" SG_ 1585 MODULE_TEMP_01_03 1041;
BA_ "FlexKomSigStartPos" SG_ 1585 MODULE_TEMP_01_03 23;
BA_ "FlexKomSigLaenge" SG_ 1585 MODULE_TEMP_01_03 8;
BA_ "FlexKomSigName" SG_ 1585 MODULE_TEMP_01_03 "MODULE_TEMP_01_03";
BA_ "FlexKomComment" SG_ 1585 MODULE_TEMP_01_03 "Module temperature01";
BA_ "FlexKomIsMotorola" SG_ 1585 MODULE_TEMP_01_03 1;
BA_ "GenSigSendType" SG_ 1585 NUM_TABLE_VALUE_03 0;
BA_ "GenSigCycleTime" SG_ 1585 NUM_TABLE_VALUE_03 40;
BA_ "FlexKomSigStartValue" SG_ 1585 NUM_TABLE_VALUE_03 "0Fh";
BA_ "GenSigStartValue" SG_ 1585 NUM_TABLE_VALUE_03 15;
BA_ "GenSigTimeout_BMU" SG_ 1585 NUM_TABLE_VALUE_03 220;
BA_ "FlexKomSID" SG_ 1585 NUM_TABLE_VALUE_03 1029;
BA_ "FlexKomSigStartPos" SG_ 1585 NUM_TABLE_VALUE_03 15;
BA_ "FlexKomSigLaenge" SG_ 1585 NUM_TABLE_VALUE_03 4;
BA_ "FlexKomSigName" SG_ 1585 NUM_TABLE_VALUE_03 "NUM_TABLE_VALUE_03";
BA_ "FlexKomComment" SG_ 1585 NUM_TABLE_VALUE_03 "Stored Automatic numbering table";
BA_ "FlexKomIsMotorola" SG_ 1585 NUM_TABLE_VALUE_03 1;
BA_ "GenSigSendType" SG_ 1585 BLC_DRV_STAT_12_03 0;
BA_ "GenSigCycleTime" SG_ 1585 BLC_DRV_STAT_12_03 40;
BA_ "FlexKomSigStartValue" SG_ 1585 BLC_DRV_STAT_12_03 "0000h";
BA_ "GenSigTimeout_BMU" SG_ 1585 BLC_DRV_STAT_12_03 220;
BA_ "FlexKomSID" SG_ 1585 BLC_DRV_STAT_12_03 728;
BA_ "FlexKomSigStartPos" SG_ 1585 BLC_DRV_STAT_12_03 7;
BA_ "FlexKomSigLaenge" SG_ 1585 BLC_DRV_STAT_12_03 16;
BA_ "FlexKomSigName" SG_ 1585 BLC_DRV_STAT_12_03 "BLC_DRV_STAT_03";
BA_ "FlexKomComment" SG_ 1585 BLC_DRV_STAT_12_03 "Balancer drive status packet";
BA_ "FlexKomIsMotorola" SG_ 1585 BLC_DRV_STAT_12_03 1;
BA_ "GenSigSendType" SG_ 1585 BLC_DRV_STAT_11_03 0;
BA_ "GenSigCycleTime" SG_ 1585 BLC_DRV_STAT_11_03 40;
BA_ "FlexKomSigStartValue" SG_ 1585 BLC_DRV_STAT_11_03 "0000h";
BA_ "GenSigTimeout_BMU" SG_ 1585 BLC_DRV_STAT_11_03 220;
BA_ "FlexKomSID" SG_ 1585 BLC_DRV_STAT_11_03 728;
BA_ "FlexKomSigStartPos" SG_ 1585 BLC_DRV_STAT_11_03 7;
BA_ "FlexKomSigLaenge" SG_ 1585 BLC_DRV_STAT_11_03 16;
BA_ "FlexKomSigName" SG_ 1585 BLC_DRV_STAT_11_03 "BLC_DRV_STAT_03";
BA_ "FlexKomComment" SG_ 1585 BLC_DRV_STAT_11_03 "Balancer drive status packet";
BA_ "FlexKomIsMotorola" SG_ 1585 BLC_DRV_STAT_11_03 1;
BA_ "GenSigSendType" SG_ 1585 BLC_DRV_STAT_10_03 0;
BA_ "GenSigCycleTime" SG_ 1585 BLC_DRV_STAT_10_03 40;
BA_ "FlexKomSigStartValue" SG_ 1585 BLC_DRV_STAT_10_03 "0000h";
BA_ "GenSigTimeout_BMU" SG_ 1585 BLC_DRV_STAT_10_03 220;
BA_ "FlexKomSID" SG_ 1585 BLC_DRV_STAT_10_03 728;
BA_ "FlexKomSigStartPos" SG_ 1585 BLC_DRV_STAT_10_03 7;
BA_ "FlexKomSigLaenge" SG_ 1585 BLC_DRV_STAT_10_03 16;
BA_ "FlexKomSigName" SG_ 1585 BLC_DRV_STAT_10_03 "BLC_DRV_STAT_03";
BA_ "FlexKomComment" SG_ 1585 BLC_DRV_STAT_10_03 "Balancer drive status packet";
BA_ "FlexKomIsMotorola" SG_ 1585 BLC_DRV_STAT_10_03 1;
BA_ "GenSigSendType" SG_ 1585 BLC_DRV_STAT_09_03 0;
BA_ "GenSigCycleTime" SG_ 1585 BLC_DRV_STAT_09_03 40;
BA_ "FlexKomSigStartValue" SG_ 1585 BLC_DRV_STAT_09_03 "0000h";
BA_ "GenSigTimeout_BMU" SG_ 1585 BLC_DRV_STAT_09_03 220;
BA_ "FlexKomSID" SG_ 1585 BLC_DRV_STAT_09_03 728;
BA_ "FlexKomSigStartPos" SG_ 1585 BLC_DRV_STAT_09_03 7;
BA_ "FlexKomSigLaenge" SG_ 1585 BLC_DRV_STAT_09_03 16;
BA_ "FlexKomSigName" SG_ 1585 BLC_DRV_STAT_09_03 "BLC_DRV_STAT_03";
BA_ "FlexKomComment" SG_ 1585 BLC_DRV_STAT_09_03 "Balancer drive status packet";
BA_ "FlexKomIsMotorola" SG_ 1585 BLC_DRV_STAT_09_03 1;
BA_ "GenSigSendType" SG_ 1585 BLC_DRV_STAT_08_03 0;
BA_ "GenSigCycleTime" SG_ 1585 BLC_DRV_STAT_08_03 40;
BA_ "FlexKomSigStartValue" SG_ 1585 BLC_DRV_STAT_08_03 "0000h";
BA_ "GenSigTimeout_BMU" SG_ 1585 BLC_DRV_STAT_08_03 220;
BA_ "FlexKomSID" SG_ 1585 BLC_DRV_STAT_08_03 728;
BA_ "FlexKomSigStartPos" SG_ 1585 BLC_DRV_STAT_08_03 7;
BA_ "FlexKomSigLaenge" SG_ 1585 BLC_DRV_STAT_08_03 16;
BA_ "FlexKomSigName" SG_ 1585 BLC_DRV_STAT_08_03 "BLC_DRV_STAT_03";
BA_ "FlexKomComment" SG_ 1585 BLC_DRV_STAT_08_03 "Balancer drive status packet";
BA_ "FlexKomIsMotorola" SG_ 1585 BLC_DRV_STAT_08_03 1;
BA_ "GenSigSendType" SG_ 1585 BLC_DRV_STAT_07_03 0;
BA_ "GenSigCycleTime" SG_ 1585 BLC_DRV_STAT_07_03 40;
BA_ "FlexKomSigStartValue" SG_ 1585 BLC_DRV_STAT_07_03 "0000h";
BA_ "GenSigTimeout_BMU" SG_ 1585 BLC_DRV_STAT_07_03 220;
BA_ "FlexKomSID" SG_ 1585 BLC_DRV_STAT_07_03 728;
BA_ "FlexKomSigStartPos" SG_ 1585 BLC_DRV_STAT_07_03 7;
BA_ "FlexKomSigLaenge" SG_ 1585 BLC_DRV_STAT_07_03 16;
BA_ "FlexKomSigName" SG_ 1585 BLC_DRV_STAT_07_03 "BLC_DRV_STAT_03";
BA_ "FlexKomComment" SG_ 1585 BLC_DRV_STAT_07_03 "Balancer drive status packet";
BA_ "FlexKomIsMotorola" SG_ 1585 BLC_DRV_STAT_07_03 1;
BA_ "GenSigSendType" SG_ 1585 BLC_DRV_STAT_06_03 0;
BA_ "GenSigCycleTime" SG_ 1585 BLC_DRV_STAT_06_03 40;
BA_ "FlexKomSigStartValue" SG_ 1585 BLC_DRV_STAT_06_03 "0000h";
BA_ "GenSigTimeout_BMU" SG_ 1585 BLC_DRV_STAT_06_03 220;
BA_ "FlexKomSID" SG_ 1585 BLC_DRV_STAT_06_03 728;
BA_ "FlexKomSigStartPos" SG_ 1585 BLC_DRV_STAT_06_03 7;
BA_ "FlexKomSigLaenge" SG_ 1585 BLC_DRV_STAT_06_03 16;
BA_ "FlexKomSigName" SG_ 1585 BLC_DRV_STAT_06_03 "BLC_DRV_STAT_03";
BA_ "FlexKomComment" SG_ 1585 BLC_DRV_STAT_06_03 "Balancer drive status packet";
BA_ "FlexKomIsMotorola" SG_ 1585 BLC_DRV_STAT_06_03 1;
BA_ "GenSigSendType" SG_ 1585 BLC_DRV_STAT_05_03 0;
BA_ "GenSigCycleTime" SG_ 1585 BLC_DRV_STAT_05_03 40;
BA_ "FlexKomSigStartValue" SG_ 1585 BLC_DRV_STAT_05_03 "0000h";
BA_ "GenSigTimeout_BMU" SG_ 1585 BLC_DRV_STAT_05_03 220;
BA_ "FlexKomSID" SG_ 1585 BLC_DRV_STAT_05_03 728;
BA_ "FlexKomSigStartPos" SG_ 1585 BLC_DRV_STAT_05_03 7;
BA_ "FlexKomSigLaenge" SG_ 1585 BLC_DRV_STAT_05_03 16;
BA_ "FlexKomSigName" SG_ 1585 BLC_DRV_STAT_05_03 "BLC_DRV_STAT_03";
BA_ "FlexKomComment" SG_ 1585 BLC_DRV_STAT_05_03 "Balancer drive status packet";
BA_ "FlexKomIsMotorola" SG_ 1585 BLC_DRV_STAT_05_03 1;
BA_ "GenSigSendType" SG_ 1585 BLC_DRV_STAT_04_03 0;
BA_ "GenSigCycleTime" SG_ 1585 BLC_DRV_STAT_04_03 40;
BA_ "FlexKomSigStartValue" SG_ 1585 BLC_DRV_STAT_04_03 "0000h";
BA_ "GenSigTimeout_BMU" SG_ 1585 BLC_DRV_STAT_04_03 220;
BA_ "FlexKomSID" SG_ 1585 BLC_DRV_STAT_04_03 728;
BA_ "FlexKomSigStartPos" SG_ 1585 BLC_DRV_STAT_04_03 7;
BA_ "FlexKomSigLaenge" SG_ 1585 BLC_DRV_STAT_04_03 16;
BA_ "FlexKomSigName" SG_ 1585 BLC_DRV_STAT_04_03 "BLC_DRV_STAT_03";
BA_ "FlexKomComment" SG_ 1585 BLC_DRV_STAT_04_03 "Balancer drive status packet";
BA_ "FlexKomIsMotorola" SG_ 1585 BLC_DRV_STAT_04_03 1;
BA_ "GenSigSendType" SG_ 1585 BLC_DRV_STAT_03_03 0;
BA_ "GenSigCycleTime" SG_ 1585 BLC_DRV_STAT_03_03 40;
BA_ "FlexKomSigStartValue" SG_ 1585 BLC_DRV_STAT_03_03 "0000h";
BA_ "GenSigTimeout_BMU" SG_ 1585 BLC_DRV_STAT_03_03 220;
BA_ "FlexKomSID" SG_ 1585 BLC_DRV_STAT_03_03 728;
BA_ "FlexKomSigStartPos" SG_ 1585 BLC_DRV_STAT_03_03 7;
BA_ "FlexKomSigLaenge" SG_ 1585 BLC_DRV_STAT_03_03 16;
BA_ "FlexKomSigName" SG_ 1585 BLC_DRV_STAT_03_03 "BLC_DRV_STAT_03";
BA_ "FlexKomComment" SG_ 1585 BLC_DRV_STAT_03_03 "Balancer drive status packet";
BA_ "FlexKomIsMotorola" SG_ 1585 BLC_DRV_STAT_03_03 1;
BA_ "GenSigSendType" SG_ 1585 BLC_DRV_STAT_02_03 0;
BA_ "GenSigCycleTime" SG_ 1585 BLC_DRV_STAT_02_03 40;
BA_ "FlexKomSigStartValue" SG_ 1585 BLC_DRV_STAT_02_03 "0000h";
BA_ "GenSigTimeout_BMU" SG_ 1585 BLC_DRV_STAT_02_03 220;
BA_ "FlexKomSID" SG_ 1585 BLC_DRV_STAT_02_03 728;
BA_ "FlexKomSigStartPos" SG_ 1585 BLC_DRV_STAT_02_03 7;
BA_ "FlexKomSigLaenge" SG_ 1585 BLC_DRV_STAT_02_03 16;
BA_ "FlexKomSigName" SG_ 1585 BLC_DRV_STAT_02_03 "BLC_DRV_STAT_03";
BA_ "FlexKomComment" SG_ 1585 BLC_DRV_STAT_02_03 "Balancer drive status packet";
BA_ "FlexKomIsMotorola" SG_ 1585 BLC_DRV_STAT_02_03 1;
BA_ "GenSigSendType" SG_ 1585 BLC_DRV_STAT_01_03 0;
BA_ "GenSigCycleTime" SG_ 1585 BLC_DRV_STAT_01_03 40;
BA_ "FlexKomSigStartValue" SG_ 1585 BLC_DRV_STAT_01_03 "0000h";
BA_ "GenSigTimeout_BMU" SG_ 1585 BLC_DRV_STAT_01_03 220;
BA_ "FlexKomSID" SG_ 1585 BLC_DRV_STAT_01_03 728;
BA_ "FlexKomSigStartPos" SG_ 1585 BLC_DRV_STAT_01_03 7;
BA_ "FlexKomSigLaenge" SG_ 1585 BLC_DRV_STAT_01_03 16;
BA_ "FlexKomSigName" SG_ 1585 BLC_DRV_STAT_01_03 "BLC_DRV_STAT_03";
BA_ "FlexKomComment" SG_ 1585 BLC_DRV_STAT_01_03 "Balancer drive status packet";
BA_ "FlexKomIsMotorola" SG_ 1585 BLC_DRV_STAT_01_03 1;
BA_ "GenSigSendType" SG_ 1569 MODULE_TEMP_06_02 0;
BA_ "GenSigCycleTime" SG_ 1569 MODULE_TEMP_06_02 40;
BA_ "FlexKomSigStartValue" SG_ 1569 MODULE_TEMP_06_02 "00h";
BA_ "GenSigTimeout_BMU" SG_ 1569 MODULE_TEMP_06_02 220;
BA_ "FlexKomSID" SG_ 1569 MODULE_TEMP_06_02 1100;
BA_ "FlexKomSigStartPos" SG_ 1569 MODULE_TEMP_06_02 63;
BA_ "FlexKomSigLaenge" SG_ 1569 MODULE_TEMP_06_02 8;
BA_ "FlexKomSigName" SG_ 1569 MODULE_TEMP_06_02 "MODULE_TEMP_06_02";
BA_ "FlexKomComment" SG_ 1569 MODULE_TEMP_06_02 "Module temperature06";
BA_ "FlexKomIsMotorola" SG_ 1569 MODULE_TEMP_06_02 1;
BA_ "GenSigSendType" SG_ 1569 MODULE_TEMP_05_02 0;
BA_ "GenSigCycleTime" SG_ 1569 MODULE_TEMP_05_02 40;
BA_ "FlexKomSigStartValue" SG_ 1569 MODULE_TEMP_05_02 "00h";
BA_ "GenSigTimeout_BMU" SG_ 1569 MODULE_TEMP_05_02 220;
BA_ "FlexKomSID" SG_ 1569 MODULE_TEMP_05_02 1088;
BA_ "FlexKomSigStartPos" SG_ 1569 MODULE_TEMP_05_02 55;
BA_ "FlexKomSigLaenge" SG_ 1569 MODULE_TEMP_05_02 8;
BA_ "FlexKomSigName" SG_ 1569 MODULE_TEMP_05_02 "MODULE_TEMP_05_02";
BA_ "FlexKomComment" SG_ 1569 MODULE_TEMP_05_02 "Module temperature05";
BA_ "FlexKomIsMotorola" SG_ 1569 MODULE_TEMP_05_02 1;
BA_ "GenSigSendType" SG_ 1569 MODULE_TEMP_04_02 0;
BA_ "GenSigCycleTime" SG_ 1569 MODULE_TEMP_04_02 40;
BA_ "FlexKomSigStartValue" SG_ 1569 MODULE_TEMP_04_02 "00h";
BA_ "GenSigTimeout_BMU" SG_ 1569 MODULE_TEMP_04_02 220;
BA_ "FlexKomSID" SG_ 1569 MODULE_TEMP_04_02 1076;
BA_ "FlexKomSigStartPos" SG_ 1569 MODULE_TEMP_04_02 47;
BA_ "FlexKomSigLaenge" SG_ 1569 MODULE_TEMP_04_02 8;
BA_ "FlexKomSigName" SG_ 1569 MODULE_TEMP_04_02 "MODULE_TEMP_04_02";
BA_ "FlexKomComment" SG_ 1569 MODULE_TEMP_04_02 "Module temperature04";
BA_ "FlexKomIsMotorola" SG_ 1569 MODULE_TEMP_04_02 1;
BA_ "GenSigSendType" SG_ 1569 MODULE_TEMP_03_02 0;
BA_ "GenSigCycleTime" SG_ 1569 MODULE_TEMP_03_02 40;
BA_ "FlexKomSigStartValue" SG_ 1569 MODULE_TEMP_03_02 "00h";
BA_ "GenSigTimeout_BMU" SG_ 1569 MODULE_TEMP_03_02 220;
BA_ "FlexKomSID" SG_ 1569 MODULE_TEMP_03_02 1064;
BA_ "FlexKomSigStartPos" SG_ 1569 MODULE_TEMP_03_02 39;
BA_ "FlexKomSigLaenge" SG_ 1569 MODULE_TEMP_03_02 8;
BA_ "FlexKomSigName" SG_ 1569 MODULE_TEMP_03_02 "MODULE_TEMP_03_02";
BA_ "FlexKomComment" SG_ 1569 MODULE_TEMP_03_02 "Module temperature03";
BA_ "FlexKomIsMotorola" SG_ 1569 MODULE_TEMP_03_02 1;
BA_ "GenSigSendType" SG_ 1569 MODULE_TEMP_02_02 0;
BA_ "GenSigCycleTime" SG_ 1569 MODULE_TEMP_02_02 40;
BA_ "FlexKomSigStartValue" SG_ 1569 MODULE_TEMP_02_02 "00h";
BA_ "GenSigTimeout_BMU" SG_ 1569 MODULE_TEMP_02_02 220;
BA_ "FlexKomSID" SG_ 1569 MODULE_TEMP_02_02 1052;
BA_ "FlexKomSigStartPos" SG_ 1569 MODULE_TEMP_02_02 31;
BA_ "FlexKomSigLaenge" SG_ 1569 MODULE_TEMP_02_02 8;
BA_ "FlexKomSigName" SG_ 1569 MODULE_TEMP_02_02 "MODULE_TEMP_02_02";
BA_ "FlexKomComment" SG_ 1569 MODULE_TEMP_02_02 "Module temperature02";
BA_ "FlexKomIsMotorola" SG_ 1569 MODULE_TEMP_02_02 1;
BA_ "GenSigSendType" SG_ 1569 MODULE_TEMP_01_02 0;
BA_ "GenSigCycleTime" SG_ 1569 MODULE_TEMP_01_02 40;
BA_ "FlexKomSigStartValue" SG_ 1569 MODULE_TEMP_01_02 "00h";
BA_ "GenSigTimeout_BMU" SG_ 1569 MODULE_TEMP_01_02 220;
BA_ "FlexKomSID" SG_ 1569 MODULE_TEMP_01_02 1040;
BA_ "FlexKomSigStartPos" SG_ 1569 MODULE_TEMP_01_02 23;
BA_ "FlexKomSigLaenge" SG_ 1569 MODULE_TEMP_01_02 8;
BA_ "FlexKomSigName" SG_ 1569 MODULE_TEMP_01_02 "MODULE_TEMP_01_02";
BA_ "FlexKomComment" SG_ 1569 MODULE_TEMP_01_02 "Module temperature01";
BA_ "FlexKomIsMotorola" SG_ 1569 MODULE_TEMP_01_02 1;
BA_ "GenSigSendType" SG_ 1569 NUM_TABLE_VALUE_02 0;
BA_ "GenSigCycleTime" SG_ 1569 NUM_TABLE_VALUE_02 40;
BA_ "FlexKomSigStartValue" SG_ 1569 NUM_TABLE_VALUE_02 "0Fh";
BA_ "GenSigStartValue" SG_ 1569 NUM_TABLE_VALUE_02 15;
BA_ "GenSigTimeout_BMU" SG_ 1569 NUM_TABLE_VALUE_02 220;
BA_ "FlexKomSID" SG_ 1569 NUM_TABLE_VALUE_02 1028;
BA_ "FlexKomSigStartPos" SG_ 1569 NUM_TABLE_VALUE_02 15;
BA_ "FlexKomSigLaenge" SG_ 1569 NUM_TABLE_VALUE_02 4;
BA_ "FlexKomSigName" SG_ 1569 NUM_TABLE_VALUE_02 "NUM_TABLE_VALUE_02";
BA_ "FlexKomComment" SG_ 1569 NUM_TABLE_VALUE_02 "Stored Automatic numbering table";
BA_ "FlexKomIsMotorola" SG_ 1569 NUM_TABLE_VALUE_02 1;
BA_ "GenSigSendType" SG_ 1569 BLC_DRV_STAT_12_02 0;
BA_ "GenSigCycleTime" SG_ 1569 BLC_DRV_STAT_12_02 40;
BA_ "FlexKomSigStartValue" SG_ 1569 BLC_DRV_STAT_12_02 "0000h";
BA_ "GenSigTimeout_BMU" SG_ 1569 BLC_DRV_STAT_12_02 220;
BA_ "FlexKomSID" SG_ 1569 BLC_DRV_STAT_12_02 712;
BA_ "FlexKomSigStartPos" SG_ 1569 BLC_DRV_STAT_12_02 7;
BA_ "FlexKomSigLaenge" SG_ 1569 BLC_DRV_STAT_12_02 16;
BA_ "FlexKomSigName" SG_ 1569 BLC_DRV_STAT_12_02 "BLC_DRV_STAT_02";
BA_ "FlexKomComment" SG_ 1569 BLC_DRV_STAT_12_02 "Balancer drive status packet";
BA_ "FlexKomIsMotorola" SG_ 1569 BLC_DRV_STAT_12_02 1;
BA_ "GenSigSendType" SG_ 1569 BLC_DRV_STAT_11_02 0;
BA_ "GenSigCycleTime" SG_ 1569 BLC_DRV_STAT_11_02 40;
BA_ "FlexKomSigStartValue" SG_ 1569 BLC_DRV_STAT_11_02 "0000h";
BA_ "GenSigTimeout_BMU" SG_ 1569 BLC_DRV_STAT_11_02 220;
BA_ "FlexKomSID" SG_ 1569 BLC_DRV_STAT_11_02 712;
BA_ "FlexKomSigStartPos" SG_ 1569 BLC_DRV_STAT_11_02 7;
BA_ "FlexKomSigLaenge" SG_ 1569 BLC_DRV_STAT_11_02 16;
BA_ "FlexKomSigName" SG_ 1569 BLC_DRV_STAT_11_02 "BLC_DRV_STAT_02";
BA_ "FlexKomComment" SG_ 1569 BLC_DRV_STAT_11_02 "Balancer drive status packet";
BA_ "FlexKomIsMotorola" SG_ 1569 BLC_DRV_STAT_11_02 1;
BA_ "GenSigSendType" SG_ 1569 BLC_DRV_STAT_10_02 0;
BA_ "GenSigCycleTime" SG_ 1569 BLC_DRV_STAT_10_02 40;
BA_ "FlexKomSigStartValue" SG_ 1569 BLC_DRV_STAT_10_02 "0000h";
BA_ "GenSigTimeout_BMU" SG_ 1569 BLC_DRV_STAT_10_02 220;
BA_ "FlexKomSID" SG_ 1569 BLC_DRV_STAT_10_02 712;
BA_ "FlexKomSigStartPos" SG_ 1569 BLC_DRV_STAT_10_02 7;
BA_ "FlexKomSigLaenge" SG_ 1569 BLC_DRV_STAT_10_02 16;
BA_ "FlexKomSigName" SG_ 1569 BLC_DRV_STAT_10_02 "BLC_DRV_STAT_02";
BA_ "FlexKomComment" SG_ 1569 BLC_DRV_STAT_10_02 "Balancer drive status packet";
BA_ "FlexKomIsMotorola" SG_ 1569 BLC_DRV_STAT_10_02 1;
BA_ "GenSigSendType" SG_ 1569 BLC_DRV_STAT_09_02 0;
BA_ "GenSigCycleTime" SG_ 1569 BLC_DRV_STAT_09_02 40;
BA_ "FlexKomSigStartValue" SG_ 1569 BLC_DRV_STAT_09_02 "0000h";
BA_ "GenSigTimeout_BMU" SG_ 1569 BLC_DRV_STAT_09_02 220;
BA_ "FlexKomSID" SG_ 1569 BLC_DRV_STAT_09_02 712;
BA_ "FlexKomSigStartPos" SG_ 1569 BLC_DRV_STAT_09_02 7;
BA_ "FlexKomSigLaenge" SG_ 1569 BLC_DRV_STAT_09_02 16;
BA_ "FlexKomSigName" SG_ 1569 BLC_DRV_STAT_09_02 "BLC_DRV_STAT_02";
BA_ "FlexKomComment" SG_ 1569 BLC_DRV_STAT_09_02 "Balancer drive status packet";
BA_ "FlexKomIsMotorola" SG_ 1569 BLC_DRV_STAT_09_02 1;
BA_ "GenSigSendType" SG_ 1569 BLC_DRV_STAT_08_02 0;
BA_ "GenSigCycleTime" SG_ 1569 BLC_DRV_STAT_08_02 40;
BA_ "FlexKomSigStartValue" SG_ 1569 BLC_DRV_STAT_08_02 "0000h";
BA_ "GenSigTimeout_BMU" SG_ 1569 BLC_DRV_STAT_08_02 220;
BA_ "FlexKomSID" SG_ 1569 BLC_DRV_STAT_08_02 712;
BA_ "FlexKomSigStartPos" SG_ 1569 BLC_DRV_STAT_08_02 7;
BA_ "FlexKomSigLaenge" SG_ 1569 BLC_DRV_STAT_08_02 16;
BA_ "FlexKomSigName" SG_ 1569 BLC_DRV_STAT_08_02 "BLC_DRV_STAT_02";
BA_ "FlexKomComment" SG_ 1569 BLC_DRV_STAT_08_02 "Balancer drive status packet";
BA_ "FlexKomIsMotorola" SG_ 1569 BLC_DRV_STAT_08_02 1;
BA_ "GenSigSendType" SG_ 1569 BLC_DRV_STAT_07_02 0;
BA_ "GenSigCycleTime" SG_ 1569 BLC_DRV_STAT_07_02 40;
BA_ "FlexKomSigStartValue" SG_ 1569 BLC_DRV_STAT_07_02 "0000h";
BA_ "GenSigTimeout_BMU" SG_ 1569 BLC_DRV_STAT_07_02 220;
BA_ "FlexKomSID" SG_ 1569 BLC_DRV_STAT_07_02 712;
BA_ "FlexKomSigStartPos" SG_ 1569 BLC_DRV_STAT_07_02 7;
BA_ "FlexKomSigLaenge" SG_ 1569 BLC_DRV_STAT_07_02 16;
BA_ "FlexKomSigName" SG_ 1569 BLC_DRV_STAT_07_02 "BLC_DRV_STAT_02";
BA_ "FlexKomComment" SG_ 1569 BLC_DRV_STAT_07_02 "Balancer drive status packet";
BA_ "FlexKomIsMotorola" SG_ 1569 BLC_DRV_STAT_07_02 1;
BA_ "GenSigSendType" SG_ 1569 BLC_DRV_STAT_06_02 0;
BA_ "GenSigCycleTime" SG_ 1569 BLC_DRV_STAT_06_02 40;
BA_ "FlexKomSigStartValue" SG_ 1569 BLC_DRV_STAT_06_02 "0000h";
BA_ "GenSigTimeout_BMU" SG_ 1569 BLC_DRV_STAT_06_02 220;
BA_ "FlexKomSID" SG_ 1569 BLC_DRV_STAT_06_02 712;
BA_ "FlexKomSigStartPos" SG_ 1569 BLC_DRV_STAT_06_02 7;
BA_ "FlexKomSigLaenge" SG_ 1569 BLC_DRV_STAT_06_02 16;
BA_ "FlexKomSigName" SG_ 1569 BLC_DRV_STAT_06_02 "BLC_DRV_STAT_02";
BA_ "FlexKomComment" SG_ 1569 BLC_DRV_STAT_06_02 "Balancer drive status packet";
BA_ "FlexKomIsMotorola" SG_ 1569 BLC_DRV_STAT_06_02 1;
BA_ "GenSigSendType" SG_ 1569 BLC_DRV_STAT_05_02 0;
BA_ "GenSigCycleTime" SG_ 1569 BLC_DRV_STAT_05_02 40;
BA_ "FlexKomSigStartValue" SG_ 1569 BLC_DRV_STAT_05_02 "0000h";
BA_ "GenSigTimeout_BMU" SG_ 1569 BLC_DRV_STAT_05_02 220;
BA_ "FlexKomSID" SG_ 1569 BLC_DRV_STAT_05_02 712;
BA_ "FlexKomSigStartPos" SG_ 1569 BLC_DRV_STAT_05_02 7;
BA_ "FlexKomSigLaenge" SG_ 1569 BLC_DRV_STAT_05_02 16;
BA_ "FlexKomSigName" SG_ 1569 BLC_DRV_STAT_05_02 "BLC_DRV_STAT_02";
BA_ "FlexKomComment" SG_ 1569 BLC_DRV_STAT_05_02 "Balancer drive status packet";
BA_ "FlexKomIsMotorola" SG_ 1569 BLC_DRV_STAT_05_02 1;
BA_ "GenSigSendType" SG_ 1569 BLC_DRV_STAT_04_02 0;
BA_ "GenSigCycleTime" SG_ 1569 BLC_DRV_STAT_04_02 40;
BA_ "FlexKomSigStartValue" SG_ 1569 BLC_DRV_STAT_04_02 "0000h";
BA_ "GenSigTimeout_BMU" SG_ 1569 BLC_DRV_STAT_04_02 220;
BA_ "FlexKomSID" SG_ 1569 BLC_DRV_STAT_04_02 712;
BA_ "FlexKomSigStartPos" SG_ 1569 BLC_DRV_STAT_04_02 7;
BA_ "FlexKomSigLaenge" SG_ 1569 BLC_DRV_STAT_04_02 16;
BA_ "FlexKomSigName" SG_ 1569 BLC_DRV_STAT_04_02 "BLC_DRV_STAT_02";
BA_ "FlexKomComment" SG_ 1569 BLC_DRV_STAT_04_02 "Balancer drive status packet";
BA_ "FlexKomIsMotorola" SG_ 1569 BLC_DRV_STAT_04_02 1;
BA_ "GenSigSendType" SG_ 1569 BLC_DRV_STAT_03_02 0;
BA_ "GenSigCycleTime" SG_ 1569 BLC_DRV_STAT_03_02 40;
BA_ "FlexKomSigStartValue" SG_ 1569 BLC_DRV_STAT_03_02 "0000h";
BA_ "GenSigTimeout_BMU" SG_ 1569 BLC_DRV_STAT_03_02 220;
BA_ "FlexKomSID" SG_ 1569 BLC_DRV_STAT_03_02 712;
BA_ "FlexKomSigStartPos" SG_ 1569 BLC_DRV_STAT_03_02 7;
BA_ "FlexKomSigLaenge" SG_ 1569 BLC_DRV_STAT_03_02 16;
BA_ "FlexKomSigName" SG_ 1569 BLC_DRV_STAT_03_02 "BLC_DRV_STAT_02";
BA_ "FlexKomComment" SG_ 1569 BLC_DRV_STAT_03_02 "Balancer drive status packet";
BA_ "FlexKomIsMotorola" SG_ 1569 BLC_DRV_STAT_03_02 1;
BA_ "GenSigSendType" SG_ 1569 BLC_DRV_STAT_02_02 0;
BA_ "GenSigCycleTime" SG_ 1569 BLC_DRV_STAT_02_02 40;
BA_ "FlexKomSigStartValue" SG_ 1569 BLC_DRV_STAT_02_02 "0000h";
BA_ "GenSigTimeout_BMU" SG_ 1569 BLC_DRV_STAT_02_02 220;
BA_ "FlexKomSID" SG_ 1569 BLC_DRV_STAT_02_02 712;
BA_ "FlexKomSigStartPos" SG_ 1569 BLC_DRV_STAT_02_02 7;
BA_ "FlexKomSigLaenge" SG_ 1569 BLC_DRV_STAT_02_02 16;
BA_ "FlexKomSigName" SG_ 1569 BLC_DRV_STAT_02_02 "BLC_DRV_STAT_02";
BA_ "FlexKomComment" SG_ 1569 BLC_DRV_STAT_02_02 "Balancer drive status packet";
BA_ "FlexKomIsMotorola" SG_ 1569 BLC_DRV_STAT_02_02 1;
BA_ "GenSigSendType" SG_ 1569 BLC_DRV_STAT_01_02 0;
BA_ "GenSigCycleTime" SG_ 1569 BLC_DRV_STAT_01_02 40;
BA_ "FlexKomSigStartValue" SG_ 1569 BLC_DRV_STAT_01_02 "0000h";
BA_ "GenSigTimeout_BMU" SG_ 1569 BLC_DRV_STAT_01_02 220;
BA_ "FlexKomSID" SG_ 1569 BLC_DRV_STAT_01_02 712;
BA_ "FlexKomSigStartPos" SG_ 1569 BLC_DRV_STAT_01_02 7;
BA_ "FlexKomSigLaenge" SG_ 1569 BLC_DRV_STAT_01_02 16;
BA_ "FlexKomSigName" SG_ 1569 BLC_DRV_STAT_01_02 "BLC_DRV_STAT_02";
BA_ "FlexKomComment" SG_ 1569 BLC_DRV_STAT_01_02 "Balancer drive status packet";
BA_ "FlexKomIsMotorola" SG_ 1569 BLC_DRV_STAT_01_02 1;
BA_ "GenSigSendType" SG_ 1553 MODULE_TEMP_06_01 0;
BA_ "GenSigCycleTime" SG_ 1553 MODULE_TEMP_06_01 40;
BA_ "FlexKomSigStartValue" SG_ 1553 MODULE_TEMP_06_01 "00h";
BA_ "GenSigTimeout_BMU" SG_ 1553 MODULE_TEMP_06_01 220;
BA_ "FlexKomSID" SG_ 1553 MODULE_TEMP_06_01 1099;
BA_ "FlexKomSigStartPos" SG_ 1553 MODULE_TEMP_06_01 63;
BA_ "FlexKomSigLaenge" SG_ 1553 MODULE_TEMP_06_01 8;
BA_ "FlexKomSigName" SG_ 1553 MODULE_TEMP_06_01 "MODULE_TEMP_06_01";
BA_ "FlexKomComment" SG_ 1553 MODULE_TEMP_06_01 "Module temperature06";
BA_ "FlexKomIsMotorola" SG_ 1553 MODULE_TEMP_06_01 1;
BA_ "GenSigSendType" SG_ 1553 MODULE_TEMP_05_01 0;
BA_ "GenSigCycleTime" SG_ 1553 MODULE_TEMP_05_01 40;
BA_ "FlexKomSigStartValue" SG_ 1553 MODULE_TEMP_05_01 "00h";
BA_ "GenSigTimeout_BMU" SG_ 1553 MODULE_TEMP_05_01 220;
BA_ "FlexKomSID" SG_ 1553 MODULE_TEMP_05_01 1087;
BA_ "FlexKomSigStartPos" SG_ 1553 MODULE_TEMP_05_01 55;
BA_ "FlexKomSigLaenge" SG_ 1553 MODULE_TEMP_05_01 8;
BA_ "FlexKomSigName" SG_ 1553 MODULE_TEMP_05_01 "MODULE_TEMP_05_01";
BA_ "FlexKomComment" SG_ 1553 MODULE_TEMP_05_01 "Module temperature05";
BA_ "FlexKomIsMotorola" SG_ 1553 MODULE_TEMP_05_01 1;
BA_ "GenSigSendType" SG_ 1553 MODULE_TEMP_04_01 0;
BA_ "GenSigCycleTime" SG_ 1553 MODULE_TEMP_04_01 40;
BA_ "FlexKomSigStartValue" SG_ 1553 MODULE_TEMP_04_01 "00h";
BA_ "GenSigTimeout_BMU" SG_ 1553 MODULE_TEMP_04_01 220;
BA_ "FlexKomSID" SG_ 1553 MODULE_TEMP_04_01 1075;
BA_ "FlexKomSigStartPos" SG_ 1553 MODULE_TEMP_04_01 47;
BA_ "FlexKomSigLaenge" SG_ 1553 MODULE_TEMP_04_01 8;
BA_ "FlexKomSigName" SG_ 1553 MODULE_TEMP_04_01 "MODULE_TEMP_04_01";
BA_ "FlexKomComment" SG_ 1553 MODULE_TEMP_04_01 "Module temperature04";
BA_ "FlexKomIsMotorola" SG_ 1553 MODULE_TEMP_04_01 1;
BA_ "GenSigSendType" SG_ 1553 MODULE_TEMP_03_01 0;
BA_ "GenSigCycleTime" SG_ 1553 MODULE_TEMP_03_01 40;
BA_ "FlexKomSigStartValue" SG_ 1553 MODULE_TEMP_03_01 "00h";
BA_ "GenSigTimeout_BMU" SG_ 1553 MODULE_TEMP_03_01 220;
BA_ "FlexKomSID" SG_ 1553 MODULE_TEMP_03_01 1063;
BA_ "FlexKomSigStartPos" SG_ 1553 MODULE_TEMP_03_01 39;
BA_ "FlexKomSigLaenge" SG_ 1553 MODULE_TEMP_03_01 8;
BA_ "FlexKomSigName" SG_ 1553 MODULE_TEMP_03_01 "MODULE_TEMP_03_01";
BA_ "FlexKomComment" SG_ 1553 MODULE_TEMP_03_01 "Module temperature03";
BA_ "FlexKomIsMotorola" SG_ 1553 MODULE_TEMP_03_01 1;
BA_ "GenSigSendType" SG_ 1553 MODULE_TEMP_02_01 0;
BA_ "GenSigCycleTime" SG_ 1553 MODULE_TEMP_02_01 40;
BA_ "FlexKomSigStartValue" SG_ 1553 MODULE_TEMP_02_01 "00h";
BA_ "GenSigTimeout_BMU" SG_ 1553 MODULE_TEMP_02_01 220;
BA_ "FlexKomSID" SG_ 1553 MODULE_TEMP_02_01 1051;
BA_ "FlexKomSigStartPos" SG_ 1553 MODULE_TEMP_02_01 31;
BA_ "FlexKomSigLaenge" SG_ 1553 MODULE_TEMP_02_01 8;
BA_ "FlexKomSigName" SG_ 1553 MODULE_TEMP_02_01 "MODULE_TEMP_02_01";
BA_ "FlexKomComment" SG_ 1553 MODULE_TEMP_02_01 "Module temperature02";
BA_ "FlexKomIsMotorola" SG_ 1553 MODULE_TEMP_02_01 1;
BA_ "GenSigSendType" SG_ 1553 MODULE_TEMP_01_01 0;
BA_ "GenSigCycleTime" SG_ 1553 MODULE_TEMP_01_01 40;
BA_ "FlexKomSigStartValue" SG_ 1553 MODULE_TEMP_01_01 "00h";
BA_ "GenSigTimeout_BMU" SG_ 1553 MODULE_TEMP_01_01 220;
BA_ "FlexKomSID" SG_ 1553 MODULE_TEMP_01_01 1039;
BA_ "FlexKomSigStartPos" SG_ 1553 MODULE_TEMP_01_01 23;
BA_ "FlexKomSigLaenge" SG_ 1553 MODULE_TEMP_01_01 8;
BA_ "FlexKomSigName" SG_ 1553 MODULE_TEMP_01_01 "MODULE_TEMP_01_01";
BA_ "FlexKomComment" SG_ 1553 MODULE_TEMP_01_01 "Module temperature01";
BA_ "FlexKomIsMotorola" SG_ 1553 MODULE_TEMP_01_01 1;
BA_ "GenSigSendType" SG_ 1553 NUM_TABLE_VALUE_01 0;
BA_ "GenSigCycleTime" SG_ 1553 NUM_TABLE_VALUE_01 40;
BA_ "FlexKomSigStartValue" SG_ 1553 NUM_TABLE_VALUE_01 "0Fh";
BA_ "GenSigStartValue" SG_ 1553 NUM_TABLE_VALUE_01 15;
BA_ "GenSigTimeout_BMU" SG_ 1553 NUM_TABLE_VALUE_01 220;
BA_ "FlexKomSID" SG_ 1553 NUM_TABLE_VALUE_01 1016;
BA_ "FlexKomSigStartPos" SG_ 1553 NUM_TABLE_VALUE_01 15;
BA_ "FlexKomSigLaenge" SG_ 1553 NUM_TABLE_VALUE_01 4;
BA_ "FlexKomSigName" SG_ 1553 NUM_TABLE_VALUE_01 "NUM_TABLE_VALUE_01";
BA_ "FlexKomComment" SG_ 1553 NUM_TABLE_VALUE_01 "Stored Automatic numbering table";
BA_ "FlexKomIsMotorola" SG_ 1553 NUM_TABLE_VALUE_01 1;
BA_ "GenSigSendType" SG_ 1553 BLC_DRV_STAT_12_01 0;
BA_ "GenSigCycleTime" SG_ 1553 BLC_DRV_STAT_12_01 40;
BA_ "FlexKomSigStartValue" SG_ 1553 BLC_DRV_STAT_12_01 "0000h";
BA_ "GenSigTimeout_BMU" SG_ 1553 BLC_DRV_STAT_12_01 220;
BA_ "FlexKomSID" SG_ 1553 BLC_DRV_STAT_12_01 637;
BA_ "FlexKomSigStartPos" SG_ 1553 BLC_DRV_STAT_12_01 7;
BA_ "FlexKomSigLaenge" SG_ 1553 BLC_DRV_STAT_12_01 16;
BA_ "FlexKomSigName" SG_ 1553 BLC_DRV_STAT_12_01 "BLC_DRV_STAT_01";
BA_ "FlexKomComment" SG_ 1553 BLC_DRV_STAT_12_01 "Balancer drive status packet";
BA_ "FlexKomIsMotorola" SG_ 1553 BLC_DRV_STAT_12_01 1;
BA_ "GenSigSendType" SG_ 1553 BLC_DRV_STAT_11_01 0;
BA_ "GenSigCycleTime" SG_ 1553 BLC_DRV_STAT_11_01 40;
BA_ "FlexKomSigStartValue" SG_ 1553 BLC_DRV_STAT_11_01 "0000h";
BA_ "GenSigTimeout_BMU" SG_ 1553 BLC_DRV_STAT_11_01 220;
BA_ "FlexKomSID" SG_ 1553 BLC_DRV_STAT_11_01 637;
BA_ "FlexKomSigStartPos" SG_ 1553 BLC_DRV_STAT_11_01 7;
BA_ "FlexKomSigLaenge" SG_ 1553 BLC_DRV_STAT_11_01 16;
BA_ "FlexKomSigName" SG_ 1553 BLC_DRV_STAT_11_01 "BLC_DRV_STAT_01";
BA_ "FlexKomComment" SG_ 1553 BLC_DRV_STAT_11_01 "Balancer drive status packet";
BA_ "FlexKomIsMotorola" SG_ 1553 BLC_DRV_STAT_11_01 1;
BA_ "GenSigSendType" SG_ 1553 BLC_DRV_STAT_10_01 0;
BA_ "GenSigCycleTime" SG_ 1553 BLC_DRV_STAT_10_01 40;
BA_ "FlexKomSigStartValue" SG_ 1553 BLC_DRV_STAT_10_01 "0000h";
BA_ "GenSigTimeout_BMU" SG_ 1553 BLC_DRV_STAT_10_01 220;
BA_ "FlexKomSID" SG_ 1553 BLC_DRV_STAT_10_01 637;
BA_ "FlexKomSigStartPos" SG_ 1553 BLC_DRV_STAT_10_01 7;
BA_ "FlexKomSigLaenge" SG_ 1553 BLC_DRV_STAT_10_01 16;
BA_ "FlexKomSigName" SG_ 1553 BLC_DRV_STAT_10_01 "BLC_DRV_STAT_01";
BA_ "FlexKomComment" SG_ 1553 BLC_DRV_STAT_10_01 "Balancer drive status packet";
BA_ "FlexKomIsMotorola" SG_ 1553 BLC_DRV_STAT_10_01 1;
BA_ "GenSigSendType" SG_ 1553 BLC_DRV_STAT_09_01 0;
BA_ "GenSigCycleTime" SG_ 1553 BLC_DRV_STAT_09_01 40;
BA_ "FlexKomSigStartValue" SG_ 1553 BLC_DRV_STAT_09_01 "0000h";
BA_ "GenSigTimeout_BMU" SG_ 1553 BLC_DRV_STAT_09_01 220;
BA_ "FlexKomSID" SG_ 1553 BLC_DRV_STAT_09_01 637;
BA_ "FlexKomSigStartPos" SG_ 1553 BLC_DRV_STAT_09_01 7;
BA_ "FlexKomSigLaenge" SG_ 1553 BLC_DRV_STAT_09_01 16;
BA_ "FlexKomSigName" SG_ 1553 BLC_DRV_STAT_09_01 "BLC_DRV_STAT_01";
BA_ "FlexKomComment" SG_ 1553 BLC_DRV_STAT_09_01 "Balancer drive status packet";
BA_ "FlexKomIsMotorola" SG_ 1553 BLC_DRV_STAT_09_01 1;
BA_ "GenSigSendType" SG_ 1553 BLC_DRV_STAT_08_01 0;
BA_ "GenSigCycleTime" SG_ 1553 BLC_DRV_STAT_08_01 40;
BA_ "FlexKomSigStartValue" SG_ 1553 BLC_DRV_STAT_08_01 "0000h";
BA_ "GenSigTimeout_BMU" SG_ 1553 BLC_DRV_STAT_08_01 220;
BA_ "FlexKomSID" SG_ 1553 BLC_DRV_STAT_08_01 637;
BA_ "FlexKomSigStartPos" SG_ 1553 BLC_DRV_STAT_08_01 7;
BA_ "FlexKomSigLaenge" SG_ 1553 BLC_DRV_STAT_08_01 16;
BA_ "FlexKomSigName" SG_ 1553 BLC_DRV_STAT_08_01 "BLC_DRV_STAT_01";
BA_ "FlexKomComment" SG_ 1553 BLC_DRV_STAT_08_01 "Balancer drive status packet";
BA_ "FlexKomIsMotorola" SG_ 1553 BLC_DRV_STAT_08_01 1;
BA_ "GenSigSendType" SG_ 1553 BLC_DRV_STAT_07_01 0;
BA_ "GenSigCycleTime" SG_ 1553 BLC_DRV_STAT_07_01 40;
BA_ "FlexKomSigStartValue" SG_ 1553 BLC_DRV_STAT_07_01 "0000h";
BA_ "GenSigTimeout_BMU" SG_ 1553 BLC_DRV_STAT_07_01 220;
BA_ "FlexKomSID" SG_ 1553 BLC_DRV_STAT_07_01 637;
BA_ "FlexKomSigStartPos" SG_ 1553 BLC_DRV_STAT_07_01 7;
BA_ "FlexKomSigLaenge" SG_ 1553 BLC_DRV_STAT_07_01 16;
BA_ "FlexKomSigName" SG_ 1553 BLC_DRV_STAT_07_01 "BLC_DRV_STAT_01";
BA_ "FlexKomComment" SG_ 1553 BLC_DRV_STAT_07_01 "Balancer drive status packet";
BA_ "FlexKomIsMotorola" SG_ 1553 BLC_DRV_STAT_07_01 1;
BA_ "GenSigSendType" SG_ 1553 BLC_DRV_STAT_06_01 0;
BA_ "GenSigCycleTime" SG_ 1553 BLC_DRV_STAT_06_01 40;
BA_ "FlexKomSigStartValue" SG_ 1553 BLC_DRV_STAT_06_01 "0000h";
BA_ "GenSigTimeout_BMU" SG_ 1553 BLC_DRV_STAT_06_01 220;
BA_ "FlexKomSID" SG_ 1553 BLC_DRV_STAT_06_01 637;
BA_ "FlexKomSigStartPos" SG_ 1553 BLC_DRV_STAT_06_01 7;
BA_ "FlexKomSigLaenge" SG_ 1553 BLC_DRV_STAT_06_01 16;
BA_ "FlexKomSigName" SG_ 1553 BLC_DRV_STAT_06_01 "BLC_DRV_STAT_01";
BA_ "FlexKomComment" SG_ 1553 BLC_DRV_STAT_06_01 "Balancer drive status packet";
BA_ "FlexKomIsMotorola" SG_ 1553 BLC_DRV_STAT_06_01 1;
BA_ "GenSigSendType" SG_ 1553 BLC_DRV_STAT_05_01 0;
BA_ "GenSigCycleTime" SG_ 1553 BLC_DRV_STAT_05_01 40;
BA_ "FlexKomSigStartValue" SG_ 1553 BLC_DRV_STAT_05_01 "0000h";
BA_ "GenSigTimeout_BMU" SG_ 1553 BLC_DRV_STAT_05_01 220;
BA_ "FlexKomSID" SG_ 1553 BLC_DRV_STAT_05_01 637;
BA_ "FlexKomSigStartPos" SG_ 1553 BLC_DRV_STAT_05_01 7;
BA_ "FlexKomSigLaenge" SG_ 1553 BLC_DRV_STAT_05_01 16;
BA_ "FlexKomSigName" SG_ 1553 BLC_DRV_STAT_05_01 "BLC_DRV_STAT_01";
BA_ "FlexKomComment" SG_ 1553 BLC_DRV_STAT_05_01 "Balancer drive status packet";
BA_ "FlexKomIsMotorola" SG_ 1553 BLC_DRV_STAT_05_01 1;
BA_ "GenSigSendType" SG_ 1553 BLC_DRV_STAT_04_01 0;
BA_ "GenSigCycleTime" SG_ 1553 BLC_DRV_STAT_04_01 40;
BA_ "FlexKomSigStartValue" SG_ 1553 BLC_DRV_STAT_04_01 "0000h";
BA_ "GenSigTimeout_BMU" SG_ 1553 BLC_DRV_STAT_04_01 220;
BA_ "FlexKomSID" SG_ 1553 BLC_DRV_STAT_04_01 637;
BA_ "FlexKomSigStartPos" SG_ 1553 BLC_DRV_STAT_04_01 7;
BA_ "FlexKomSigLaenge" SG_ 1553 BLC_DRV_STAT_04_01 16;
BA_ "FlexKomSigName" SG_ 1553 BLC_DRV_STAT_04_01 "BLC_DRV_STAT_01";
BA_ "FlexKomComment" SG_ 1553 BLC_DRV_STAT_04_01 "Balancer drive status packet";
BA_ "FlexKomIsMotorola" SG_ 1553 BLC_DRV_STAT_04_01 1;
BA_ "GenSigSendType" SG_ 1553 BLC_DRV_STAT_03_01 0;
BA_ "GenSigCycleTime" SG_ 1553 BLC_DRV_STAT_03_01 40;
BA_ "FlexKomSigStartValue" SG_ 1553 BLC_DRV_STAT_03_01 "0000h";
BA_ "GenSigTimeout_BMU" SG_ 1553 BLC_DRV_STAT_03_01 220;
BA_ "FlexKomSID" SG_ 1553 BLC_DRV_STAT_03_01 637;
BA_ "FlexKomSigStartPos" SG_ 1553 BLC_DRV_STAT_03_01 7;
BA_ "FlexKomSigLaenge" SG_ 1553 BLC_DRV_STAT_03_01 16;
BA_ "FlexKomSigName" SG_ 1553 BLC_DRV_STAT_03_01 "BLC_DRV_STAT_01";
BA_ "FlexKomComment" SG_ 1553 BLC_DRV_STAT_03_01 "Balancer drive status packet";
BA_ "FlexKomIsMotorola" SG_ 1553 BLC_DRV_STAT_03_01 1;
BA_ "GenSigSendType" SG_ 1553 BLC_DRV_STAT_02_01 0;
BA_ "GenSigCycleTime" SG_ 1553 BLC_DRV_STAT_02_01 40;
BA_ "FlexKomSigStartValue" SG_ 1553 BLC_DRV_STAT_02_01 "0000h";
BA_ "GenSigTimeout_BMU" SG_ 1553 BLC_DRV_STAT_02_01 220;
BA_ "FlexKomSID" SG_ 1553 BLC_DRV_STAT_02_01 637;
BA_ "FlexKomSigStartPos" SG_ 1553 BLC_DRV_STAT_02_01 7;
BA_ "FlexKomSigLaenge" SG_ 1553 BLC_DRV_STAT_02_01 16;
BA_ "FlexKomSigName" SG_ 1553 BLC_DRV_STAT_02_01 "BLC_DRV_STAT_01";
BA_ "FlexKomComment" SG_ 1553 BLC_DRV_STAT_02_01 "Balancer drive status packet";
BA_ "FlexKomIsMotorola" SG_ 1553 BLC_DRV_STAT_02_01 1;
BA_ "GenSigSendType" SG_ 1553 BLC_DRV_STAT_01_01 0;
BA_ "GenSigCycleTime" SG_ 1553 BLC_DRV_STAT_01_01 40;
BA_ "FlexKomSigStartValue" SG_ 1553 BLC_DRV_STAT_01_01 "0000h";
BA_ "GenSigTimeout_BMU" SG_ 1553 BLC_DRV_STAT_01_01 220;
BA_ "FlexKomSID" SG_ 1553 BLC_DRV_STAT_01_01 637;
BA_ "FlexKomSigStartPos" SG_ 1553 BLC_DRV_STAT_01_01 7;
BA_ "FlexKomSigLaenge" SG_ 1553 BLC_DRV_STAT_01_01 16;
BA_ "FlexKomSigName" SG_ 1553 BLC_DRV_STAT_01_01 "BLC_DRV_STAT_01";
BA_ "FlexKomComment" SG_ 1553 BLC_DRV_STAT_01_01 "Balancer drive status packet";
BA_ "FlexKomIsMotorola" SG_ 1553 BLC_DRV_STAT_01_01 1;
BA_ "GenSigSendType" SG_ 963 NUM_TABLE 0;
BA_ "GenSigCycleTime" SG_ 963 NUM_TABLE 40;
BA_ "FlexKomSigStartValue" SG_ 963 NUM_TABLE "0Fh";
BA_ "GenSigStartValue" SG_ 963 NUM_TABLE 15;
BA_ "GenSigTimeout_CMU_01" SG_ 963 NUM_TABLE 220;
BA_ "GenSigTimeout_CMU_02" SG_ 963 NUM_TABLE 220;
BA_ "GenSigTimeout_CMU_03" SG_ 963 NUM_TABLE 220;
BA_ "GenSigTimeout_CMU_04" SG_ 963 NUM_TABLE 220;
BA_ "GenSigTimeout_CMU_05" SG_ 963 NUM_TABLE 220;
BA_ "GenSigTimeout_CMU_06" SG_ 963 NUM_TABLE 220;
BA_ "GenSigTimeout_CMU_07" SG_ 963 NUM_TABLE 220;
BA_ "GenSigTimeout_CMU_08" SG_ 963 NUM_TABLE 220;
BA_ "GenSigTimeout_CMU_09" SG_ 963 NUM_TABLE 220;
BA_ "GenSigTimeout_CMU_10" SG_ 963 NUM_TABLE 220;
BA_ "GenSigTimeout_CMU_11" SG_ 963 NUM_TABLE 220;
BA_ "GenSigTimeout_CMU_12" SG_ 963 NUM_TABLE 220;
BA_ "GenSigTimeout_CMU_00" SG_ 963 NUM_TABLE 220;
BA_ "FlexKomSID" SG_ 963 NUM_TABLE 1014;
BA_ "FlexKomSigStartPos" SG_ 963 NUM_TABLE 35;
BA_ "FlexKomSigLaenge" SG_ 963 NUM_TABLE 4;
BA_ "FlexKomSigName" SG_ 963 NUM_TABLE "NUM_TABLE";
BA_ "FlexKomComment" SG_ 963 NUM_TABLE "Automatic numbering table";
BA_ "FlexKomIsMotorola" SG_ 963 NUM_TABLE 1;
BA_ "GenSigSendType" SG_ 963 NUMBERING_ENA 0;
BA_ "GenSigCycleTime" SG_ 963 NUMBERING_ENA 40;
BA_ "FlexKomSigStartValue" SG_ 963 NUMBERING_ENA "00h";
BA_ "GenSigTimeout_CMU_01" SG_ 963 NUMBERING_ENA 220;
BA_ "GenSigTimeout_CMU_02" SG_ 963 NUMBERING_ENA 220;
BA_ "GenSigTimeout_CMU_03" SG_ 963 NUMBERING_ENA 220;
BA_ "GenSigTimeout_CMU_04" SG_ 963 NUMBERING_ENA 220;
BA_ "GenSigTimeout_CMU_05" SG_ 963 NUMBERING_ENA 220;
BA_ "GenSigTimeout_CMU_06" SG_ 963 NUMBERING_ENA 220;
BA_ "GenSigTimeout_CMU_07" SG_ 963 NUMBERING_ENA 220;
BA_ "GenSigTimeout_CMU_08" SG_ 963 NUMBERING_ENA 220;
BA_ "GenSigTimeout_CMU_09" SG_ 963 NUMBERING_ENA 220;
BA_ "GenSigTimeout_CMU_10" SG_ 963 NUMBERING_ENA 220;
BA_ "GenSigTimeout_CMU_11" SG_ 963 NUMBERING_ENA 220;
BA_ "GenSigTimeout_CMU_12" SG_ 963 NUMBERING_ENA 220;
BA_ "GenSigTimeout_CMU_00" SG_ 963 NUMBERING_ENA 220;
BA_ "FlexKomSID" SG_ 963 NUMBERING_ENA 1012;
BA_ "FlexKomSigStartPos" SG_ 963 NUMBERING_ENA 26;
BA_ "FlexKomSigLaenge" SG_ 963 NUMBERING_ENA 1;
BA_ "FlexKomSigName" SG_ 963 NUMBERING_ENA "NUMBERING_ENA";
BA_ "FlexKomComment" SG_ 963 NUMBERING_ENA "Automatic numbering enable";
BA_ "FlexKomIsMotorola" SG_ 963 NUMBERING_ENA 1;
BA_ "GenSigSendType" SG_ 963 BMU_SHUTDOWN 0;
BA_ "GenSigCycleTime" SG_ 963 BMU_SHUTDOWN 40;
BA_ "FlexKomSigStartValue" SG_ 963 BMU_SHUTDOWN "00h";
BA_ "GenSigTimeout_CMU_01" SG_ 963 BMU_SHUTDOWN 220;
BA_ "GenSigTimeout_CMU_02" SG_ 963 BMU_SHUTDOWN 220;
BA_ "GenSigTimeout_CMU_03" SG_ 963 BMU_SHUTDOWN 220;
BA_ "GenSigTimeout_CMU_04" SG_ 963 BMU_SHUTDOWN 220;
BA_ "GenSigTimeout_CMU_05" SG_ 963 BMU_SHUTDOWN 220;
BA_ "GenSigTimeout_CMU_06" SG_ 963 BMU_SHUTDOWN 220;
BA_ "GenSigTimeout_CMU_07" SG_ 963 BMU_SHUTDOWN 220;
BA_ "GenSigTimeout_CMU_08" SG_ 963 BMU_SHUTDOWN 220;
BA_ "GenSigTimeout_CMU_09" SG_ 963 BMU_SHUTDOWN 220;
BA_ "GenSigTimeout_CMU_10" SG_ 963 BMU_SHUTDOWN 220;
BA_ "GenSigTimeout_CMU_11" SG_ 963 BMU_SHUTDOWN 220;
BA_ "GenSigTimeout_CMU_12" SG_ 963 BMU_SHUTDOWN 220;
BA_ "FlexKomSID" SG_ 963 BMU_SHUTDOWN 1009;
BA_ "FlexKomSigStartPos" SG_ 963 BMU_SHUTDOWN 25;
BA_ "FlexKomSigLaenge" SG_ 963 BMU_SHUTDOWN 1;
BA_ "FlexKomSigName" SG_ 963 BMU_SHUTDOWN "BMU_SHUTDOWN";
BA_ "FlexKomComment" SG_ 963 BMU_SHUTDOWN "BMU Shutdown";
BA_ "FlexKomIsMotorola" SG_ 963 BMU_SHUTDOWN 1;
BA_ "GenSigSendType" SG_ 963 BLC_DRV_CMPL 0;
BA_ "GenSigCycleTime" SG_ 963 BLC_DRV_CMPL 40;
BA_ "FlexKomSigStartValue" SG_ 963 BLC_DRV_CMPL "000000h";
BA_ "GenSigTimeout_CMU_01" SG_ 963 BLC_DRV_CMPL 220;
BA_ "GenSigTimeout_CMU_02" SG_ 963 BLC_DRV_CMPL 220;
BA_ "GenSigTimeout_CMU_03" SG_ 963 BLC_DRV_CMPL 220;
BA_ "GenSigTimeout_CMU_04" SG_ 963 BLC_DRV_CMPL 220;
BA_ "GenSigTimeout_CMU_05" SG_ 963 BLC_DRV_CMPL 220;
BA_ "GenSigTimeout_CMU_06" SG_ 963 BLC_DRV_CMPL 220;
BA_ "GenSigTimeout_CMU_07" SG_ 963 BLC_DRV_CMPL 220;
BA_ "GenSigTimeout_CMU_08" SG_ 963 BLC_DRV_CMPL 220;
BA_ "GenSigTimeout_CMU_09" SG_ 963 BLC_DRV_CMPL 220;
BA_ "GenSigTimeout_CMU_10" SG_ 963 BLC_DRV_CMPL 220;
BA_ "GenSigTimeout_CMU_11" SG_ 963 BLC_DRV_CMPL 220;
BA_ "GenSigTimeout_CMU_12" SG_ 963 BLC_DRV_CMPL 220;
BA_ "FlexKomSID" SG_ 963 BLC_DRV_CMPL 633;
BA_ "FlexKomSigStartPos" SG_ 963 BLC_DRV_CMPL 7;
BA_ "FlexKomSigLaenge" SG_ 963 BLC_DRV_CMPL 24;
BA_ "FlexKomSigName" SG_ 963 BLC_DRV_CMPL "BLC_DRV_RQ";
BA_ "FlexKomComment" SG_ 963 BLC_DRV_CMPL "Balancer drive enable packet";
BA_ "FlexKomIsMotorola" SG_ 963 BLC_DRV_CMPL 1;
BA_ "GenSigSendType" SG_ 963 BLC_DRV_ENA 0;
BA_ "GenSigCycleTime" SG_ 963 BLC_DRV_ENA 40;
BA_ "FlexKomSigStartValue" SG_ 963 BLC_DRV_ENA "000000h";
BA_ "GenSigTimeout_CMU_01" SG_ 963 BLC_DRV_ENA 220;
BA_ "GenSigTimeout_CMU_02" SG_ 963 BLC_DRV_ENA 220;
BA_ "GenSigTimeout_CMU_03" SG_ 963 BLC_DRV_ENA 220;
BA_ "GenSigTimeout_CMU_04" SG_ 963 BLC_DRV_ENA 220;
BA_ "GenSigTimeout_CMU_05" SG_ 963 BLC_DRV_ENA 220;
BA_ "GenSigTimeout_CMU_06" SG_ 963 BLC_DRV_ENA 220;
BA_ "GenSigTimeout_CMU_07" SG_ 963 BLC_DRV_ENA 220;
BA_ "GenSigTimeout_CMU_08" SG_ 963 BLC_DRV_ENA 220;
BA_ "GenSigTimeout_CMU_09" SG_ 963 BLC_DRV_ENA 220;
BA_ "GenSigTimeout_CMU_10" SG_ 963 BLC_DRV_ENA 220;
BA_ "GenSigTimeout_CMU_11" SG_ 963 BLC_DRV_ENA 220;
BA_ "GenSigTimeout_CMU_12" SG_ 963 BLC_DRV_ENA 220;
BA_ "FlexKomSID" SG_ 963 BLC_DRV_ENA 633;
BA_ "FlexKomSigStartPos" SG_ 963 BLC_DRV_ENA 7;
BA_ "FlexKomSigLaenge" SG_ 963 BLC_DRV_ENA 24;
BA_ "FlexKomSigName" SG_ 963 BLC_DRV_ENA "BLC_DRV_RQ";
BA_ "FlexKomComment" SG_ 963 BLC_DRV_ENA "Balancer drive enable packet";
BA_ "FlexKomIsMotorola" SG_ 963 BLC_DRV_ENA 1;
BA_ "GenSigSendType" SG_ 963 TRG_CELL_VOLT 0;
BA_ "GenSigCycleTime" SG_ 963 TRG_CELL_VOLT 40;
BA_ "FlexKomSigStartValue" SG_ 963 TRG_CELL_VOLT "000000h";
BA_ "GenSigTimeout_CMU_01" SG_ 963 TRG_CELL_VOLT 220;
BA_ "GenSigTimeout_CMU_02" SG_ 963 TRG_CELL_VOLT 220;
BA_ "GenSigTimeout_CMU_03" SG_ 963 TRG_CELL_VOLT 220;
BA_ "GenSigTimeout_CMU_04" SG_ 963 TRG_CELL_VOLT 220;
BA_ "GenSigTimeout_CMU_05" SG_ 963 TRG_CELL_VOLT 220;
BA_ "GenSigTimeout_CMU_06" SG_ 963 TRG_CELL_VOLT 220;
BA_ "GenSigTimeout_CMU_07" SG_ 963 TRG_CELL_VOLT 220;
BA_ "GenSigTimeout_CMU_08" SG_ 963 TRG_CELL_VOLT 220;
BA_ "GenSigTimeout_CMU_09" SG_ 963 TRG_CELL_VOLT 220;
BA_ "GenSigTimeout_CMU_10" SG_ 963 TRG_CELL_VOLT 220;
BA_ "GenSigTimeout_CMU_11" SG_ 963 TRG_CELL_VOLT 220;
BA_ "GenSigTimeout_CMU_12" SG_ 963 TRG_CELL_VOLT 220;
BA_ "FlexKomSID" SG_ 963 TRG_CELL_VOLT 633;
BA_ "FlexKomSigStartPos" SG_ 963 TRG_CELL_VOLT 7;
BA_ "FlexKomSigLaenge" SG_ 963 TRG_CELL_VOLT 24;
BA_ "FlexKomSigName" SG_ 963 TRG_CELL_VOLT "BLC_DRV_RQ";
BA_ "FlexKomComment" SG_ 963 TRG_CELL_VOLT "Balancer drive enable packet";
BA_ "FlexKomIsMotorola" SG_ 963 TRG_CELL_VOLT 1;
VAL_ 1713 MODULE_TEMP_06_11 255 "SNA" ;
VAL_ 1713 MODULE_TEMP_05_11 255 "SNA" ;
VAL_ 1713 MODULE_TEMP_04_11 255 "SNA" ;
VAL_ 1713 MODULE_TEMP_03_11 255 "SNA" ;
VAL_ 1713 MODULE_TEMP_02_11 255 "SNA" ;
VAL_ 1713 MODULE_TEMP_01_11 255 "SNA" ;
VAL_ 1713 NUM_TABLE_VALUE_11 15 "SIGNAL_DEFAULT" 14 "BATTERY_PACK_TYPE_14" 13 "BATTERY_PACK_TYPE_13" 12 "BATTERY_PACK_TYPE_12" 11 "BATTERY_PACK_TYPE_11" 10 "BATTERY_PACK_TYPE_10" 9 "BATTERY_PACK_TYPE_9" 8 "BATTERY_PACK_TYPE_8" 7 "BATTERY_PACK_TYPE_7" 6 "BATTERY_PACK_TYPE_6" 5 "BATTERY_PACK_TYPE_5" 4 "BATTERY_PACK_TYPE_4" 3 "BATTERY_PACK_TYPE_3" 2 "BATTERY_PACK_TYPE_2" 1 "BATTERY_PACK_TYPE_1" 0 "BATTERY_PACK_TYPE_0" ;
VAL_ 1697 MODULE_TEMP_06_10 255 "SNA" ;
VAL_ 1697 MODULE_TEMP_05_10 255 "SNA" ;
VAL_ 1697 MODULE_TEMP_04_10 255 "SNA" ;
VAL_ 1697 MODULE_TEMP_03_10 255 "SNA" ;
VAL_ 1697 MODULE_TEMP_02_10 255 "SNA" ;
VAL_ 1697 MODULE_TEMP_01_10 255 "SNA" ;
VAL_ 1697 NUM_TABLE_VALUE_10 15 "SIGNAL_DEFAULT" 14 "BATTERY_PACK_TYPE_14" 13 "BATTERY_PACK_TYPE_13" 12 "BATTERY_PACK_TYPE_12" 11 "BATTERY_PACK_TYPE_11" 10 "BATTERY_PACK_TYPE_10" 9 "BATTERY_PACK_TYPE_9" 8 "BATTERY_PACK_TYPE_8" 7 "BATTERY_PACK_TYPE_7" 6 "BATTERY_PACK_TYPE_6" 5 "BATTERY_PACK_TYPE_5" 4 "BATTERY_PACK_TYPE_4" 3 "BATTERY_PACK_TYPE_3" 2 "BATTERY_PACK_TYPE_2" 1 "BATTERY_PACK_TYPE_1" 0 "BATTERY_PACK_TYPE_0" ;
VAL_ 1681 MODULE_TEMP_06_09 255 "SNA" ;
VAL_ 1681 MODULE_TEMP_05_09 255 "SNA" ;
VAL_ 1681 MODULE_TEMP_04_09 255 "SNA" ;
VAL_ 1681 MODULE_TEMP_03_09 255 "SNA" ;
VAL_ 1681 MODULE_TEMP_02_09 255 "SNA" ;
VAL_ 1681 MODULE_TEMP_01_09 255 "SNA" ;
VAL_ 1681 NUM_TABLE_VALUE_09 15 "SIGNAL_DEFAULT" 14 "BATTERY_PACK_TYPE_14" 13 "BATTERY_PACK_TYPE_13" 12 "BATTERY_PACK_TYPE_12" 11 "BATTERY_PACK_TYPE_11" 10 "BATTERY_PACK_TYPE_10" 9 "BATTERY_PACK_TYPE_9" 8 "BATTERY_PACK_TYPE_8" 7 "BATTERY_PACK_TYPE_7" 6 "BATTERY_PACK_TYPE_6" 5 "BATTERY_PACK_TYPE_5" 4 "BATTERY_PACK_TYPE_4" 3 "BATTERY_PACK_TYPE_3" 2 "BATTERY_PACK_TYPE_2" 1 "BATTERY_PACK_TYPE_1" 0 "BATTERY_PACK_TYPE_0" ;
VAL_ 1665 MODULE_TEMP_06_08 255 "SNA" ;
VAL_ 1665 MODULE_TEMP_05_08 255 "SNA" ;
VAL_ 1665 MODULE_TEMP_04_08 255 "SNA" ;
VAL_ 1665 MODULE_TEMP_03_08 255 "SNA" ;
VAL_ 1665 MODULE_TEMP_02_08 255 "SNA" ;
VAL_ 1665 MODULE_TEMP_01_08 255 "SNA" ;
VAL_ 1665 NUM_TABLE_VALUE_08 15 "SIGNAL_DEFAULT" 14 "BATTERY_PACK_TYPE_14" 13 "BATTERY_PACK_TYPE_13" 12 "BATTERY_PACK_TYPE_12" 11 "BATTERY_PACK_TYPE_11" 10 "BATTERY_PACK_TYPE_10" 9 "BATTERY_PACK_TYPE_9" 8 "BATTERY_PACK_TYPE_8" 7 "BATTERY_PACK_TYPE_7" 6 "BATTERY_PACK_TYPE_6" 5 "BATTERY_PACK_TYPE_5" 4 "BATTERY_PACK_TYPE_4" 3 "BATTERY_PACK_TYPE_3" 2 "BATTERY_PACK_TYPE_2" 1 "BATTERY_PACK_TYPE_1" 0 "BATTERY_PACK_TYPE_0" ;
VAL_ 1649 MODULE_TEMP_06_07 255 "SNA" ;
VAL_ 1649 MODULE_TEMP_05_07 255 "SNA" ;
VAL_ 1649 MODULE_TEMP_04_07 255 "SNA" ;
VAL_ 1649 MODULE_TEMP_03_07 255 "SNA" ;
VAL_ 1649 MODULE_TEMP_02_07 255 "SNA" ;
VAL_ 1649 MODULE_TEMP_01_07 255 "SNA" ;
VAL_ 1649 NUM_TABLE_VALUE_07 15 "SIGNAL_DEFAULT" 14 "BATTERY_PACK_TYPE_14" 13 "BATTERY_PACK_TYPE_13" 12 "BATTERY_PACK_TYPE_12" 11 "BATTERY_PACK_TYPE_11" 10 "BATTERY_PACK_TYPE_10" 9 "BATTERY_PACK_TYPE_9" 8 "BATTERY_PACK_TYPE_8" 7 "BATTERY_PACK_TYPE_7" 6 "BATTERY_PACK_TYPE_6" 5 "BATTERY_PACK_TYPE_5" 4 "BATTERY_PACK_TYPE_4" 3 "BATTERY_PACK_TYPE_3" 2 "BATTERY_PACK_TYPE_2" 1 "BATTERY_PACK_TYPE_1" 0 "BATTERY_PACK_TYPE_0" ;
VAL_ 1633 MODULE_TEMP_06_06 255 "SNA" ;
VAL_ 1633 MODULE_TEMP_05_06 255 "SNA" ;
VAL_ 1633 MODULE_TEMP_04_06 255 "SNA" ;
VAL_ 1633 MODULE_TEMP_03_06 255 "SNA" ;
VAL_ 1633 MODULE_TEMP_02_06 255 "SNA" ;
VAL_ 1633 MODULE_TEMP_01_06 255 "SNA" ;
VAL_ 1633 NUM_TABLE_VALUE_06 15 "SIGNAL_DEFAULT" 14 "BATTERY_PACK_TYPE_14" 13 "BATTERY_PACK_TYPE_13" 12 "BATTERY_PACK_TYPE_12" 11 "BATTERY_PACK_TYPE_11" 10 "BATTERY_PACK_TYPE_10" 9 "BATTERY_PACK_TYPE_9" 8 "BATTERY_PACK_TYPE_8" 7 "BATTERY_PACK_TYPE_7" 6 "BATTERY_PACK_TYPE_6" 5 "BATTERY_PACK_TYPE_5" 4 "BATTERY_PACK_TYPE_4" 3 "BATTERY_PACK_TYPE_3" 2 "BATTERY_PACK_TYPE_2" 1 "BATTERY_PACK_TYPE_1" 0 "BATTERY_PACK_TYPE_0" ;
VAL_ 1617 MODULE_TEMP_06_05 255 "SNA" ;
VAL_ 1617 MODULE_TEMP_05_05 255 "SNA" ;
VAL_ 1617 MODULE_TEMP_04_05 255 "SNA" ;
VAL_ 1617 MODULE_TEMP_03_05 255 "SNA" ;
VAL_ 1617 MODULE_TEMP_02_05 255 "SNA" ;
VAL_ 1617 MODULE_TEMP_01_05 255 "SNA" ;
VAL_ 1617 NUM_TABLE_VALUE_05 15 "SIGNAL_DEFAULT" 14 "BATTERY_PACK_TYPE_14" 13 "BATTERY_PACK_TYPE_13" 12 "BATTERY_PACK_TYPE_12" 11 "BATTERY_PACK_TYPE_11" 10 "BATTERY_PACK_TYPE_10" 9 "BATTERY_PACK_TYPE_9" 8 "BATTERY_PACK_TYPE_8" 7 "BATTERY_PACK_TYPE_7" 6 "BATTERY_PACK_TYPE_6" 5 "BATTERY_PACK_TYPE_5" 4 "BATTERY_PACK_TYPE_4" 3 "BATTERY_PACK_TYPE_3" 2 "BATTERY_PACK_TYPE_2" 1 "BATTERY_PACK_TYPE_1" 0 "BATTERY_PACK_TYPE_0" ;
VAL_ 1601 MODULE_TEMP_06_04 255 "SNA" ;
VAL_ 1601 MODULE_TEMP_05_04 255 "SNA" ;
VAL_ 1601 MODULE_TEMP_04_04 255 "SNA" ;
VAL_ 1601 MODULE_TEMP_03_04 255 "SNA" ;
VAL_ 1601 MODULE_TEMP_02_04 255 "SNA" ;
VAL_ 1601 MODULE_TEMP_01_04 255 "SNA" ;
VAL_ 1601 NUM_TABLE_VALUE_04 15 "SIGNAL_DEFAULT" 14 "BATTERY_PACK_TYPE_14" 13 "BATTERY_PACK_TYPE_13" 12 "BATTERY_PACK_TYPE_12" 11 "BATTERY_PACK_TYPE_11" 10 "BATTERY_PACK_TYPE_10" 9 "BATTERY_PACK_TYPE_9" 8 "BATTERY_PACK_TYPE_8" 7 "BATTERY_PACK_TYPE_7" 6 "BATTERY_PACK_TYPE_6" 5 "BATTERY_PACK_TYPE_5" 4 "BATTERY_PACK_TYPE_4" 3 "BATTERY_PACK_TYPE_3" 2 "BATTERY_PACK_TYPE_2" 1 "BATTERY_PACK_TYPE_1" 0 "BATTERY_PACK_TYPE_0" ;
VAL_ 1585 MODULE_TEMP_06_03 255 "SNA" ;
VAL_ 1585 MODULE_TEMP_05_03 255 "SNA" ;
VAL_ 1585 MODULE_TEMP_04_03 255 "SNA" ;
VAL_ 1585 MODULE_TEMP_03_03 255 "SNA" ;
VAL_ 1585 MODULE_TEMP_02_03 255 "SNA" ;
VAL_ 1585 MODULE_TEMP_01_03 255 "SNA" ;
VAL_ 1585 NUM_TABLE_VALUE_03 15 "SIGNAL_DEFAULT" 14 "BATTERY_PACK_TYPE_14" 13 "BATTERY_PACK_TYPE_13" 12 "BATTERY_PACK_TYPE_12" 11 "BATTERY_PACK_TYPE_11" 10 "BATTERY_PACK_TYPE_10" 9 "BATTERY_PACK_TYPE_9" 8 "BATTERY_PACK_TYPE_8" 7 "BATTERY_PACK_TYPE_7" 6 "BATTERY_PACK_TYPE_6" 5 "BATTERY_PACK_TYPE_5" 4 "BATTERY_PACK_TYPE_4" 3 "BATTERY_PACK_TYPE_3" 2 "BATTERY_PACK_TYPE_2" 1 "BATTERY_PACK_TYPE_1" 0 "BATTERY_PACK_TYPE_0" ;
VAL_ 1569 MODULE_TEMP_06_02 255 "SNA" ;
VAL_ 1569 MODULE_TEMP_05_02 255 "SNA" ;
VAL_ 1569 MODULE_TEMP_04_02 255 "SNA" ;
VAL_ 1569 MODULE_TEMP_03_02 255 "SNA" ;
VAL_ 1569 MODULE_TEMP_02_02 255 "SNA" ;
VAL_ 1569 MODULE_TEMP_01_02 255 "SNA" ;
VAL_ 1569 NUM_TABLE_VALUE_02 15 "SIGNAL_DEFAULT" 14 "BATTERY_PACK_TYPE_14" 13 "BATTERY_PACK_TYPE_13" 12 "BATTERY_PACK_TYPE_12" 11 "BATTERY_PACK_TYPE_11" 10 "BATTERY_PACK_TYPE_10" 9 "BATTERY_PACK_TYPE_9" 8 "BATTERY_PACK_TYPE_8" 7 "BATTERY_PACK_TYPE_7" 6 "BATTERY_PACK_TYPE_6" 5 "BATTERY_PACK_TYPE_5" 4 "BATTERY_PACK_TYPE_4" 3 "BATTERY_PACK_TYPE_3" 2 "BATTERY_PACK_TYPE_2" 1 "BATTERY_PACK_TYPE_1" 0 "BATTERY_PACK_TYPE_0" ;
VAL_ 1553 MODULE_TEMP_06_01 255 "SNA" ;
VAL_ 1553 MODULE_TEMP_05_01 255 "SNA" ;
VAL_ 1553 MODULE_TEMP_04_01 255 "SNA" ;
VAL_ 1553 MODULE_TEMP_03_01 255 "SNA" ;
VAL_ 1553 MODULE_TEMP_02_01 255 "SNA" ;
VAL_ 1553 MODULE_TEMP_01_01 255 "SNA" ;
VAL_ 1553 NUM_TABLE_VALUE_01 15 "SIGNAL_DEFAULT" 14 "BATTERY_PACK_TYPE_14" 13 "BATTERY_PACK_TYPE_13" 12 "BATTERY_PACK_TYPE_12" 11 "BATTERY_PACK_TYPE_11" 10 "BATTERY_PACK_TYPE_10" 9 "BATTERY_PACK_TYPE_9" 8 "BATTERY_PACK_TYPE_8" 7 "BATTERY_PACK_TYPE_7" 6 "BATTERY_PACK_TYPE_6" 5 "BATTERY_PACK_TYPE_5" 4 "BATTERY_PACK_TYPE_4" 3 "BATTERY_PACK_TYPE_3" 2 "BATTERY_PACK_TYPE_2" 1 "BATTERY_PACK_TYPE_1" 0 "BATTERY_PACK_TYPE_0" ;
VAL_ 963 NUM_TABLE 15 "SIGNAL_DEFAULT" 14 "BATTERY_PACK_TYPE_14" 13 "BATTERY_PACK_TYPE_13" 12 "BATTERY_PACK_TYPE_12" 11 "BATTERY_PACK_TYPE_11" 10 "BATTERY_PACK_TYPE_10" 9 "BATTERY_PACK_TYPE_9" 8 "BATTERY_PACK_TYPE_8" 7 "BATTERY_PACK_TYPE_7" 6 "BATTERY_PACK_TYPE_6" 5 "BATTERY_PACK_TYPE_5" 4 "BATTERY_PACK_TYPE_4" 3 "BATTERY_PACK_TYPE_3" 2 "BATTERY_PACK_TYPE_2" 1 "BATTERY_PACK_TYPE_1" 0 "BATTERY_PACK_TYPE_0" ;
VAL_ 963 TRG_CELL_VOLT 65535 "SNA" ;
